VERSION "HNNBNNNYNNNNNNNNNNNNNNNNNNNNNNNNNNNNNNNNNN/4/%%%/4/'%**4NNN///"

NS_ :

BS_ :

BU_:  Airbag BAP_Tester ICAS1_Gateway ICAS1_KommunikationsServer LE1 LE2 Motor_BEV Schaltbetaetigung

BO_ 514 Daempfer_03: 32 ICAS1_Gateway
 SG_ DR_Aufbaubeschleunigung_HR  : 12|10@1+ (0.032700,-15.696000) [-15.696000|15.696000] "Unit_MeterPerSeconSquar" Motor_BEV
 SG_ DR_Aufbaubeschleunigung_VR  : 22|10@1+ (0.032700,-15.696000) [-15.696000|15.696000] "Unit_MeterPerSeconSquar" Motor_BEV
 SG_ DR_Aufbaubeschleunigung_VL  : 32|10@1+ (0.032700,-15.696000) [-15.696000|15.696000] "Unit_MeterPerSeconSquar" Motor_BEV
 SG_ DR_Aufbaubeschleunigung_HL  : 42|10@1+ (0.032700,-15.696000) [-15.696000|15.696000] "Unit_MeterPerSeconSquar" Motor_BEV
 SG_ DR_Funktionsstatus  : 52|2@1+ (1.000000,0.000000) [0.000000|3.000000] "" Vector__XXX
 SG_ DR_Drehwinkelsensortausch_VL  : 72|2@1+ (1.000000,0.000000) [1.000000|3.000000] "" Vector__XXX
 SG_ DR_Drehwinkelsensortausch_VR  : 74|2@1+ (1.000000,0.000000) [1.000000|3.000000] "" Vector__XXX
 SG_ DR_Drehwinkelsensortausch_HL  : 76|2@1+ (1.000000,0.000000) [1.000000|3.000000] "" Vector__XXX
 SG_ DR_Drehwinkelsensortausch_HR  : 78|2@1+ (1.000000,0.000000) [1.000000|3.000000] "" Vector__XXX
 SG_ DR_Drehwinkel_VL  : 80|12@1+ (0.088000,0.000000) [0.000000|359.920000] "" Vector__XXX
 SG_ DR_Drehwinkel_VR  : 92|12@1+ (0.088000,0.000000) [0.000000|359.920000] "" Vector__XXX
 SG_ DR_Drehwinkel_HL  : 104|12@1+ (0.088000,0.000000) [0.000000|359.920000] "" Vector__XXX
 SG_ DR_Drehwinkel_HR  : 116|12@1+ (0.088000,0.000000) [0.000000|359.920000] "" Vector__XXX

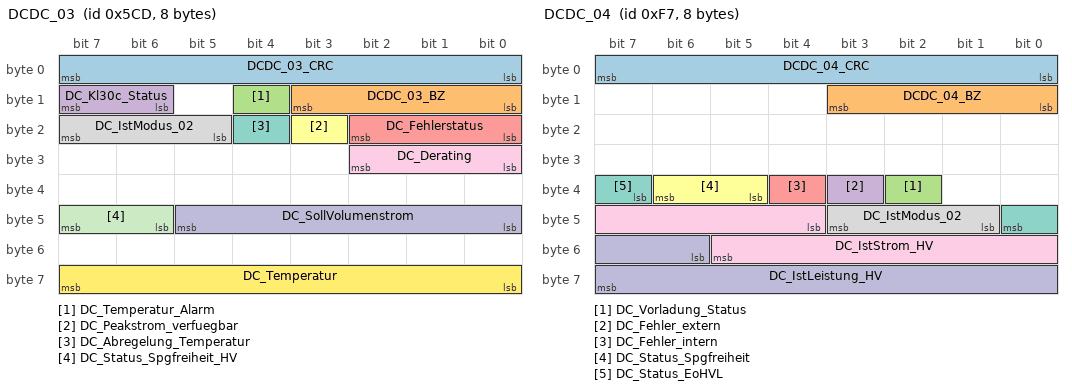
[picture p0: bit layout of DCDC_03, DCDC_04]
BO_ 1485 DCDC_03: 8 ICAS1_Gateway
 SG_ DCDC_03_CRC  : 0|8@1+ (1.000000,0.000000) [0.000000|255.000000] "" Motor_BEV
 SG_ DCDC_03_BZ  : 8|4@1+ (1.000000,0.000000) [0.000000|15.000000] "" Motor_BEV
 SG_ DC_Temperatur_Alarm  : 12|1@1+ (1.000000,0.000000) [0.000000|1.000000] "" Vector__XXX
 SG_ DC_Kl30c_Status  : 14|2@1+ (1.000000,0.000000) [0.000000|3.000000] "" Motor_BEV
 SG_ DC_Fehlerstatus  : 16|3@1+ (1.000000,0.000000) [0.000000|7.000000] "" Vector__XXX
 SG_ DC_Peakstrom_verfuegbar  : 19|1@1+ (1.000000,0.000000) [0.000000|1.000000] "" Vector__XXX
 SG_ DC_Abregelung_Temperatur  : 20|1@1+ (1.000000,0.000000) [0.000000|1.000000] "" Vector__XXX
 SG_ DC_IstModus_02  : 21|3@1+ (1.000000,0.000000) [0.000000|7.000000] "" Vector__XXX
 SG_ DC_Derating  : 24|3@1+ (1.000000,0.000000) [0.000000|7.000000] "" Vector__XXX
 SG_ DC_SollVolumenstrom  : 40|6@1+ (0.500000,0.000000) [0.000000|30.500000] "Unit_LiterPerMinut" Motor_BEV
 SG_ DC_Status_Spgfreiheit_HV  : 46|2@1+ (1.000000,0.000000) [0.000000|3.000000] "" Vector__XXX
 SG_ DC_Temperatur  : 56|8@1+ (1.000000,-40.000000) [-40.000000|213.000000] "Unit_DegreCelsi" Motor_BEV

BO_ 247 DCDC_04: 8 ICAS1_Gateway
 SG_ DCDC_04_CRC  : 0|8@1+ (1.000000,0.000000) [0.000000|255.000000] "" Vector__XXX
 SG_ DCDC_04_BZ  : 8|4@1+ (1.000000,0.000000) [0.000000|15.000000] "" Vector__XXX
 SG_ DC_Vorladung_Status  : 34|1@1+ (1.000000,0.000000) [0.000000|1.000000] "" Motor_BEV
 SG_ DC_Fehler_extern  : 35|1@1+ (1.000000,0.000000) [0.000000|1.000000] "" Motor_BEV
 SG_ DC_Fehler_intern  : 36|1@1+ (1.000000,0.000000) [0.000000|1.000000] "" Motor_BEV
 SG_ DC_Status_Spgfreiheit  : 37|2@1+ (1.000000,0.000000) [0.000000|3.000000] "" Motor_BEV
 SG_ DC_Status_EoHVL  : 39|2@1+ (1.000000,0.000000) [0.000000|3.000000] "" Motor_BEV
 SG_ DC_IstModus_02  : 41|3@1+ (1.000000,0.000000) [0.000000|7.000000] "" Motor_BEV
 SG_ DC_IstStrom_HV  : 44|10@1+ (0.100000,-51.100000) [-51.100000|51.000000] "Unit_Amper" Motor_BEV
 SG_ DC_IstLeistung_HV  : 54|10@1+ (10.000000,-4000.000000) [-4000.000000|6210.000000] "Unit_Watt" Motor_BEV

BO_ 2617027088 DEV_Airbag_ASM_01: 8 Airbag
 SG_ DEV_Airbag_ASM_01_Data  : 0|64@1+ (1.000000,0.000000) [0.000000|18446744073709551616.000000] "" Vector__XXX

BO_ 2617027072 DEV_Airbag_Resp_00: 8 Airbag
 SG_ DEV_Airbag_Resp_00_Data  : 0|64@1+ (1.000000,0.000000) [0.000000|18446744073709551616.000000] "" Vector__XXX

BO_ 2617027073 DEV_Airbag_Resp_01: 8 Airbag
 SG_ DEV_Airbag_Resp_01_Data  : 0|64@1+ (1.000000,0.000000) [0.000000|18446744073709551616.000000] "" Vector__XXX

BO_ 2617027074 DEV_Airbag_Resp_02: 8 Airbag
 SG_ DEV_Airbag_Resp_02_Data  : 0|64@1+ (1.000000,0.000000) [0.000000|18446744073709551616.000000] "" Vector__XXX

BO_ 2617027075 DEV_Airbag_Resp_03: 8 Airbag
 SG_ DEV_Airbag_Resp_03_Data  : 0|64@1+ (1.000000,0.000000) [0.000000|18446744073709551616.000000] "" Vector__XXX

BO_ 2617027076 DEV_Airbag_Resp_04: 8 Airbag
 SG_ DEV_Airbag_Resp_04_Data  : 0|64@1+ (1.000000,0.000000) [0.000000|18446744073709551616.000000] "" Vector__XXX

BO_ 2617027077 DEV_Airbag_Resp_05: 8 Airbag
 SG_ DEV_Airbag_Resp_05_Data  : 0|64@1+ (1.000000,0.000000) [0.000000|18446744073709551616.000000] "" Vector__XXX

BO_ 2617027078 DEV_Airbag_Resp_06: 8 Airbag
 SG_ DEV_Airbag_Resp_06_Data  : 0|64@1+ (1.000000,0.000000) [0.000000|18446744073709551616.000000] "" Vector__XXX

BO_ 2617027079 DEV_Airbag_Resp_07: 8 Airbag
 SG_ DEV_Airbag_Resp_07_Data  : 0|64@1+ (1.000000,0.000000) [0.000000|18446744073709551616.000000] "" Vector__XXX

BO_ 2617027080 DEV_Airbag_Resp_08: 8 Airbag
 SG_ DEV_Airbag_Resp_08_Data  : 0|64@1+ (1.000000,0.000000) [0.000000|18446744073709551616.000000] "" Vector__XXX

BO_ 2617027081 DEV_Airbag_Resp_09: 8 Airbag
 SG_ DEV_Airbag_Resp_09_Data  : 0|64@1+ (1.000000,0.000000) [0.000000|18446744073709551616.000000] "" Vector__XXX

BO_ 2617027082 DEV_Airbag_Resp_10: 8 Airbag
 SG_ DEV_Airbag_Resp_10_Data  : 0|64@1+ (1.000000,0.000000) [0.000000|18446744073709551616.000000] "" Vector__XXX

BO_ 2617027083 DEV_Airbag_Resp_11: 8 Airbag
 SG_ DEV_Airbag_Resp_11_Data  : 0|64@1+ (1.000000,0.000000) [0.000000|18446744073709551616.000000] "" Vector__XXX

BO_ 2617154048 DEV_Waehlhebel_Resp_00: 8 Schaltbetaetigung
 SG_ DEV_Waehlhebel_Resp_00_Data  : 0|64@1+ (1.000000,0.000000) [0.000000|18446744073709551616.000000] "" Vector__XXX

BO_ 2617154049 DEV_Waehlhebel_Resp_01: 8 Schaltbetaetigung
 SG_ DEV_Waehlhebel_Resp_01_Data  : 0|64@1+ (1.000000,0.000000) [0.000000|18446744073709551616.000000] "" Vector__XXX

BO_ 2617154050 DEV_Waehlhebel_Resp_02: 8 Schaltbetaetigung
 SG_ DEV_Waehlhebel_Resp_02_Data  : 0|64@1+ (1.000000,0.000000) [0.000000|18446744073709551616.000000] "" Vector__XXX

BO_ 2617154051 DEV_Waehlhebel_Resp_03: 8 Schaltbetaetigung
 SG_ DEV_Waehlhebel_Resp_03_Data  : 0|64@1+ (1.000000,0.000000) [0.000000|18446744073709551616.000000] "" Vector__XXX

BO_ 2617154052 DEV_Waehlhebel_Resp_04: 8 Schaltbetaetigung
 SG_ DEV_Waehlhebel_Resp_04_Data  : 0|64@1+ (1.000000,0.000000) [0.000000|18446744073709551616.000000] "" Vector__XXX

BO_ 2617154053 DEV_Waehlhebel_Resp_05: 8 Schaltbetaetigung
 SG_ DEV_Waehlhebel_Resp_05_Data  : 0|64@1+ (1.000000,0.000000) [0.000000|18446744073709551616.000000] "" Vector__XXX

BO_ 2549876269 Diag_Waehlhebel_Req: 8 Motor_BEV
 SG_ Diag_Waehlhebel_Req_Data  : 0|64@1+ (1.000000,0.000000) [0.000000|18446744073709551616.000000] "" Schaltbetaetigung

BO_ 2550007341 Diag_Waehlhebel_Resp: 8 Schaltbetaetigung
 SG_ Diag_Waehlhebel_Resp_Data  : 0|64@1+ (1.000000,0.000000) [0.000000|18446744073709551616.000000] "" Motor_BEV

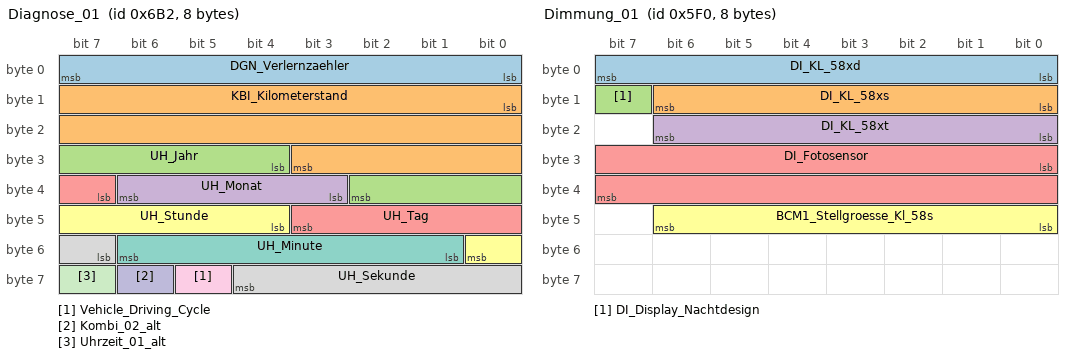
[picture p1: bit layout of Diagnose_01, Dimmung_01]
BO_ 1714 Diagnose_01: 8 ICAS1_Gateway
 SG_ DGN_Verlernzaehler  : 0|8@1+ (1.000000,0.000000) [0.000000|254.000000] "" Airbag LE1 LE2 Motor_BEV
 SG_ KBI_Kilometerstand  : 8|20@1+ (1.000000,0.000000) [0.000000|1048573.000000] "Unit_KiloMeter" Airbag LE1 LE2 Motor_BEV
 SG_ UH_Jahr  : 28|7@1+ (1.000000,2000.000000) [2000.000000|2127.000000] "Unit_Year" Airbag LE1 LE2 Motor_BEV
 SG_ UH_Monat  : 35|4@1+ (1.000000,0.000000) [1.000000|12.000000] "Unit_Month" Airbag LE1 LE2 Motor_BEV
 SG_ UH_Tag  : 39|5@1+ (1.000000,0.000000) [1.000000|31.000000] "Unit_Day" Airbag LE1 LE2 Motor_BEV
 SG_ UH_Stunde  : 44|5@1+ (1.000000,0.000000) [0.000000|23.000000] "Unit_Hours" Airbag LE1 LE2 Motor_BEV
 SG_ UH_Minute  : 49|6@1+ (1.000000,0.000000) [0.000000|59.000000] "Unit_Minut" Airbag LE1 LE2 Motor_BEV
 SG_ UH_Sekunde  : 55|6@1+ (1.000000,0.000000) [0.000000|59.000000] "Unit_Secon" Airbag LE1 LE2 Motor_BEV
 SG_ Vehicle_Driving_Cycle  : 61|1@1+ (1.000000,0.000000) [0.000000|1.000000] "" Airbag
 SG_ Kombi_02_alt  : 62|1@1+ (1.000000,0.000000) [0.000000|1.000000] "" Vector__XXX
 SG_ Uhrzeit_01_alt  : 63|1@1+ (1.000000,0.000000) [0.000000|1.000000] "" Vector__XXX

BO_ 851 DiETa_01: 8 ICAS1_Gateway
 SG_ DiETas_01_CRC  : 0|8@1+ (1.000000,0.000000) [0.000000|255.000000] "" Airbag
 SG_ DiETas_01_BZ  : 8|4@1+ (1.000000,0.000000) [0.000000|15.000000] "" Airbag
 SG_ DiETa_Reserve_Byte2_4  : 12|1@1+ (1.000000,0.000000) [0.000000|1.000000] "" Vector__XXX
 SG_ DiETa_Status  : 13|2@1+ (1.000000,0.000000) [0.000000|3.000000] "" Airbag
 SG_ DiETa_ResponseError  : 15|1@1+ (1.000000,0.000000) [0.000000|1.000000] "" Vector__XXX
 SG_ DiETa_Car  : 16|2@1+ (1.000000,0.000000) [0.000000|3.000000] "" Vector__XXX
 SG_ DiETa_Klima  : 18|2@1+ (1.000000,0.000000) [0.000000|3.000000] "" Vector__XXX
 SG_ DiETa_Mode  : 20|2@1+ (1.000000,0.000000) [0.000000|3.000000] "" Vector__XXX
 SG_ DiETa_Parken  : 22|2@1+ (1.000000,0.000000) [0.000000|3.000000] "" Vector__XXX
 SG_ DiETa_FSH_Taste  : 24|2@1+ (1.000000,0.000000) [0.000000|3.000000] "" Vector__XXX
 SG_ DiETa_HSH_Taste  : 26|2@1+ (1.000000,0.000000) [0.000000|3.000000] "" Vector__XXX
 SG_ DiETa_Warnblink_Taste  : 28|2@1+ (1.000000,0.000000) [0.000000|3.000000] "" Vector__XXX
 SG_ DiETa_FAS_Stufe  : 30|2@1+ (1.000000,0.000000) [0.000000|3.000000] "" Vector__XXX
 SG_ DiETa_PAO_ON_Status  : 32|2@1+ (1.000000,0.000000) [0.000000|3.000000] "" Airbag
 SG_ DiETa_PAO_OFF_Status  : 34|2@1+ (1.000000,0.000000) [0.000000|3.000000] "" Airbag
 SG_ DiETa_Defrost_Taste  : 36|2@1+ (1.000000,0.000000) [0.000000|3.000000] "" Vector__XXX
 SG_ DiETa_Reserve_Byte5_6  : 38|2@1+ (1.000000,0.000000) [0.000000|3.000000] "" Vector__XXX
 SG_ DiETa_Lock_Unlock_Taste  : 40|3@1+ (1.000000,0.000000) [0.000000|7.000000] "" Vector__XXX
 SG_ DiETa_Mode_roh  : 43|1@1+ (1.000000,0.000000) [0.000000|1.000000] "" Vector__XXX
 SG_ DiETa_Reserve_Byte6_3  : 44|4@1+ (1.000000,0.000000) [0.000000|15.000000] "" Vector__XXX
 SG_ DiETa_Reserve_Byte7  : 48|8@1+ (1.000000,0.000000) [0.000000|255.000000] "" Vector__XXX
 SG_ DiETa_Reserve_Byte8  : 56|8@1+ (1.000000,0.000000) [0.000000|255.000000] "" Vector__XXX

BO_ 1520 Dimmung_01: 8 ICAS1_Gateway
 SG_ DI_KL_58xd  : 0|8@1+ (1.000000,0.000000) [0.000000|253.000000] "" Airbag Schaltbetaetigung
 SG_ DI_KL_58xs  : 8|7@1+ (1.000000,0.000000) [0.000000|100.000000] "Unit_PerCent" Airbag
 SG_ DI_Display_Nachtdesign  : 15|1@1+ (1.000000,0.000000) [0.000000|1.000000] "" Vector__XXX
 SG_ DI_KL_58xt  : 16|7@1+ (1.000000,0.000000) [0.000000|100.000000] "Unit_PerCent" Airbag Schaltbetaetigung
 SG_ DI_Fotosensor  : 24|16@1+ (1.000000,0.000000) [0.000000|65535.000000] "" Vector__XXX
 SG_ BCM1_Stellgroesse_Kl_58s  : 40|7@1+ (1.000000,0.000000) [0.000000|100.000000] "" Vector__XXX

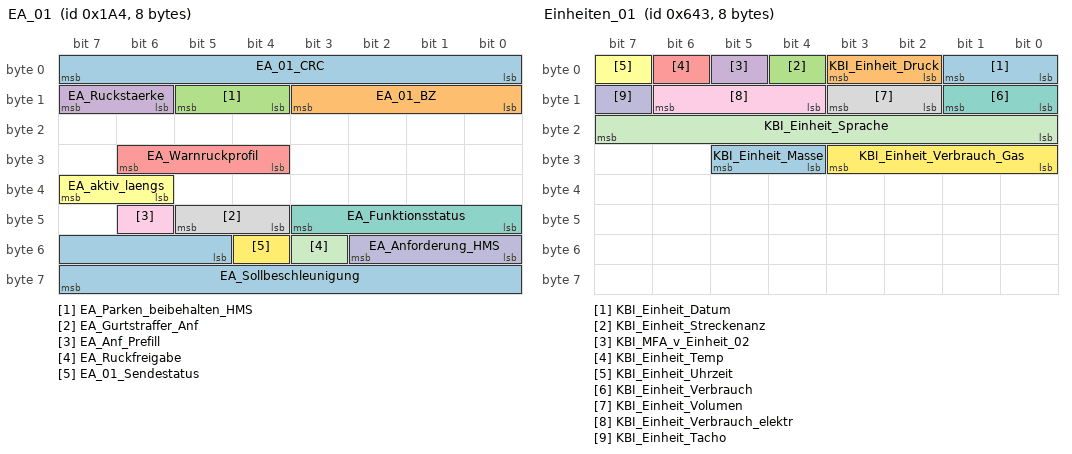
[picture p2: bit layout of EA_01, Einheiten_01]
BO_ 420 EA_01: 8 ICAS1_Gateway
 SG_ EA_01_CRC  : 0|8@1+ (1.000000,0.000000) [0.000000|255.000000] "" Motor_BEV
 SG_ EA_01_BZ  : 8|4@1+ (1.000000,0.000000) [0.000000|15.000000] "" Motor_BEV
 SG_ EA_Parken_beibehalten_HMS  : 12|2@1+ (1.000000,0.000000) [0.000000|3.000000] "" Vector__XXX
 SG_ EA_Ruckstaerke  : 14|2@1+ (1.000000,0.000000) [0.000000|3.000000] "" Vector__XXX
 SG_ EA_Warnruckprofil  : 28|3@1+ (1.000000,0.000000) [0.000000|7.000000] "" Vector__XXX
 SG_ EA_aktiv_laengs  : 38|2@1+ (1.000000,0.000000) [0.000000|3.000000] "" Motor_BEV
 SG_ EA_Funktionsstatus  : 40|4@1+ (1.000000,0.000000) [0.000000|15.000000] "" Motor_BEV
 SG_ EA_Gurtstraffer_Anf  : 44|2@1+ (1.000000,0.000000) [0.000000|3.000000] "" Airbag
 SG_ EA_Anf_Prefill  : 46|1@1+ (1.000000,0.000000) [0.000000|1.000000] "" Vector__XXX
 SG_ EA_Anforderung_HMS  : 48|3@1+ (1.000000,0.000000) [0.000000|7.000000] "" Vector__XXX
 SG_ EA_Ruckfreigabe  : 51|1@1+ (1.000000,0.000000) [0.000000|1.000000] "" Vector__XXX
 SG_ EA_01_Sendestatus  : 52|1@1+ (1.000000,0.000000) [0.000000|1.000000] "" Vector__XXX
 SG_ EA_Sollbeschleunigung  : 53|11@1+ (0.005000,-7.220000) [-7.220000|3.005000] "Unit_MeterPerSeconSquar" Motor_BEV

BO_ 374 EBKV_03: 8 ICAS1_Gateway
 SG_ EBKV_03_CRC  : 0|8@1+ (1.000000,0.000000) [0.000000|255.000000] "" Vector__XXX
 SG_ EBKV_03_BZ  : 8|4@1+ (1.000000,0.000000) [0.000000|15.000000] "" Vector__XXX
 SG_ EBKV_Activate_Fallback_ESP  : 12|1@1+ (1.000000,0.000000) [0.000000|1.000000] "" Vector__XXX
 SG_ EBKV_Restdruckabsenkung  : 13|3@1+ (1.000000,0.000000) [0.000000|7.000000] "" Vector__XXX
 SG_ EBKV_Status_02  : 16|4@1+ (1.000000,0.000000) [0.000000|15.000000] "" Vector__XXX
 SG_ EBKV_Diagnose  : 20|1@1+ (1.000000,0.000000) [0.000000|1.000000] "" Vector__XXX
 SG_ EBKV_Fahrer_bremst  : 21|1@1+ (1.000000,0.000000) [0.000000|1.000000] "" Motor_BEV
 SG_ EBKV_QBit_Fahrer_bremst  : 22|1@1+ (1.000000,0.000000) [0.000000|1.000000] "" Motor_BEV
 SG_ EBKV_Fahrer_bremst_deutlich  : 23|1@1+ (1.000000,0.000000) [0.000000|1.000000] "" Vector__XXX
 SG_ EBKV_OBD_Status  : 24|1@1+ (1.000000,0.000000) [0.000000|1.000000] "" Motor_BEV
 SG_ EBKV_VMM_Sek_Notstopp_Status  : 25|3@1+ (1.000000,0.000000) [0.000000|7.000000] "" Vector__XXX
 SG_ EBKV_Anforderung_HMS  : 28|3@1+ (1.000000,0.000000) [0.000000|7.000000] "" Vector__XXX
 SG_ SBS_Anforderung_GE  : 31|1@1+ (1.000000,0.000000) [0.000000|1.000000] "" Vector__XXX
 SG_ EPB_Status_ext  : 32|3@1+ (1.000000,0.000000) [0.000000|7.000000] "" Motor_BEV
 SG_ EBKV_Bremspedalweg  : 40|8@1+ (0.400000,-0.400000) [0.000000|101.200000] "Unit_PerCent" Motor_BEV
 SG_ EBKV_Kraftblending_Reserve  : 48|8@1+ (0.500000,0.000000) [0.000000|125.000000] "Unit_Bar" Vector__XXX
 SG_ EBKV_Aussteuerdruck  : 56|8@1+ (1.000000,0.000000) [0.000000|250.000000] "Unit_Bar" Vector__XXX

BO_ 1603 Einheiten_01: 8 ICAS1_KommunikationsServer
 SG_ KBI_Einheit_Datum  : 0|2@1+ (1.000000,0.000000) [0.000000|3.000000] "" Vector__XXX
 SG_ KBI_Einheit_Druck  : 2|2@1+ (1.000000,0.000000) [0.000000|3.000000] "" Vector__XXX
 SG_ KBI_Einheit_Streckenanz  : 4|1@1+ (1.000000,0.000000) [0.000000|1.000000] "" Vector__XXX
 SG_ KBI_MFA_v_Einheit_02  : 5|1@1+ (1.000000,0.000000) [0.000000|1.000000] "" Motor_BEV
 SG_ KBI_Einheit_Temp  : 6|1@1+ (1.000000,0.000000) [0.000000|1.000000] "" Vector__XXX
 SG_ KBI_Einheit_Uhrzeit  : 7|1@1+ (1.000000,0.000000) [0.000000|1.000000] "" Vector__XXX
 SG_ KBI_Einheit_Verbrauch  : 8|2@1+ (1.000000,0.000000) [0.000000|3.000000] "" Vector__XXX
 SG_ KBI_Einheit_Volumen  : 10|2@1+ (1.000000,0.000000) [0.000000|3.000000] "" Vector__XXX
 SG_ KBI_Einheit_Verbrauch_elektr  : 12|3@1+ (1.000000,0.000000) [0.000000|7.000000] "" Vector__XXX
 SG_ KBI_Einheit_Tacho  : 15|1@1+ (1.000000,0.000000) [0.000000|1.000000] "" Motor_BEV
 SG_ KBI_Einheit_Sprache  : 16|8@1+ (1.000000,0.000000) [0.000000|255.000000] "" Vector__XXX
 SG_ KBI_Einheit_Verbrauch_Gas  : 24|4@1+ (1.000000,0.000000) [0.000000|15.000000] "" Vector__XXX
 SG_ KBI_Einheit_Masse  : 28|2@1+ (1.000000,0.000000) [0.000000|3.000000] "" Vector__XXX

BO_ 192 EM1_01: 32 LE1
 SG_ EM1_01_CRC  : 0|8@1+ (1.000000,0.000000) [0.000000|255.000000] "" ICAS1_Gateway Motor_BEV
 SG_ EM1_01_BZ  : 8|4@1+ (1.000000,0.000000) [0.000000|15.000000] "" ICAS1_Gateway Motor_BEV
 SG_ EM1_Istmodus  : 12|4@1+ (1.000000,0.000000) [0.000000|15.000000] "" ICAS1_Gateway Motor_BEV
 SG_ EM1_IstMoment  : 16|12@1+ (0.500000,-1023.000000) [-1023.000000|1023.500000] "Unit_NewtoMeter" ICAS1_Gateway Motor_BEV
 SG_ EM1_Moment_AR_Eingriff  : 28|12@1+ (0.500000,-1023.000000) [-1023.000000|1023.500000] "Unit_NewtoMeter" ICAS1_Gateway Motor_BEV
 SG_ EM1_IstDrehzahl  : 40|15@1+ (1.000000,-10000.000000) [-10000.000000|22765.000000] "Unit_MinutInver" ICAS1_Gateway Motor_BEV
 SG_ EM1_AR_aktiv  : 55|1@1+ (1.000000,0.000000) [0.000000|1.000000] "" ICAS1_Gateway Motor_BEV
 SG_ EM1_IstSpannung  : 56|12@1+ (0.250000,0.000000) [0.000000|1023.250000] "Unit_Volt" ICAS1_Gateway Motor_BEV
 SG_ EM1_Strom_HV  : 68|12@1+ (0.500000,-1023.000000) [-1023.000000|1023.500000] "Unit_Amper" ICAS1_Gateway Motor_BEV
 SG_ EM1_Max_Moment  : 80|11@1+ (1.000000,-1023.000000) [-1023.000000|1022.000000] "Unit_NewtoMeter" ICAS1_Gateway Motor_BEV
 SG_ EM1_ErwGrenzen_aktiv  : 91|1@1+ (1.000000,0.000000) [0.000000|1.000000] "" ICAS1_Gateway Motor_BEV
 SG_ EM1_Min_Moment  : 92|11@1+ (1.000000,-1023.000000) [-1023.000000|1022.000000] "Unit_NewtoMeter" ICAS1_Gateway Motor_BEV
 SG_ EM1_Fehler_ElAntriebAbschaltung  : 103|1@1+ (1.000000,0.000000) [0.000000|1.000000] "" ICAS1_Gateway Motor_BEV
 SG_ EM1_Max_Moment_Lim  : 104|11@1+ (1.000000,-1023.000000) [-1023.000000|1022.000000] "Unit_NewtoMeter" ICAS1_Gateway Motor_BEV
 SG_ EM1_Fehler_Notabschaltung  : 115|1@1+ (1.000000,0.000000) [0.000000|1.000000] "" ICAS1_Gateway Motor_BEV
 SG_ EM1_Min_Moment_Lim  : 116|11@1+ (1.000000,-1023.000000) [-1023.000000|1022.000000] "Unit_NewtoMeter" ICAS1_Gateway Motor_BEV
 SG_ EM1_Status_DrzEingriff  : 127|2@1+ (1.000000,0.000000) [0.000000|3.000000] "" ICAS1_Gateway Motor_BEV
 SG_ EM1_Mom_DrzEingriff  : 129|11@1+ (1.000000,-1023.000000) [-1023.000000|1022.000000] "Unit_NewtoMeter" ICAS1_Gateway Motor_BEV

BO_ 2463978673 EM1_02: 32 LE1
 SG_ EM1_Status_Spgfreiheit  : 12|2@1+ (1.000000,0.000000) [0.000000|3.000000] "" Motor_BEV
 SG_ EM1_Status_EoHVL  : 14|2@1+ (1.000000,0.000000) [0.000000|3.000000] "" Motor_BEV
 SG_ EM1_Max_LeistungMech_Sockel  : 16|13@1+ (200.000000,-819000.000000) [-819000.000000|818800.000000] "Unit_Watt" Vector__XXX
 SG_ EM1_Max_Moment_Sockel  : 29|11@1+ (1.000000,-1023.000000) [-1023.000000|1022.000000] "Unit_NewtoMeter" Vector__XXX
 SG_ EM1_Min_LeistungMech_Sockel  : 40|13@1+ (200.000000,-819000.000000) [-819000.000000|818800.000000] "Unit_Watt" Vector__XXX
 SG_ EM1_Min_Moment_Sockel  : 53|11@1+ (1.000000,-1023.000000) [-1023.000000|1022.000000] "Unit_NewtoMeter" Vector__XXX
 SG_ EM1_PerfInd_MaxLeistung  : 64|10@1+ (0.200000,0.000000) [0.000000|200.000000] "Unit_PerCent" Motor_BEV
 SG_ EM1_PerfInd_MaxMoment  : 74|10@1+ (0.200000,0.000000) [0.000000|200.000000] "Unit_PerCent" Motor_BEV
 SG_ EM1_AnlernenElMotor_Anf  : 84|1@1+ (1.000000,0.000000) [0.000000|1.000000] "" Motor_BEV
 SG_ EM1_OBD_Lampe_Anf  : 85|1@1+ (1.000000,0.000000) [0.000000|1.000000] "" Motor_BEV
 SG_ EM1_Generator_Moment  : 86|10@1+ (1.000000,0.000000) [0.000000|1021.000000] "Unit_NewtoMeter" Motor_BEV
 SG_ EM1_PerfInd_Temperatur  : 96|8@1+ (0.800000,0.000000) [0.000000|200.000000] "Unit_PerCent" Motor_BEV
 SG_ EM1_MaxZul_Drehzahl  : 104|8@1+ (80.000000,0.000000) [0.000000|20240.000000] "Unit_RevPerMinute" Motor_BEV
 SG_ EM1_Min_Moment_Gesamt  : 112|11@1+ (1.000000,-1023.000000) [-1023.000000|1022.000000] "Unit_NewtoMeter" Motor_BEV
 SG_ EM1_Fehlerlampe_Anf  : 123|1@1+ (1.000000,0.000000) [0.000000|1.000000] "" Motor_BEV
 SG_ EM1_Max_Moment_Gesamt  : 124|11@1+ (1.000000,-1023.000000) [-1023.000000|1022.000000] "Unit_NewtoMeter" Motor_BEV
 SG_ EM1_Warnlampe_Anf  : 135|1@1+ (1.000000,0.000000) [0.000000|1.000000] "" Motor_BEV
 SG_ EM1_Rekuperation  : 136|15@1+ (10.000000,0.000000) [0.000000|327670.000000] "Unit_WattSecond" Motor_BEV
 SG_ EM1_Rekuperation_Ueberlauf  : 151|1@1+ (1.000000,0.000000) [0.000000|1.000000] "" Motor_BEV
 SG_ EM1_Verbrauch  : 152|15@1+ (10.000000,0.000000) [0.000000|327670.000000] "Unit_WattSecond" Motor_BEV
 SG_ EM1_Verbrauch_Ueberlauf  : 167|1@1+ (1.000000,0.000000) [0.000000|1.000000] "" Motor_BEV
 SG_ EM1_Fehler_AE  : 168|1@1+ (1.000000,0.000000) [0.000000|1.000000] "" Motor_BEV
 SG_ EM1_Fehler_Leistungsred  : 169|1@1+ (1.000000,0.000000) [0.000000|1.000000] "" Motor_BEV
 SG_ EM1_Fehler_ElAntriebFreilauf  : 170|1@1+ (1.000000,0.000000) [0.000000|1.000000] "" Motor_BEV
 SG_ EM1_PWR_SollVolumenstrom  : 171|6@1+ (0.500000,0.000000) [0.000000|30.500000] "Unit_LiterPerMinut" Motor_BEV

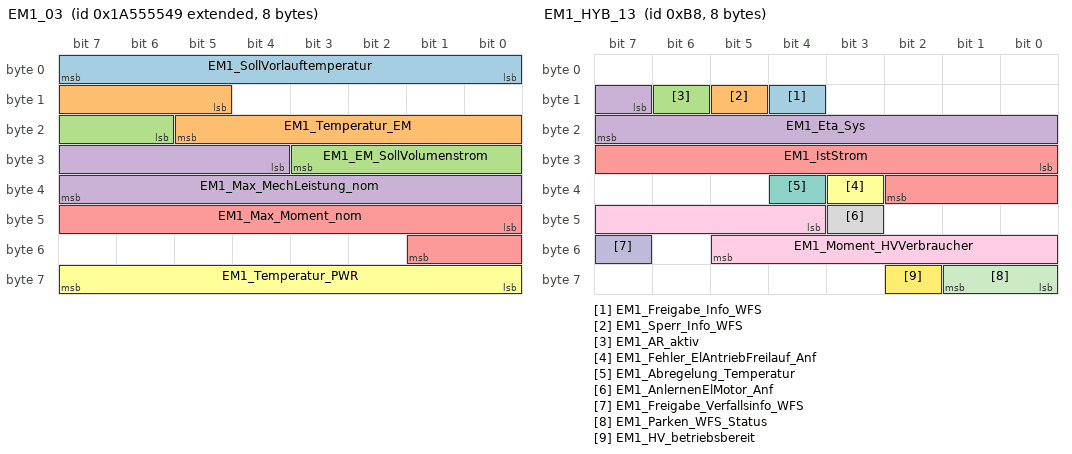
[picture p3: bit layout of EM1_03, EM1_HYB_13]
BO_ 2589283657 EM1_03: 8 LE1
 SG_ EM1_SollVorlauftemperatur  : 0|8@1+ (0.500000,-40.000000) [-40.000000|86.500000] "Unit_DegreCelsi" Motor_BEV
 SG_ EM1_Temperatur_EM  : 13|9@1+ (1.000000,-40.000000) [-40.000000|469.000000] "Unit_DegreCelsi" ICAS1_Gateway Motor_BEV
 SG_ EM1_EM_SollVolumenstrom  : 22|6@1+ (0.500000,0.000000) [0.000000|30.500000] "Unit_LiterPerMinut" Motor_BEV
 SG_ EM1_Max_MechLeistung_nom  : 28|12@1+ (200.000000,0.000000) [0.000000|818600.000000] "Unit_Watt" Motor_BEV
 SG_ EM1_Max_Moment_nom  : 40|10@1+ (1.000000,0.000000) [0.000000|1021.000000] "Unit_NewtoMeter" Motor_BEV
 SG_ EM1_Temperatur_PWR  : 56|8@1+ (1.000000,-40.000000) [-40.000000|213.000000] "Unit_DegreCelsi" ICAS1_Gateway Motor_BEV

BO_ 184 EM1_HYB_13: 8 LE1
 SG_ EM1_Freigabe_Info_WFS  : 12|1@1+ (1.000000,0.000000) [0.000000|1.000000] "" ICAS1_Gateway Motor_BEV
 SG_ EM1_Sperr_Info_WFS  : 13|1@1+ (1.000000,0.000000) [0.000000|1.000000] "" ICAS1_Gateway Motor_BEV
 SG_ EM1_AR_aktiv  : 14|1@1+ (1.000000,0.000000) [0.000000|1.000000] "" ICAS1_Gateway
 SG_ EM1_Eta_Sys  : 15|9@1+ (0.200000,0.000000) [0.000000|101.800000] "Unit_PerCent" ICAS1_Gateway
 SG_ EM1_IstStrom  : 24|11@1+ (1.000000,-1023.000000) [-1023.000000|1022.000000] "Unit_Amper" ICAS1_Gateway
 SG_ EM1_Fehler_ElAntriebFreilauf_Anf  : 35|1@1+ (1.000000,0.000000) [0.000000|1.000000] "" ICAS1_Gateway
 SG_ EM1_Abregelung_Temperatur  : 36|1@1+ (1.000000,0.000000) [0.000000|1.000000] "" ICAS1_Gateway
 SG_ EM1_AnlernenElMotor_Anf  : 43|1@1+ (1.000000,0.000000) [0.000000|1.000000] "" ICAS1_Gateway
 SG_ EM1_Moment_HVVerbraucher  : 44|10@1+ (1.000000,-511.000000) [-511.000000|511.000000] "Unit_NewtoMeter" ICAS1_Gateway
 SG_ EM1_Freigabe_Verfallsinfo_WFS  : 55|1@1+ (1.000000,0.000000) [0.000000|1.000000] "" ICAS1_Gateway Motor_BEV
 SG_ EM1_Parken_WFS_Status  : 56|2@1+ (1.000000,0.000000) [0.000000|3.000000] "" ICAS1_Gateway
 SG_ EM1_HV_betriebsbereit  : 58|1@1+ (1.000000,0.000000) [0.000000|1.000000] "" ICAS1_Gateway

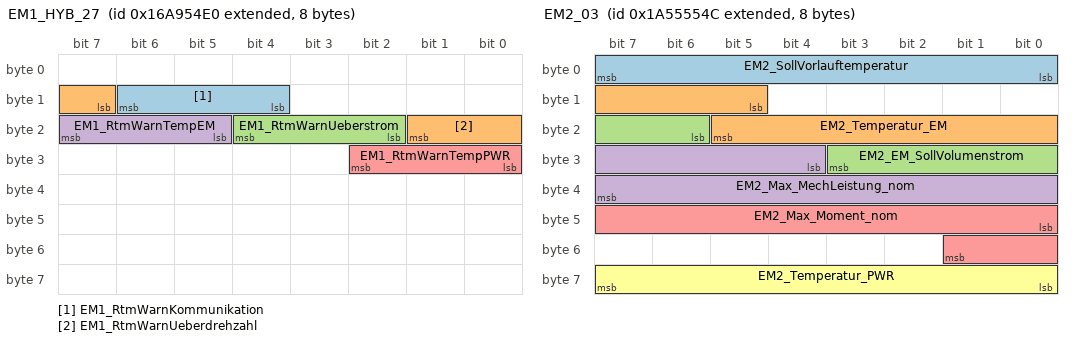
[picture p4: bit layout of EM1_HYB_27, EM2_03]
BO_ 2527679712 EM1_HYB_27: 8 LE1
 SG_ EM1_RtmWarnKommunikation  : 12|3@1+ (1.000000,0.000000) [0.000000|7.000000] "" Vector__XXX
 SG_ EM1_RtmWarnUeberdrehzahl  : 15|3@1+ (1.000000,0.000000) [0.000000|7.000000] "" ICAS1_Gateway
 SG_ EM1_RtmWarnUeberstrom  : 18|3@1+ (1.000000,0.000000) [0.000000|7.000000] "" ICAS1_Gateway
 SG_ EM1_RtmWarnTempEM  : 21|3@1+ (1.000000,0.000000) [0.000000|7.000000] "" ICAS1_Gateway
 SG_ EM1_RtmWarnTempPWR  : 24|3@1+ (1.000000,0.000000) [0.000000|7.000000] "" ICAS1_Gateway

BO_ 193 EM2_01: 32 LE2
 SG_ EM2_01_CRC  : 0|8@1+ (1.000000,0.000000) [0.000000|255.000000] "" Motor_BEV
 SG_ EM2_01_BZ  : 8|4@1+ (1.000000,0.000000) [0.000000|15.000000] "" Motor_BEV
 SG_ EM2_Istmodus  : 12|4@1+ (1.000000,0.000000) [0.000000|15.000000] "" ICAS1_Gateway Motor_BEV
 SG_ EM2_IstMoment  : 16|12@1+ (0.500000,-1023.000000) [-1023.000000|1023.500000] "Unit_NewtoMeter" ICAS1_Gateway Motor_BEV
 SG_ EM2_Moment_AR_Eingriff  : 28|12@1+ (0.500000,-1023.000000) [-1023.000000|1023.500000] "Unit_NewtoMeter" Motor_BEV
 SG_ EM2_IstDrehzahl  : 40|15@1+ (1.000000,-10000.000000) [-10000.000000|22765.000000] "Unit_MinutInver" ICAS1_Gateway Motor_BEV
 SG_ EM2_AR_aktiv  : 55|1@1+ (1.000000,0.000000) [0.000000|1.000000] "" Motor_BEV
 SG_ EM2_IstSpannung  : 56|12@1+ (0.250000,0.000000) [0.000000|1023.250000] "Unit_Volt" ICAS1_Gateway Motor_BEV
 SG_ EM2_Strom_HV  : 68|12@1+ (0.500000,-1023.000000) [-1023.000000|1023.500000] "Unit_Amper" ICAS1_Gateway Motor_BEV
 SG_ EM2_Max_Moment  : 80|11@1+ (1.000000,-1023.000000) [-1023.000000|1022.000000] "Unit_NewtoMeter" Motor_BEV
 SG_ EM2_ErwGrenzen_aktiv  : 91|1@1+ (1.000000,0.000000) [0.000000|1.000000] "" Motor_BEV
 SG_ EM2_Min_Moment  : 92|11@1+ (1.000000,-1023.000000) [-1023.000000|1022.000000] "Unit_NewtoMeter" Motor_BEV
 SG_ EM2_Fehler_ElAntriebAbschaltung  : 103|1@1+ (1.000000,0.000000) [0.000000|1.000000] "" Motor_BEV
 SG_ EM2_Max_Moment_Lim  : 104|11@1+ (1.000000,-1023.000000) [-1023.000000|1022.000000] "Unit_NewtoMeter" Motor_BEV
 SG_ EM2_Fehler_Notabschaltung  : 115|1@1+ (1.000000,0.000000) [0.000000|1.000000] "" ICAS1_Gateway Motor_BEV
 SG_ EM2_Min_Moment_Lim  : 116|11@1+ (1.000000,-1023.000000) [-1023.000000|1022.000000] "Unit_NewtoMeter" Motor_BEV
 SG_ EM2_Status_DrzEingriff  : 127|2@1+ (1.000000,0.000000) [0.000000|3.000000] "" ICAS1_Gateway Motor_BEV
 SG_ EM2_Mom_DrzEingriff  : 129|11@1+ (1.000000,-1023.000000) [-1023.000000|1022.000000] "Unit_NewtoMeter" Motor_BEV

BO_ 2463978674 EM2_02: 32 LE2
 SG_ EM2_Status_Spgfreiheit  : 12|2@1+ (1.000000,0.000000) [0.000000|3.000000] "" Motor_BEV
 SG_ EM2_Status_EoHVL  : 14|2@1+ (1.000000,0.000000) [0.000000|3.000000] "" Motor_BEV
 SG_ EM2_Max_LeistungMech_Sockel  : 16|13@1+ (200.000000,-819000.000000) [-819000.000000|818800.000000] "Unit_Watt" Vector__XXX
 SG_ EM2_Max_Moment_Sockel  : 29|11@1+ (1.000000,-1023.000000) [-1023.000000|1022.000000] "Unit_NewtoMeter" Vector__XXX
 SG_ EM2_Min_LeistungMech_Sockel  : 40|13@1+ (200.000000,-819000.000000) [-819000.000000|818800.000000] "Unit_Watt" Vector__XXX
 SG_ EM2_Min_Moment_Sockel  : 53|11@1+ (1.000000,-1023.000000) [-1023.000000|1022.000000] "Unit_NewtoMeter" Vector__XXX
 SG_ EM2_PerfInd_MaxLeistung  : 64|10@1+ (0.200000,0.000000) [0.000000|200.000000] "Unit_PerCent" Motor_BEV
 SG_ EM2_PerfInd_MaxMoment  : 74|10@1+ (0.200000,0.000000) [0.000000|200.000000] "Unit_PerCent" Motor_BEV
 SG_ EM2_AnlernenElMotor_Anf  : 84|1@1+ (1.000000,0.000000) [0.000000|1.000000] "" Motor_BEV
 SG_ EM2_OBD_Lampe_Anf  : 85|1@1+ (1.000000,0.000000) [0.000000|1.000000] "" Motor_BEV
 SG_ EM2_Generator_Moment  : 86|10@1+ (1.000000,0.000000) [0.000000|1021.000000] "Unit_NewtoMeter" Motor_BEV
 SG_ EM2_PerfInd_Temperatur  : 96|8@1+ (0.800000,0.000000) [0.000000|200.000000] "Unit_PerCent" Motor_BEV
 SG_ EM2_MaxZul_Drehzahl  : 104|8@1+ (80.000000,0.000000) [0.000000|20240.000000] "Unit_RevPerMinute" Motor_BEV
 SG_ EM2_Min_Moment_Gesamt  : 112|11@1+ (1.000000,-1023.000000) [-1023.000000|1022.000000] "Unit_NewtoMeter" Motor_BEV
 SG_ EM2_Fehlerlampe_Anf  : 123|1@1+ (1.000000,0.000000) [0.000000|1.000000] "" Motor_BEV
 SG_ EM2_Max_Moment_Gesamt  : 124|11@1+ (1.000000,-1023.000000) [-1023.000000|1022.000000] "Unit_NewtoMeter" Motor_BEV
 SG_ EM2_Warnlampe_Anf  : 135|1@1+ (1.000000,0.000000) [0.000000|1.000000] "" Motor_BEV
 SG_ EM2_Rekuperation  : 136|15@1+ (10.000000,0.000000) [0.000000|327670.000000] "Unit_WattSecond" Motor_BEV
 SG_ EM2_Rekuperation_Ueberlauf  : 151|1@1+ (1.000000,0.000000) [0.000000|1.000000] "" Motor_BEV
 SG_ EM2_Verbrauch  : 152|15@1+ (10.000000,0.000000) [0.000000|327670.000000] "Unit_WattSecond" Motor_BEV
 SG_ EM2_Verbrauch_Ueberlauf  : 167|1@1+ (1.000000,0.000000) [0.000000|1.000000] "" Motor_BEV
 SG_ EM2_Fehler_AE  : 168|1@1+ (1.000000,0.000000) [0.000000|1.000000] "" Motor_BEV
 SG_ EM2_Fehler_Leistungsred  : 169|1@1+ (1.000000,0.000000) [0.000000|1.000000] "" Motor_BEV
 SG_ EM2_Fehler_ElAntriebFreilauf  : 170|1@1+ (1.000000,0.000000) [0.000000|1.000000] "" Motor_BEV
 SG_ EM2_PWR_SollVolumenstrom  : 171|6@1+ (0.500000,0.000000) [0.000000|30.500000] "Unit_LiterPerMinut" Motor_BEV

BO_ 2589283660 EM2_03: 8 LE2
 SG_ EM2_SollVorlauftemperatur  : 0|8@1+ (0.500000,-40.000000) [-40.000000|86.500000] "Unit_DegreCelsi" Motor_BEV
 SG_ EM2_Temperatur_EM  : 13|9@1+ (1.000000,-40.000000) [-40.000000|469.000000] "Unit_DegreCelsi" ICAS1_Gateway Motor_BEV
 SG_ EM2_EM_SollVolumenstrom  : 22|6@1+ (0.500000,0.000000) [0.000000|30.500000] "Unit_LiterPerMinut" Motor_BEV
 SG_ EM2_Max_MechLeistung_nom  : 28|12@1+ (200.000000,0.000000) [0.000000|818600.000000] "Unit_Watt" Motor_BEV
 SG_ EM2_Max_Moment_nom  : 40|10@1+ (1.000000,0.000000) [0.000000|1021.000000] "Unit_NewtoMeter" Motor_BEV
 SG_ EM2_Temperatur_PWR  : 56|8@1+ (1.000000,-40.000000) [-40.000000|213.000000] "Unit_DegreCelsi" ICAS1_Gateway Motor_BEV

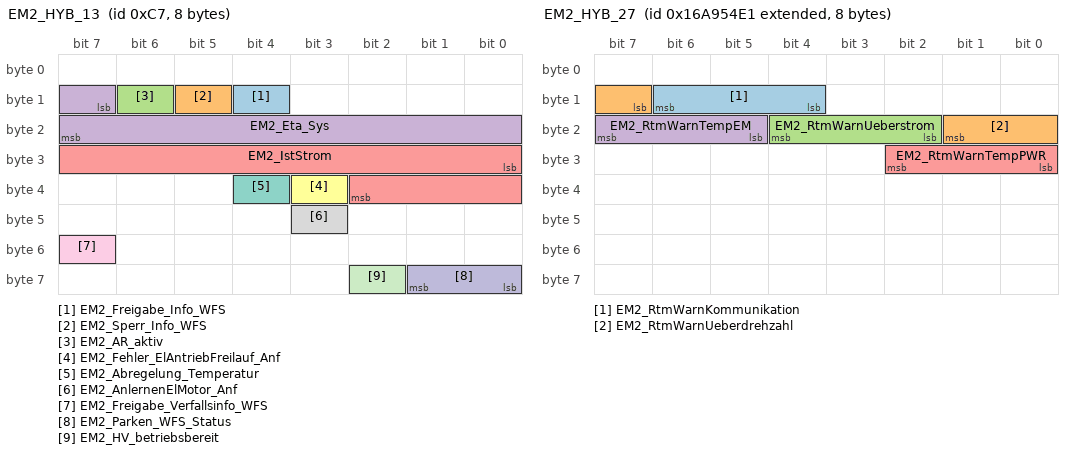
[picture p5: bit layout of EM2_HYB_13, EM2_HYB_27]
BO_ 199 EM2_HYB_13: 8 LE2
 SG_ EM2_Freigabe_Info_WFS  : 12|1@1+ (1.000000,0.000000) [0.000000|1.000000] "" ICAS1_Gateway Motor_BEV
 SG_ EM2_Sperr_Info_WFS  : 13|1@1+ (1.000000,0.000000) [0.000000|1.000000] "" ICAS1_Gateway Motor_BEV
 SG_ EM2_AR_aktiv  : 14|1@1+ (1.000000,0.000000) [0.000000|1.000000] "" ICAS1_Gateway
 SG_ EM2_Eta_Sys  : 15|9@1+ (0.200000,0.000000) [0.000000|101.800000] "Unit_PerCent" ICAS1_Gateway
 SG_ EM2_IstStrom  : 24|11@1+ (1.000000,-1023.000000) [-1023.000000|1022.000000] "Unit_Amper" ICAS1_Gateway
 SG_ EM2_Fehler_ElAntriebFreilauf_Anf  : 35|1@1+ (1.000000,0.000000) [0.000000|1.000000] "" ICAS1_Gateway
 SG_ EM2_Abregelung_Temperatur  : 36|1@1+ (1.000000,0.000000) [0.000000|1.000000] "" ICAS1_Gateway
 SG_ EM2_AnlernenElMotor_Anf  : 43|1@1+ (1.000000,0.000000) [0.000000|1.000000] "" ICAS1_Gateway
 SG_ EM2_Freigabe_Verfallsinfo_WFS  : 55|1@1+ (1.000000,0.000000) [0.000000|1.000000] "" ICAS1_Gateway Motor_BEV
 SG_ EM2_Parken_WFS_Status  : 56|2@1+ (1.000000,0.000000) [0.000000|3.000000] "" ICAS1_Gateway
 SG_ EM2_HV_betriebsbereit  : 58|1@1+ (1.000000,0.000000) [0.000000|1.000000] "" ICAS1_Gateway

BO_ 2527679713 EM2_HYB_27: 8 LE2
 SG_ EM2_RtmWarnKommunikation  : 12|3@1+ (1.000000,0.000000) [0.000000|7.000000] "" Vector__XXX
 SG_ EM2_RtmWarnUeberdrehzahl  : 15|3@1+ (1.000000,0.000000) [0.000000|7.000000] "" ICAS1_Gateway
 SG_ EM2_RtmWarnUeberstrom  : 18|3@1+ (1.000000,0.000000) [0.000000|7.000000] "" ICAS1_Gateway
 SG_ EM2_RtmWarnTempEM  : 21|3@1+ (1.000000,0.000000) [0.000000|7.000000] "" ICAS1_Gateway
 SG_ EM2_RtmWarnTempPWR  : 24|3@1+ (1.000000,0.000000) [0.000000|7.000000] "" ICAS1_Gateway

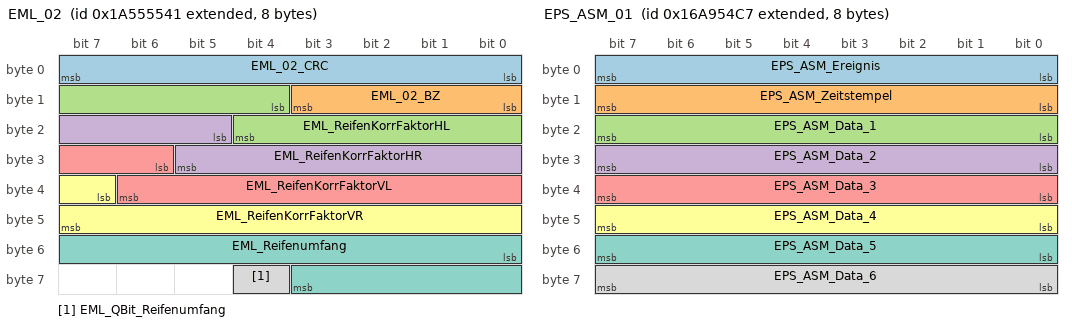
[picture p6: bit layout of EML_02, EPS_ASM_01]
BO_ 2589283649 EML_02: 8 ICAS1_Gateway
 SG_ EML_02_CRC  : 0|8@1+ (1.000000,0.000000) [0.000000|255.000000] "" Vector__XXX
 SG_ EML_02_BZ  : 8|4@1+ (1.000000,0.000000) [0.000000|15.000000] "" Vector__XXX
 SG_ EML_ReifenKorrFaktorHL  : 12|9@1+ (0.000488,0.850000) [0.850000|1.098535] "" Vector__XXX
 SG_ EML_ReifenKorrFaktorHR  : 21|9@1+ (0.000488,0.850000) [0.850000|1.098535] "" Vector__XXX
 SG_ EML_ReifenKorrFaktorVL  : 30|9@1+ (0.000488,0.850000) [0.850000|1.098535] "" Vector__XXX
 SG_ EML_ReifenKorrFaktorVR  : 39|9@1+ (0.000488,0.850000) [0.850000|1.098535] "" Vector__XXX
 SG_ EML_Reifenumfang  : 48|12@1+ (1.000000,0.000000) [0.000000|4095.000000] "Unit_MilliMeter" Motor_BEV
 SG_ EML_QBit_Reifenumfang  : 60|1@1+ (1.000000,0.000000) [0.000000|1.000000] "" Motor_BEV

BO_ 608 EML_07: 8 ICAS1_Gateway
 SG_ EML_AnzeigeGeschw  : 54|10@1+ (0.320000,0.000000) [0.000000|325.120000] "Unit_KiloMeterPerHour" Motor_BEV

BO_ 2589283751 Entfernungen_01: 8 ICAS1_KommunikationsServer
 SG_ KBI_Kilometerstand_HiRes_meter  : 32|32@1+ (1.000000,0.000000) [0.000000|4294967295.000000] "Unit_Meter" Motor_BEV

BO_ 2527679687 EPS_ASM_01: 8 ICAS1_Gateway
 SG_ EPS_ASM_Ereignis  : 0|8@1+ (1.000000,0.000000) [1.000000|254.000000] "Unit_None" Airbag
 SG_ EPS_ASM_Zeitstempel  : 8|8@1+ (0.080000,0.000000) [0.000000|20.320000] "Unit_None" Airbag
 SG_ EPS_ASM_Data_1  : 16|8@1+ (1.000000,0.000000) [0.000000|255.000000] "Unit_None" Airbag
 SG_ EPS_ASM_Data_2  : 24|8@1+ (1.000000,0.000000) [0.000000|255.000000] "Unit_None" Airbag
 SG_ EPS_ASM_Data_3  : 32|8@1+ (1.000000,0.000000) [0.000000|255.000000] "Unit_None" Airbag
 SG_ EPS_ASM_Data_4  : 40|8@1+ (1.000000,0.000000) [0.000000|255.000000] "Unit_None" Airbag
 SG_ EPS_ASM_Data_5  : 48|8@1+ (1.000000,0.000000) [0.000000|255.000000] "Unit_None" Airbag
 SG_ EPS_ASM_Data_6  : 56|8@1+ (1.000000,0.000000) [0.000000|255.000000] "Unit_None" Airbag

BO_ 258 ESC_50: 48 ICAS1_Gateway
 SG_ ESC_50_CRC  : 0|8@1+ (1.000000,0.000000) [0.000000|255.000000] "" Motor_BEV
 SG_ ESC_50_BZ  : 8|4@1+ (1.000000,0.000000) [0.000000|15.000000] "" Motor_BEV
 SG_ ESP_QBit_Gierrate  : 12|1@1+ (1.000000,0.000000) [0.000000|1.000000] "" Motor_BEV
 SG_ ESP_QBit_Laengsbeschl  : 13|1@1+ (1.000000,0.000000) [0.000000|1.000000] "" Motor_BEV
 SG_ ESP_QBit_Querb  : 14|1@1+ (1.000000,0.000000) [0.000000|1.000000] "" Motor_BEV
 SG_ ESP_Querbeschleunigung  : 16|8@1+ (0.010000,-1.270000) [-1.270000|1.270000] "Unit_ForceOfGravi" Airbag Motor_BEV
 SG_ ESP_Laengsbeschl  : 24|10@1+ (0.031250,-16.000000) [-16.000000|15.906250] "Unit_MeterPerSeconSquar" Airbag Motor_BEV
 SG_ ESC_Motorstartverzoegerung  : 34|1@1+ (1.000000,0.000000) [0.000000|1.000000] "" Vector__XXX
 SG_ ESC_SeitenwindAssistent_Eingriff  : 35|1@1+ (1.000000,0.000000) [0.000000|1.000000] "" Vector__XXX
 SG_ ESP_Anschleppstart_Freigabe  : 36|2@1+ (1.000000,0.000000) [0.000000|3.000000] "" Vector__XXX
 SG_ ESC_Unterdruckmangel_erkannt  : 38|1@1+ (1.000000,0.000000) [0.000000|1.000000] "" Vector__XXX
 SG_ ESP_Gierrate  : 40|14@1+ (0.010000,0.000000) [0.000000|163.820000] "Unit_DegreOfArcPerSecon" Airbag Motor_BEV
 SG_ ESP_VZ_Gierrate  : 54|1@1+ (1.000000,0.000000) [0.000000|1.000000] "" Airbag Motor_BEV
 SG_ ESP_Notbremsanzeige  : 55|1@1+ (1.000000,0.000000) [0.000000|1.000000] "" Vector__XXX
 SG_ ESP_SpannungsAnf  : 56|1@1+ (1.000000,0.000000) [0.000000|1.000000] "" Vector__XXX
 SG_ ESP_PLA_Abbruch  : 57|3@1+ (1.000000,0.000000) [0.000000|7.000000] "" Vector__XXX
 SG_ ESP_Status_ESP_PLA  : 60|4@1+ (1.000000,0.000000) [0.000000|15.000000] "" Vector__XXX
 SG_ ESP_QBit_Bremsdruck  : 76|1@1+ (1.000000,0.000000) [0.000000|1.000000] "" Airbag Motor_BEV
 SG_ ESP_QBit_Fahrer_bremst  : 77|1@1+ (1.000000,0.000000) [0.000000|1.000000] "" Vector__XXX
 SG_ ESP_Schwelle_Unterdruck  : 78|2@1+ (1.000000,0.000000) [0.000000|3.000000] "" Vector__XXX
 SG_ ESP_Bremsdruck  : 80|10@1+ (0.300000,-30.000000) [-30.000000|276.600000] "Unit_Bar" Motor_BEV
 SG_ ESP_Fahrer_bremst  : 90|1@1+ (1.000000,0.000000) [0.000000|1.000000] "" Vector__XXX
 SG_ ESP_Verz_TSK_aktiv  : 91|1@1+ (1.000000,0.000000) [0.000000|1.000000] "" Vector__XXX
 SG_ ESP_Lenkeingriff_ADS  : 92|1@1+ (1.000000,0.000000) [0.000000|1.000000] "" Vector__XXX
 SG_ ESP_Konsistenz_TSK  : 93|1@1+ (1.000000,0.000000) [0.000000|1.000000] "" Vector__XXX
 SG_ ESP_Bremsruck_AWV2  : 94|1@1+ (1.000000,0.000000) [0.000000|1.000000] "" Vector__XXX
 SG_ ESP_Konsistenz_AWV2  : 95|1@1+ (1.000000,0.000000) [0.000000|1.000000] "" Vector__XXX
 SG_ ECD_Fehler  : 96|1@1+ (1.000000,0.000000) [0.000000|1.000000] "" Vector__XXX
 SG_ ECD_nicht_verfuegbar  : 97|1@1+ (1.000000,0.000000) [0.000000|1.000000] "" Vector__XXX
 SG_ ESP_Status_Bremsentemp  : 98|1@1+ (1.000000,0.000000) [0.000000|1.000000] "" Vector__XXX
 SG_ ESP_Autohold_Standby  : 99|1@1+ (1.000000,0.000000) [0.000000|1.000000] "" Vector__XXX
 SG_ ESP_HDC_Standby  : 100|1@1+ (1.000000,0.000000) [0.000000|1.000000] "" Vector__XXX
 SG_ ESP_HBA_aktiv  : 101|1@1+ (1.000000,0.000000) [0.000000|1.000000] "" Vector__XXX
 SG_ ESP_Prefill_ausgeloest  : 102|1@1+ (1.000000,0.000000) [0.000000|1.000000] "" Vector__XXX
 SG_ ESP_Rueckwaertsfahrt_erkannt  : 103|1@1+ (1.000000,0.000000) [0.000000|1.000000] "" Vector__XXX
 SG_ ESP_Status_Anfahrhilfe  : 104|1@1+ (1.000000,0.000000) [0.000000|1.000000] "" Vector__XXX
 SG_ ESP_HDC_aktiv  : 105|1@1+ (1.000000,0.000000) [0.000000|1.000000] "" Vector__XXX
 SG_ ESP_StartStopp_Info  : 106|2@1+ (1.000000,0.000000) [0.000000|3.000000] "" Vector__XXX
 SG_ ESP_Eingr_HL  : 108|1@1+ (1.000000,0.000000) [0.000000|1.000000] "" Vector__XXX
 SG_ ESP_Eingr_HR  : 109|1@1+ (1.000000,0.000000) [0.000000|1.000000] "" Vector__XXX
 SG_ ESP_Eingr_VL  : 110|1@1+ (1.000000,0.000000) [0.000000|1.000000] "" Vector__XXX
 SG_ ESP_Eingr_VR  : 111|1@1+ (1.000000,0.000000) [0.000000|1.000000] "" Vector__XXX
 SG_ ESP_BKV_Unterdruck  : 112|8@1+ (4.000000,0.000000) [4.000000|1012.000000] "Unit_MilliBar" Vector__XXX
 SG_ ESP_Autohold_aktiv  : 120|1@1+ (1.000000,0.000000) [0.000000|1.000000] "" Vector__XXX
 SG_ ESP_FStatus_Anfahrhilfe  : 121|1@1+ (1.000000,0.000000) [0.000000|1.000000] "" Vector__XXX
 SG_ ESP_Verz_EPB_aktiv  : 122|1@1+ (1.000000,0.000000) [0.000000|1.000000] "" Vector__XXX
 SG_ ECD_Bremslicht  : 123|1@1+ (1.000000,0.000000) [0.000000|1.000000] "" Motor_BEV
 SG_ ESP_Verzoeg_EPB_verf  : 124|1@1+ (1.000000,0.000000) [0.000000|1.000000] "" Vector__XXX
 SG_ ESP_Status_Bremsdruck  : 125|1@1+ (1.000000,0.000000) [0.000000|1.000000] "" Vector__XXX
 SG_ ESP_Anforderung_EPB  : 126|2@1+ (1.000000,0.000000) [0.000000|3.000000] "" Vector__XXX
 SG_ ESP_ANB_CM_Rueckk_Umsetz  : 140|1@1+ (1.000000,0.000000) [0.000000|1.000000] "" Vector__XXX
 SG_ ESP_Konsistenz_ACC_Botschaft  : 141|1@1+ (1.000000,0.000000) [0.000000|1.000000] "" Vector__XXX
 SG_ ESP_Stillstandsphase_erschoepft  : 142|1@1+ (1.000000,0.000000) [0.000000|1.000000] "" Vector__XXX
 SG_ ESP_ZT_Rueckk_Umsetz  : 143|1@1+ (1.000000,0.000000) [0.000000|1.000000] "" Vector__XXX
 SG_ ESP_Tuerkontakt_Fahrertuer  : 144|1@1+ (1.000000,0.000000) [0.000000|1.000000] "" Vector__XXX
 SG_ ESP_Abrutschen_Stillstand  : 146|1@1+ (1.000000,0.000000) [0.000000|1.000000] "" Vector__XXX
 SG_ ESP_Fahrer_tritt_ZBR_Schw  : 147|1@1+ (1.000000,0.000000) [0.000000|1.000000] "" Vector__XXX
 SG_ ESP_QBit_v_ref  : 169|1@1+ (1.000000,0.000000) [0.000000|1.000000] "" Vector__XXX
 SG_ ESP_v_ref_Fahrtrichtung  : 170|2@1+ (1.000000,0.000000) [0.000000|3.000000] "" Motor_BEV
 SG_ ESC_Bremsdruckgradient  : 172|8@1+ (10.000000,0.000000) [0.000000|2500.000000] "Unit_BarPerSecon" Vector__XXX
 SG_ ESP_v_ref  : 180|12@1+ (0.125000,0.000000) [0.000000|511.500000] "Unit_KiloMeterPerHour" Airbag Motor_BEV
 SG_ ESC_Hydr_Fkt_aktiv  : 223|2@1+ (1.000000,0.000000) [0.000000|3.000000] "" Vector__XXX
 SG_ ESC_QBit_Fahrerbremswunsch  : 225|1@1+ (1.000000,0.000000) [0.000000|1.000000] "" Motor_BEV
 SG_ ESC_Fahrerbremswunsch  : 226|10@1+ (0.300000,-30.000000) [-30.000000|276.600000] "Unit_Bar" Motor_BEV
 SG_ ESCGeneratorSollMoment  : 236|12@1+ (3.000000,-12279.000000) [-12279.000000|0.000000] "" Motor_BEV
 SG_ ESC_Raddruck_max  : 248|8@1+ (1.000000,0.000000) [0.000000|250.000000] "Unit_Bar" Vector__XXX
 SG_ EPB_QBit_Pedalweg_Kuppl  : 269|1@1+ (1.000000,0.000000) [0.000000|1.000000] "" Vector__XXX
 SG_ EPB_Freig_Verzoeg_Anf  : 271|1@1+ (1.000000,0.000000) [0.000000|1.000000] "" Vector__XXX
 SG_ EPB_Verzoeg_Anf  : 272|8@1+ (0.048000,-7.968000) [-7.968000|4.224000] "Unit_MeterPerSeconSquar" Vector__XXX
 SG_ EPB_Pedalweg_Kuppl  : 288|8@1+ (0.400000,0.000000) [8.000000|92.000000] "Unit_PerCent" Vector__XXX
 SG_ EPB_DAA_Randbed_erf  : 305|1@1+ (1.000000,0.000000) [0.000000|1.000000] "" Vector__XXX
 SG_ EPB_Fehlerstatus_02  : 306|2@1+ (1.000000,0.000000) [0.000000|3.000000] "" Vector__XXX
 SG_ EPB_Schalterposition  : 308|2@1+ (1.000000,0.000000) [0.000000|3.000000] "" Airbag
 SG_ EPB_QBit_Schalterpos  : 310|1@1+ (1.000000,0.000000) [0.000000|1.000000] "" Vector__XXX
 SG_ EPB_Spannkraft  : 312|5@1+ (1.000000,0.000000) [0.000000|29.000000] "Unit_KiloNewto" Vector__XXX
 SG_ EPB_Status_02  : 317|3@1+ (1.000000,0.000000) [0.000000|7.000000] "" Motor_BEV
 SG_ EPB_Status  : 320|2@1+ (1.000000,0.000000) [0.000000|3.000000] "" Vector__XXX
 SG_ ESP_Status_Bremsentemp_02  : 322|2@1+ (1.000000,0.000000) [0.000000|3.000000] "" Motor_BEV

CM_ BO_ 1520 "abMQBnachabgestimmtenFLHDimmung";
CM_ BO_ 1603 "abMQBmit8Byte";
CM_ SG_ 514 DR_Aufbaubeschleunigung_HR "Aufbaubeschleunigungssensor
Auflösung 1g/300
Wertebereich -1,6g..1,6g
in m/s^2 übertragen.";
CM_ SG_ 514 DR_Aufbaubeschleunigung_VR "Aufbaubeschleunigungssensor
Auflösung 1g/300
Wertebereich -1,6g..1,6g
in m/s^2 übertragen.";
CM_ SG_ 514 DR_Aufbaubeschleunigung_VL "Aufbaubeschleunigungssensor
Auflösung 1g/300
Wertebereich -1,6g..1,6g
in m/s^2 übertragen.";
CM_ SG_ 514 DR_Aufbaubeschleunigung_HL "Aufbaubeschleunigungssensor
Auflösung 1g/300
Wertebereich -1,6g..1,6g
in m/s^2 übertragen.";
CM_ SG_ 514 DR_Funktionsstatus "FunktionsstatusdesDCC_Gen3-SG";
CM_ SG_ 514 DR_Drehwinkelsensortausch_VL "ZählerderbeijedemerkanntenDrehwinkelsensortauschinkrementiertwird.SystemediedenDrehwinkelwertempfangenkönnennotwendigenInbetriebnahmefunktionenstarten";
CM_ SG_ 514 DR_Drehwinkelsensortausch_VR "ZählerderbeijedemerkanntenDrehwinkelsensortauschinkrementiertwird.SystemediedenDrehwinkelwertempfangenkönnennotwendigenInbetriebnahmefunktionenstarten";
CM_ SG_ 514 DR_Drehwinkelsensortausch_HL "ZählerderbeijedemerkanntenDrehwinkelsensortauschinkrementiertwird.SystemediedenDrehwinkelwertempfangenkönnennotwendigenInbetriebnahmefunktionenstarten";
CM_ SG_ 514 DR_Drehwinkelsensortausch_HR "ZählerderbeijedemerkanntenDrehwinkelsensortauschinkrementiertwird.SystemediedenDrehwinkelwertempfangenkönnennotwendigenInbetriebnahmefunktionenstarten";
CM_ SG_ 514 DR_Drehwinkel_VL "DrehwinkelsensorzurBerechnungvonDämpferwegundfürLWR";
CM_ SG_ 514 DR_Drehwinkel_VR "DrehwinkelsensorzurBerechnungvonDämpferwegundfürLWR";
CM_ SG_ 514 DR_Drehwinkel_HL "DrehwinkelsensorzurBerechnungvonDämpferwegundfürLWR";
CM_ SG_ 514 DR_Drehwinkel_HR "DrehwinkelsensorzurBerechnungvonDämpferwegundfürLWR";
CM_ SG_ 1485 DCDC_03_CRC "FürMLB:
'Berechnung siehe Lastenheft 'Kommunikationsabsicherung für FlexRay und CAN''

Ab MQB und MLBevo:
'Berechnung siehe Lastenheft 'End-to-End Kommunikationsabsicherung''

Endwerte siehe Begleitdokument 'S-PDU Kennungsfolgen'";
CM_ SG_ 1485 DC_Temperatur_Alarm "Temperatur-AlarmDCDC-WandlerRTM";
CM_ SG_ 1485 DC_Kl30c_Status "Signalisierungdes
Stecker-Zustandes der Klemme 30c (Service-Disconnect)

0=Init
1=geschlossen
2=offen
3=Fehler";
CM_ SG_ 1485 DC_Fehlerstatus "aktuellerFehlerstatusdesDCDC-Wandler:";
CM_ SG_ 1485 DC_Peakstrom_verfuegbar "Peakstromverfügbar/nichtverfügbar";
CM_ SG_ 1485 DC_Abregelung_Temperatur "AbregelungaufgrundÜbertemperaturimLeistungsteil(Hochtemperatur-Abregelung)";
CM_ SG_ 1485 DC_IstModus_02 "aktuelleBetriebsartdesDC/DCWandler";
CM_ SG_ 1485 DC_Derating "Signalisierung,obderDC/DC-WandlersichinderAbregelungbefindet:
0=keine_Abregelung
1= Abregelung_Ursache_NV
2= Abregelung_Ursache_HV
3= Abregelung_Ursache_Temp
4= Abregelung_Ursache_Intern";
CM_ SG_ 1485 DC_SollVolumenstrom "FürdieKühlungdesDC/DCWandleraktuellmindestensbenötigterKühlwasservolumenstrom";
CM_ SG_ 1485 DC_Status_Spgfreiheit_HV "HVDC/DC-WandlerStatusHV-Spannungsfreiheit";
CM_ SG_ 1485 DC_Temperatur "Momentanwert:TemperaturdesDC/DCWandlers";
CM_ SG_ 247 DCDC_04_CRC "FürMLB:
Berechnung siehe Lastenheft 'Kommunikationsabsicherung für FlexRay und CAN'
Ab MQB und MLBevo:
Berechnung siehe Lastenheft 'End-to-End Kommunikationsabsicherung'

Endwerte siehe Begleitdokument 'S-PDU Kennungsfolgen'";
CM_ SG_ 247 DCDC_04_BZ "4bitBotschaftszähler,wirdmitjederSendebotschaftinkrementiert";
CM_ SG_ 247 DC_Vorladung_Status "StatusderZK-Vorladung:

=0, nicht_abgeschlossen
=1, abgeschlossen

DCDC-Wandler gibt Empfehlung für schließen der Schützen.
HVK/BMS prüft die ZK-Spannung und entscheidet ob die Schütze geschlossen werden können.";
CM_ SG_ 247 DC_Fehler_extern "Fehler/Abschaltung:DC/DC-WandleristaufgrundeinerUmgebungsbedingung(z.B.HV-Spannung,NV-SpannungKühlmitteltemperaturoderSystemfehler(ZK-Vorladung))nichtinderLagegefordertenRegelbetriebeinzuhalten.";
CM_ SG_ 247 DC_Fehler_intern "Fehler:DC/DC-WandleristaufgrundeinesinternenHardware-Fehlersabgeschaltet";
CM_ SG_ 247 DC_Status_Spgfreiheit "StatusderSpannungsfreiheitfürdenStandaloneDCDC-Wandler(HV-NV)
0=Init (ohne Funktion)
1=BMS Zwischenkreis spannungsfrei (U_Zwkr < 20V)
2=BMS Zwischenkreis nicht spannungsfrei (U_Zwkr >/= 25V, Hysterese)
3=Fehler (z.B. Fehler in der Sensorik)";
CM_ SG_ 247 DC_Status_EoHVL "StatusderEoHVLamDCDC:
0=Init
1=Keine offene HV-Leitung erkannt
2=offene HV-Leitung erkannt
3=Fehler";
CM_ SG_ 247 DC_IstModus_02 "aktuelleBetriebsartdesDC/DCWandler";
CM_ SG_ 247 DC_IstStrom_HV "Momentanwert:StromausdemTraktionsnetzindenDC/DCWandler";
CM_ SG_ 247 DC_IstLeistung_HV "AktuelleIst-LeistungdesBordnetzwandlersaufderHV-Seite.

Tiefsetzen - positiv
Hochsetzen- negativ";
CM_ SG_ 2549876269 Diag_Waehlhebel_Req_Data "UDS-Diagnose
ISO-TP Datenkanal - FID2NA
Request Funktion 0x06 Diagnosezugriff vom DK4-Master auf DK1/2-Knoten 0x62D";
CM_ SG_ 2550007341 Diag_Waehlhebel_Resp_Data "UDS-Diganose
ISO-TP Datenkanal - FID2NA
Response DK1/2-Knoten 0x62D an Funktion 0x06 Diagnosezugriff vom DK4-Master";
CM_ SG_ 1714 DGN_Verlernzaehler "wraparound254-->0";
CM_ SG_ 1714 KBI_Kilometerstand "Fehlerwirdausgegeben,fallsKilometerstandnichtrestaurierbar
";
CM_ SG_ 1714 UH_Monat "0x0D,0xF=Werteungültig
0x0E = reserviert (nur VW)";
CM_ SG_ 1714 UH_Tag "0x0:reserviertbeiVW";
CM_ SG_ 1714 UH_Stunde "0x18-0x1F=Werteungültig";
CM_ SG_ 1714 UH_Minute "0x3C-0x3f=Werteungültig";
CM_ SG_ 1714 UH_Sekunde "0x3C-0x3f=Werteungültig";
CM_ SG_ 1714 Vehicle_Driving_Cycle "OptimierungderInbetriebnahmevonSteuergerätenineinemTeilverbauinderProduktion.
Siehe VW80114. Signal bildet (durch eine Gateway-Funktion) den Inhalt des Signals OBD_Driving_Cycle ab.";
CM_ SG_ 1714 Uhrzeit_01_alt "
";
CM_ SG_ 851 DiETas_01_CRC "FürMLB:
Berechnung siehe Lastenheft 'Kommunikationsabsicherung für FlexRay und CAN'
Ab MQB und MLBevo:
Berechnung siehe Lastenheft 'End-to-End Kommunikationsabsicherung'

Endwerte siehe Begleitdokument 'S-PDU Kennungsfolgen'";
CM_ SG_ 851 DiETas_01_BZ "4bitBotschaftszähler,wirdmitjederSendebotschaftinkrementiert";
CM_ SG_ 851 DiETa_Reserve_Byte2_4 "Vorhalt,Initialisierungmit'0'";
CM_ SG_ 851 DiETa_Status "BetriebszustandDirekteinstiegstasten";
CM_ SG_ 851 DiETa_ResponseError "sieheLIN2.0-Specification
(Darf nicht über ein Fehlergueltigkeitsbit abgesichtert werden!)";
CM_ SG_ 851 DiETa_Car "StatusCar-Taste";
CM_ SG_ 851 DiETa_Klima "StatusKlimataste";
CM_ SG_ 851 DiETa_Mode "StatusModetaste";
CM_ SG_ 851 DiETa_Parken "StatusParkentaste";
CM_ SG_ 851 DiETa_FSH_Taste "FrontscheibenheizungAN/AUS";
CM_ SG_ 851 DiETa_HSH_Taste "HeckscheibenheizungAN/AUS";
CM_ SG_ 851 DiETa_Warnblink_Taste "StatusWarnblinktaster";
CM_ SG_ 851 DiETa_FAS_Stufe "StatusFAS-Taste";
CM_ SG_ 851 DiETa_PAO_ON_Status "IstwertfürLED'ON'inAnzeigePassengerAirbagOn/Off";
CM_ SG_ 851 DiETa_PAO_OFF_Status "IstwertfürLED'OFF'inAnzeigePassengerAirbagOn/Off";
CM_ SG_ 851 DiETa_Defrost_Taste "Max.DefrostAN/AUS";
CM_ SG_ 851 DiETa_Reserve_Byte5_6 "Vorhalt,Initialisierungmit'0'";
CM_ SG_ 851 DiETa_Lock_Unlock_Taste "Lock-/Unlock-Taste";
CM_ SG_ 851 DiETa_Mode_roh "ErweitertesSIgnalzurErfüllungderOBD-RelevanzfürdieFunktionModeaufderDiETa";
CM_ SG_ 851 DiETa_Reserve_Byte6_3 "Vorhalt,Initialisierungmit'0'";
CM_ SG_ 851 DiETa_Reserve_Byte7 "Vorhalt,Initialisierungmit'0'";
CM_ SG_ 851 DiETa_Reserve_Byte8 "Vorhalt,Initialisierungmit'0'";
CM_ SG_ 1520 DI_KL_58xd "Klemme58xdDisplay-undFunktionsbeleuchtung
Mit der Klemme 58xd wird die Helligkeit der Display- und der Funktionsbeleuchtungen der Schalter gesteuert.
Im Detail beschrieben im 'Funktionslastenheft Dimmung MQB'.";
CM_ SG_ 1520 DI_KL_58xs "SuchbeleuchtungSchalter
EIN-AUS-Schaltalgorithmus der allgemeinen Schaltersuchbeleuchtung.
Im Detail beschrieben im 'Funktionslastenheft Dimmung MQB'.
";
CM_ SG_ 1520 DI_Display_Nachtdesign "FürDisplayssindoftautomatischeUmschaltungenvonTag-/Nachtdesignvorgesehen.
Es gibt jedoch Zustände, an denen auch tagsüber das Abblendlicht eingeschaltet ist.
z.B. Dauerfahrlicht, Geschwindigkeitsabhängiges 'Licht-An-Bei-Autobahn', 'Regenlicht',";
CM_ SG_ 1520 DI_KL_58xt "TimergesteuerteSuchbeleuchtung
Der EIN-AUS-Schaltalgorithmus für die vor- und nachlaufende Schaltersuchbeleuchtungen beim Ein- & Aussteigen; z.B.: Start/Stop-Taster.
Im Detail beschrieben im 'Funktionslastenheft Dimmung MQB'.";
CM_ SG_ 1520 DI_Fotosensor "HelligkeitswertFotosensor
Für die Dimmung relevanter Wert zur Sensierung der Umgebungshelligkeit
Im Detail beschrieben im 'Funktionslastenheft Dimmung MQB'.";
CM_ SG_ 1520 BCM1_Stellgroesse_Kl_58s "RohwertDimmpoti";
CM_ SG_ 420 EA_01_CRC "AbMQBundMLBevo:
'Berechnung siehe Lastenheft 'End-to-End Kommunikationsabsicherung''";
CM_ SG_ 420 EA_01_BZ "EABotschaftszähler";
CM_ SG_ 420 EA_Parken_beibehalten_HMS "AnforderungumautomatischeslösenderParkbremsezuverhindern";
CM_ SG_ 420 EA_Ruckstaerke "AnforderungderRuckstaerkeinschwach,mitteloderstark.";
CM_ SG_ 420 EA_Warnruckprofil "EmergencyAssistAnforderunganESP,welcherRuckverwendetwerdensoll.";
CM_ SG_ 420 EA_aktiv_laengs "Zeigtan,obderEmergencyAssistaktivlängsregelt.";
CM_ SG_ 420 EA_Funktionsstatus "EmergencyAssistFunktionsstatus";
CM_ SG_ 420 EA_Gurtstraffer_Anf "EmergencyAssistAnforderungreversiblerGurtstraffer";
CM_ SG_ 420 EA_Anf_Prefill "EmergencyAssistAnforderunganPrefill";
CM_ SG_ 420 EA_Anforderung_HMS "EmergencyAssistAnforderunganHMS";
CM_ SG_ 420 EA_Ruckfreigabe "EmergencyAlertFreigabitfürdieWarnruck-AnforderungandasESP";
CM_ SG_ 420 EA_01_Sendestatus "GibtdenSendestatusderBotschaftEA_01an(notwendigfürIL-Unterstützung)";
CM_ SG_ 420 EA_Sollbeschleunigung "EmergencyAssistBeschleunigungsanforderung";
CM_ SG_ 374 EBKV_03_CRC "FürMLB:
Berechnung siehe Lastenheft 'Kommunikationsabsicherung für FlexRay und CAN'
Ab MQB und MLBevo:
Berechnung siehe Lastenheft 'End-to-End Kommunikationsabsicherung'

Endwerte siehe Begleitdokument 'S-PDU Kennungsfolgen'";
CM_ SG_ 374 EBKV_03_BZ "4bitBotschaftszähler,wirdmitjederSendebotschaftinkrementiert";
CM_ SG_ 374 EBKV_Activate_Fallback_ESP "DasSignalaktiviertimESCdieRückfallebene.";
CM_ SG_ 374 EBKV_Restdruckabsenkung "DiesesSignalermöglichtdieSteuerungeinerRoutinezurRestdruckabsenkungausdemeBKVheraus.
Die genaue Funktionsausprägung muss für das jeweilige Projekt festgelegt werden.";
CM_ SG_ 374 EBKV_Status_02 "eBKVStatusSignalfür2und3BoxSysteme";
CM_ SG_ 374 EBKV_Diagnose "eBKVimDiagnosemodus";
CM_ SG_ 374 EBKV_Fahrer_bremst "Fahrerwillbremsen(Eintreterkennung).
Wird benötigt, um ACC oder GRA abzuschalten.";
CM_ SG_ 374 EBKV_QBit_Fahrer_bremst "
";
CM_ SG_ 374 EBKV_Fahrer_bremst_deutlich "RückmeldungdeseBKVs,obderFahrerdeutlicheineBremsungwünscht.

Eine Aktivierung des Signals erfolgt bei 50N Pedalkraft (Druckäquivalent= 20bar, verwendet in AWV-Fkt.)
";
CM_ SG_ 374 EBKV_OBD_Status "AnsteuerungderMIL-LampeüberdenMIL-Master(Motorsteuergerät)";
CM_ SG_ 374 EBKV_VMM_Sek_Notstopp_Status "BeschreibtdeneBKV-seitigenStatuszurKommunikationmitderSteuerungderNotstoppRückfallebeneimESC";
CM_ SG_ 374 EBKV_Anforderung_HMS "AnforderungandemHaltemanagervomEBKV";
CM_ SG_ 374 SBS_Anforderung_GE "DasSekundärbremssystem(SBS)realisiertmitdieserSchnittstelleeinSicherndesFahrzeugs.NacheinerBremsungindenStillstandüberdiedirekteVerzögerungsschnittstellewirdhierüberdieGetriebesperreangefordert.";
CM_ SG_ 374 EPB_Status_ext "ZustanddesseparatangeschlossenenAktuators.SignalwirdnurimMEBverwendet.";
CM_ SG_ 374 EBKV_Bremspedalweg "BremspedalwertinProzent.DerWertistNullpunkt-abgeglichen.
Bremspedalweg von der EBKV eingelesen.";
CM_ SG_ 374 EBKV_Kraftblending_Reserve "MaximaleDruckdifferenz,diedurchPedalkraftblendingnochsimuliertwerdenkann";
CM_ SG_ 374 EBKV_Aussteuerdruck "DasSignalübermitteltseitensdesEBKVsfrühzeitigdenaktuellen,Fahrsituations-abhängig-variablenBrems-VordruckandasESC,beidemdiemaximaleBremskraftunterstützungdesEBVKerreichtist.
Über diesen übermittelten Druck-Wert erkennt das ESC den ";
CM_ SG_ 1603 KBI_Einheit_Datum "AnzeigevariantedesDatums";
CM_ SG_ 1603 KBI_Einheit_Druck "EinheitdesDruckes";
CM_ SG_ 1603 KBI_Einheit_Streckenanz "EinheitderStreckenanzeige";
CM_ SG_ 1603 KBI_MFA_v_Einheit_02 "EinheitderGeschwindigkeit,dievomFahrerimCar-Menügewähltwurde.VeränderlicheGrösse,imGegensatzzurEinheitdesTachokranzes.

Redundant in der Einheiten_01 Botschaft definiert, um Konsistenz zur BAP-Festlegung zu haben.";
CM_ SG_ 1603 KBI_Einheit_Temp "EinheitderTemperatur";
CM_ SG_ 1603 KBI_Einheit_Uhrzeit "AnzeigevariantederUhrzeit";
CM_ SG_ 1603 KBI_Einheit_Verbrauch "EinheitderVerbrauchs";
CM_ SG_ 1603 KBI_Einheit_Volumen "EinheitdesVolumens";
CM_ SG_ 1603 KBI_Einheit_Verbrauch_elektr "EinheitelektrischerVerbrauch";
CM_ SG_ 1603 KBI_Einheit_Tacho "Information,obessichumMeilen-oderKmh-Kombihandelt,EinheitdesTachosentsprichtdemZifferblatt,Grösseistnichtveränderlich";
CM_ SG_ 1603 KBI_Einheit_Sprache "SieheBAP-DatenfestlegungUnitMaster";
CM_ SG_ 1603 KBI_Einheit_Verbrauch_Gas "UnterscheidungzwischenM3/hundkg/hfürKomfortverbrauchsberechnung.";
CM_ SG_ 1603 KBI_Einheit_Masse "EinheitderMasse(Verwendungz.B.ASTA)";
CM_ SG_ 192 EM1_01_CRC "FürMLB:
Berechnung siehe Lastenheft 'Kommunikationsabsicherung für FlexRay und CAN'
Ab MQB und MLBevo:
Berechnung siehe Lastenheft 'End-to-End Kommunikationsabsicherung'

Endwerte siehe Begleitdokument 'S-PDU Kennungsfolgen'";
CM_ SG_ 192 EM1_01_BZ "4bitBotschaftszähler,wirdmitjederSendebotschaftinkrementiert";
CM_ SG_ 192 EM1_Istmodus "aktuelleBetriebsartderE-Maschine...
0: Standby; Kommunikation aktiv; PSM: Aktiver Kurzschluss eingenommen
1: Momentenreglung
2: Drehzahlregeung (interner Regelkreis)
3: Spannungsregelung
4: Drehzahlregelung (externer Regelkreis)
5: interner Inver";
CM_ SG_ 192 EM1_IstMoment "Momentanwert:E-MaschinenMoment";
CM_ SG_ 192 EM1_Moment_AR_Eingriff "Momentanwert:EingriffsmomentderAnti-Ruckel-FunktionimPWR";
CM_ SG_ 192 EM1_IstDrehzahl "Momentanwert:E-MaschinenDrehzahl";
CM_ SG_ 192 EM1_AR_aktiv "Ruckeldämpferaktiv";
CM_ SG_ 192 EM1_IstSpannung "Momentanwert:HV-SpannungamPWR";
CM_ SG_ 192 EM1_Strom_HV "Momentanwert:HVDC-StromdesPWR";
CM_ SG_ 192 EM1_Max_Moment "maximaldarstellbaresMomentfüreineimFunktionslastenheftdefinierteDauer

Die Berechnung der Momentengrenzen wird projektspezifisch festgelegt";
CM_ SG_ 192 EM1_ErwGrenzen_aktiv "DieabsolutenMomentengrenzensindfürdieDurchführungeinesVKM-Startsggf.aufgeweitet";
CM_ SG_ 192 EM1_Min_Moment "minimaldarstellbaresMomentfüreineimFunktionslastenheftdefinierteDauer

Die Berechnung der Momentengrenzen wird projektspezifisch festgelegt
";
CM_ SG_ 192 EM1_Fehler_ElAntriebAbschaltung "Fehler:PWRbefindetsichimaktivenKurzschluss
alle vom EMS gesendeten Max- und Min-Momente und das aktuelle EM-Moment nehmen in diesem Zustand den Wert des für die aktuelle Drehzahl entsprechenden Schleppmoments der E-Maschine an";
CM_ SG_ 192 EM1_Max_Moment_Lim "MaximalesMomentbeidermomentanenMaschinendrehzahl,motorischerBetrieb,berechnetausAbregelstromMO_EMx_Max_Strom_LimundaktuellerSpannung";
CM_ SG_ 192 EM1_Fehler_Notabschaltung "Fehler:LeistungselektronikfordertAbschaltungdesHV-NetzeswegeneinesschwerenFehlersan";
CM_ SG_ 192 EM1_Min_Moment_Lim "MinimalesMomentbeidermomentanenMaschinendrehzahl,generatorischerBetrieb,berechnetausAbregelstromMO_EMx_Min_Strom_LimundaktuellerSpannung";
CM_ SG_ 192 EM1_Status_DrzEingriff "StatusASR-EingriffüberEM-Regelung";
CM_ SG_ 192 EM1_Mom_DrzEingriff "WirksamesMomentderEMzumBegrenzenderDrehzahlaufDrehzahlbegrenzung";
CM_ SG_ 2463978673 EM1_Status_Spgfreiheit "0=Init(ohneFunktion)
1 = Leistungselektronik HV-Komponenten spannungsfrei (U_Zwkr < 20V)
2 = Leistungselektronik HV_Komponenten nicht spannungsfrei (U_Zwkr >= 20V)
3 = Fehler (z. B. Fehler in der Sensorik)";
CM_ SG_ 2463978673 EM1_Status_EoHVL "StatusderHV-SpannungamPWRfürdieFunktionEoHVL";
CM_ SG_ 2463978673 EM1_Max_LeistungMech_Sockel "MaximalmöglichemechanischeLeistungoberhalbdesEckpunkts,bezogenaufdiezugeteilteelektrischeLeistung,";
CM_ SG_ 2463978673 EM1_Max_Moment_Sockel "MaximalmöglichesMomentbiszumEckpunktbezogenaufdiezugeteilteelektrischeLeistung,motorischerBetrieb";
CM_ SG_ 2463978673 EM1_Min_LeistungMech_Sockel "MinimalmöglichemechanischeLeistungoberhalbdesEckpunkts,bezogenaufdiezugeteilteelektrischeLeistung,generatorischerBetrieb";
CM_ SG_ 2463978673 EM1_Min_Moment_Sockel "MinimalmöglichesMomentbiszumEckpunktbezogenaufdiezugeteilteelektrischeLeistung,generatorischerBetrieb";
CM_ SG_ 2463978673 EM1_PerfInd_MaxLeistung "Performance-IndikatorfürdieVerfügbarkeitderMaximalleistung";
CM_ SG_ 2463978673 EM1_PerfInd_MaxMoment "Performance-IndikatorfürdieVerfügbarkeitdesMaximalmoments";
CM_ SG_ 2463978673 EM1_AnlernenElMotor_Anf "DiagnoseanforderungvonE-Maschine/PWR:Hybrid-ControllerschaltetüberMO_EM_Sollmodus=6bzw.MY3_EM_modeReq=6E-Maschine/PWRaktivindenKalibriermodus(Strategiemusssicherstellen,dasskeinMomentbeiderEMangefordertwird.)";
CM_ SG_ 2463978673 EM1_OBD_Lampe_Anf "InallenVW-/Audi-FahrzeugenisteinMIL-Master-Konzeptumgesetzt.DazuermitteltjedesOBD-SteuergerätdeneigenenMIL-Status.EineMIL-AnsteuerungwirdvombetroffenenOBD-SteuergerätperMIL-RequestüberCANandenMIL-Masterweitergegeben.DerMIL-Mas";
CM_ SG_ 2463978673 EM1_Generator_Moment "ErforderlichesgeneratorischesMomentzurDarstellungderelektrischenWunschleistungbeidermomentanenMaschinendrehzahl";
CM_ SG_ 2463978673 EM1_PerfInd_Temperatur "ThermischerPerformance-IndikatorabhängigvonMaschinen-undLE-Temperatur";
CM_ SG_ 2463978673 EM1_MaxZul_Drehzahl "EM1_MaxZul_DrehzahlstelltdiemaximaleDrehzahlgrenzefürLEbzw.EMdardieimFreilaufzulässigist.FürDrehzahlengrößerdieserGrenzewirddieLEzumKomponentenschutzunabhängigvonderKommandierungindenAKSumschalten.";
CM_ SG_ 2463978673 EM1_Min_Moment_Gesamt "MinimalmöglichesMomentbeidermomentanenMaschinendrehzahlbezogenaufdievomSystemaufnehmbareelektrischeGesamtleistungMO_EM1_Min_Leistung_Gesamt,generatorischerBetrieb";
CM_ SG_ 2463978673 EM1_Fehlerlampe_Anf "AnforderungderrotenHybrid-WarnlampeimKombi";
CM_ SG_ 2463978673 EM1_Max_Moment_Gesamt "MaximalmöglichesMomentbeidermomentanenMaschinendrehzahlbezogenaufdieimSystemverfügbareelektrischeGesamtleistungMO_EM1_Max_Leistung_Gesamt,motorischerBetrieb";
CM_ SG_ 2463978673 EM1_Warnlampe_Anf "AnforderungdergelbenHybrid-WarnlampeimKombi";
CM_ SG_ 2463978673 EM1_Rekuperation "Rekuperation-EnergiederEMgetriebeintegriert";
CM_ SG_ 2463978673 EM1_Rekuperation_Ueberlauf "RekuperationleistungssignalEM1_Rekuperationmindest1xübergelaufen";
CM_ SG_ 2463978673 EM1_Verbrauch "Antriebs-EnergiederEM1getriebeintegriert";
CM_ SG_ 2463978673 EM1_Verbrauch_Ueberlauf "Überlauf-BitfürdasSignalEM1_Verbrauch.
Rekuperationleistungssignal mindest 1x übergelaufen;";
CM_ SG_ 2463978673 EM1_Fehler_AE "AusgabeeinesFehlersinderFunktionaktiveEntladungimPWR";
CM_ SG_ 2463978673 EM1_Fehler_Leistungsred "EingeschränkteLeistungsfähigkeitaufGrundeinsinternenFehlers";
CM_ SG_ 2463978673 EM1_Fehler_ElAntriebFreilauf "Fehler:EMimFreilauf;LeistungselektronikfordertBegrenzungdermaximalenDrehzahlan,umÜberspannungimHV-Zwischenkreiszuvermeiden";
CM_ SG_ 2463978673 EM1_PWR_SollVolumenstrom "FürdieKühlungdesPWRaktuellmindestensbenötigterKühlwasservolumenstrom";
CM_ SG_ 2589283657 EM1_SollVorlauftemperatur "SolltemperaturdesKühlmittelsamVorlaufdesPWR";
CM_ SG_ 2589283657 EM1_Temperatur_EM "TemperaturderE-Maschine";
CM_ SG_ 2589283657 EM1_EM_SollVolumenstrom "FürdieKühlungderE-MaschineaktuellmindestensbenötigterKühlwasservolumenstrom


MQB/MEB: funktional 500ms (Cyclic) Zykluszeit notwendig

MLBevo: funktional 50ms (OnChange) Zykluszeit notwendig";
CM_ SG_ 2589283657 EM1_Max_MechLeistung_nom "MaximaleparametrierteLeistungdeselektrischenAntriebsbestehendausPWRundEM,interneBegrenzung";
CM_ SG_ 2589283657 EM1_Max_Moment_nom "MaximalesparametriertesMomentdeselektrischenAntriebsbestehendausPWRundEM,interneBegrenzung";
CM_ SG_ 2589283657 EM1_Temperatur_PWR "Momentanwert:TemperaturdesPWR";
CM_ SG_ 184 EM1_Freigabe_Info_WFS "WFS-Freigabeinformation";
CM_ SG_ 184 EM1_Sperr_Info_WFS "WFS-Sperrinformation
";
CM_ SG_ 184 EM1_AR_aktiv "Ruckeldämpferaktiv";
CM_ SG_ 184 EM1_Eta_Sys "InstantaneousefficiencyofelectricaldriveEM1/MomentanerWirkungsgradelektrischerAntriebEM1";
CM_ SG_ 184 EM1_IstStrom "Momentanwert:StromüberPWR";
CM_ SG_ 184 EM1_Fehler_ElAntriebFreilauf_Anf "WirdgesetztumdenzwingendenBedarfeinerUmschaltungindenFreilaufanzuzeigen.VergleicheSignalEM1_MaxZul_Drehzahl.";
CM_ SG_ 184 EM1_Abregelung_Temperatur "LeistungsbegrenzungaufgrundÜbertemperaturderE-Maschine/desPWR";
CM_ SG_ 184 EM1_AnlernenElMotor_Anf "DiagnoseanforderungvonE-Maschine/PWR:Hybrid-ControllerschaltetüberMO_EM_Sollmodus=6bzw.MY3_EM_modeReq=6E-Maschine/PWRaktivindenKalibriermodus(Strategiemusssicherstellen,dasskeinMomentbeiderEMangefordertwird.)";
CM_ SG_ 184 EM1_Moment_HVVerbraucher "rechnerischbenötigtesGenerator-Moment,umdenBedarfderel.Nebenverbraucherincl.Batterieladungabzudecken";
CM_ SG_ 184 EM1_Freigabe_Verfallsinfo_WFS "WFS";
CM_ SG_ 184 EM1_Parken_WFS_Status "StatusderLimitierung";
CM_ SG_ 184 EM1_HV_betriebsbereit "1:Ready_HV/1:HV-NetzSpannungimBetriebsbereich";
CM_ SG_ 2527679712 EM1_RtmWarnKommunikation "RealTimeMonitoringEM1buscommunicationfault";
CM_ SG_ 2527679712 EM1_RtmWarnUeberdrehzahl "RTMSignaloverspeedwarningEM1";
CM_ SG_ 2527679712 EM1_RtmWarnUeberstrom "RTMSignalover-currentwarningEM1";
CM_ SG_ 2527679712 EM1_RtmWarnTempEM "RTMSignalover-tempwarningEM1";
CM_ SG_ 2527679712 EM1_RtmWarnTempPWR "RTMSignalover-tempwarningEM1-PWR";
CM_ SG_ 193 EM2_01_CRC "FürMLB:
Berechnung siehe Lastenheft 'Kommunikationsabsicherung für FlexRay und CAN'
Ab MQB und MLBevo:
Berechnung siehe Lastenheft 'End-to-End Kommunikationsabsicherung'

Endwerte siehe Begleitdokument 'S-PDU Kennungsfolgen'";
CM_ SG_ 193 EM2_01_BZ "4bitBotschaftszähler,wirdmitjederSendebotschaftinkrementiert";
CM_ SG_ 193 EM2_Istmodus "aktuelleBetriebsartderE-Maschine...
0: Standby; Kommunikation aktiv; PSM: Aktiver Kurzschluss eingenommen
1: Momentenreglung
2: Drezahlregeung (interner Regelkreis)
3: Spannungsregelung
4: Drehzahlregelung (externer Regelkreis)
5: interner Invert";
CM_ SG_ 193 EM2_IstMoment "Momentanwert:E-MaschinenMoment";
CM_ SG_ 193 EM2_Moment_AR_Eingriff "Momentanwert:EingriffsmomentderAnti-Ruckel-FunktionimPWR";
CM_ SG_ 193 EM2_IstDrehzahl "Momentanwert:E-MaschinenDrehzahl";
CM_ SG_ 193 EM2_AR_aktiv "Ruckeldämpferaktiv";
CM_ SG_ 193 EM2_IstSpannung "Momentanwert:HV-SpannungamPWR";
CM_ SG_ 193 EM2_Strom_HV "Momentanwert:HVDC-StromdesPWR";
CM_ SG_ 193 EM2_Max_Moment "maximaldarstellbaresMomentfüreineimFunktionslastenheftdefinierteDauer

Die Berechnung der Momentengrenzen wird projektspezifisch festgelegt
";
CM_ SG_ 193 EM2_ErwGrenzen_aktiv "DieabsolutenMomentengrenzensindfürdieDurchführungeinesVKM-Startsggf.aufgeweitet";
CM_ SG_ 193 EM2_Min_Moment "minimaldarstellbaresMomentfüreineimFunktionslastenheftdefinierteDauer

Die Berechnung der Momentengrenzen wird projektspezifisch festgelegt
";
CM_ SG_ 193 EM2_Fehler_ElAntriebAbschaltung "Fehler:PWRbefindetsichimaktivenKurzschluss
alle vom EMS gesendeten Max- und Min-Momente und das aktuelle EM-Moment nehmen in diesem Zustand den Wert des für die aktuelle Drehzahl entsprechenden Schleppmoments der E-Maschine an";
CM_ SG_ 193 EM2_Max_Moment_Lim "MaximalesMomentbeidermomentanenMaschinendrehzahl,motorischerBetrieb,berechnetausAbregelstromMO_EMx_Max_Strom_LimundaktuellerSpannung";
CM_ SG_ 193 EM2_Fehler_Notabschaltung "Fehler:LeistungselektronikfordertAbschaltungdesHV-NetzeswegeneinesschwerenFehlersan";
CM_ SG_ 193 EM2_Min_Moment_Lim "MinimalesMomentbeidermomentanenMaschinendrehzahl,generatorischerBetrieb,berechnetausAbregelstromMO_EMx_Min_Strom_LimundaktuellerSpannung";
CM_ SG_ 193 EM2_Status_DrzEingriff "StatusASR-EingriffüberEM-Regelung";
CM_ SG_ 193 EM2_Mom_DrzEingriff "WirksamesMomentderEMzumBegrenzenderDrehzahlaufDrehzahlbegrenzung";
CM_ SG_ 2463978674 EM2_Status_Spgfreiheit "0=Init(ohneFunktion)
1 = Leistungselektronik HV-Komponenten spannungsfrei (U_Zwkr < 20V)
2 = Leistungselektronik HV_Komponenten nicht spannungsfrei (U_Zwkr >= 20V)
3 = Fehler (z. B. Fehler in der Sensorik)";
CM_ SG_ 2463978674 EM2_Status_EoHVL "StatusderHV-SpannungamPWRfürdieFunktionEoHVL";
CM_ SG_ 2463978674 EM2_Max_LeistungMech_Sockel "MaximalmöglichemechanischeLeistungoberhalbdesEckpunkts,bezogenaufdiezugeteilteelektrischeLeistung,";
CM_ SG_ 2463978674 EM2_Max_Moment_Sockel "MaximalmöglichesMomentbiszumEckpunktbezogenaufdiezugeteilteelektrischeLeistung,motorischerBetrieb";
CM_ SG_ 2463978674 EM2_Min_LeistungMech_Sockel "MinimalmöglichemechanischeLeistungoberhalbdesEckpunkts,bezogenaufdiezugeteilteelektrischeLeistung,generatorischerBetrieb";
CM_ SG_ 2463978674 EM2_Min_Moment_Sockel "MinimalmöglichesMomentbiszumEckpunktbezogenaufdiezugeteilteelektrischeLeistung,generatorischerBetrieb";
CM_ SG_ 2463978674 EM2_PerfInd_MaxLeistung "Performance-IndikatorfürdieVerfügbarkeitderMaximalleistung";
CM_ SG_ 2463978674 EM2_PerfInd_MaxMoment "Performance-IndikatorfürdieVerfügbarkeitdesMaximalmoments";
CM_ SG_ 2463978674 EM2_AnlernenElMotor_Anf "DiagnoseanforderungvonE-Maschine/PWR:Hybrid-ControllerschaltetüberMO_EM_Sollmodus=6bzw.MY3_EM_modeReq=6E-Maschine/PWRaktivindenKalibriermodus(Strategiemusssicherstellen,dasskeinMomentbeiderEMangefordertwird.)";
CM_ SG_ 2463978674 EM2_OBD_Lampe_Anf "InallenVW-/Audi-FahrzeugenisteinMIL-Master-Konzeptumgesetzt.DazuermitteltjedesOBD-SteuergerätdeneigenenMIL-Status.EineMIL-AnsteuerungwirdvombetroffenenOBD-SteuergerätperMIL-RequestüberCANandenMIL-Masterweitergegeben.DerMIL-Mas";
CM_ SG_ 2463978674 EM2_Generator_Moment "ErforderlichesgeneratorischesMomentzurDarstellungderelektrischenWunschleistungbeidermomentanenMaschinendrehzahl";
CM_ SG_ 2463978674 EM2_PerfInd_Temperatur "ThermischerPerformance-IndikatorabhängigvonMaschinen-undLE-Temperatur";
CM_ SG_ 2463978674 EM2_MaxZul_Drehzahl "EM2_MaxZul_DrehzahlstelltdiemaximaleDrehzahlgrenzefürLEbzw.EMdardieimFreilaufzulässigist.FürDrehzahlengrößerdieserGrenzewirddieLEzumKomponentenschutzunabhängigvonderKommandierungindenAKSumschalten.";
CM_ SG_ 2463978674 EM2_Min_Moment_Gesamt "MinimalmöglichesMomentbeidermomentanenMaschinendrehzahlbezogenaufdievomSystemaufnehmbareelektrischeGesamtleistungMO_EM1_Min_Leistung_Gesamt,generatorischerBetrieb";
CM_ SG_ 2463978674 EM2_Fehlerlampe_Anf "AnforderungderrotenHybrid-WarnlampeimKombi";
CM_ SG_ 2463978674 EM2_Max_Moment_Gesamt "MaximalmöglichesMomentbeidermomentanenMaschinendrehzahlbezogenaufdieimSystemverfügbareelektrischeGesamtleistungMO_EM1_Max_Leistung_Gesamt,motorischerBetrieb";
CM_ SG_ 2463978674 EM2_Warnlampe_Anf "AnforderungdergelbenHybrid-WarnlampeimKombi";
CM_ SG_ 2463978674 EM2_Rekuperation "Rekuperation-EnergiederEMhinterachsintegriert";
CM_ SG_ 2463978674 EM2_Rekuperation_Ueberlauf "RekuperationleistungssignalEM2_Rekuperationmindest1xübergelaufen";
CM_ SG_ 2463978674 EM2_Verbrauch "Antriebs-EnergiederEM2hinterachsintegriert";
CM_ SG_ 2463978674 EM2_Verbrauch_Ueberlauf "Überlauf-BitfürdasSignalEM2_Verbrauch.
Rekuperationleistungssignal mindest 1x übergelaufen;";
CM_ SG_ 2463978674 EM2_Fehler_AE "AusgabeeinesFehlersinderFunktionaktiveEntladungimPWR";
CM_ SG_ 2463978674 EM2_Fehler_Leistungsred "EingeschränkteLeistungsfähigkeitaufGrundeinsinternenFehlers";
CM_ SG_ 2463978674 EM2_Fehler_ElAntriebFreilauf "Fehler:EMimFreilauf;LeistungselektronikfordertBegrenzungdermaximalenDrehzahlan,umÜberspannungimHV-Zwischenkreiszuvermeiden";
CM_ SG_ 2463978674 EM2_PWR_SollVolumenstrom "FürdieKühlungdesPWRaktuellmindestensbenötigterKühlwasservolumenstrom";
CM_ SG_ 2589283660 EM2_SollVorlauftemperatur "SolltemperaturdesKühlmittelsamVorlaufdesPWR";
CM_ SG_ 2589283660 EM2_Temperatur_EM "TemperaturderE-Maschine";
CM_ SG_ 2589283660 EM2_EM_SollVolumenstrom "FürdieKühlungderE-MaschineaktuellmindestensbenötigterKühlwasservolumenstrom


MQB/MEB: funktional 500ms (Cyclic) Zykluszeit notwendig

MLBevo: funktional 50ms (OnChange) Zykluszeit notwendig";
CM_ SG_ 2589283660 EM2_Max_MechLeistung_nom "MaximaleparametrierteLeistungdeselektrischenAntriebsbestehendausPWRundEM,interneBegrenzung";
CM_ SG_ 2589283660 EM2_Max_Moment_nom "MaximalesparametriertesMomentdeselektrischenAntriebsbestehendausPWRundEM,interneBegrenzung";
CM_ SG_ 2589283660 EM2_Temperatur_PWR "Momentanwert:TemperaturdesPWR";
CM_ SG_ 199 EM2_Freigabe_Info_WFS "WFS-Freigabeinformation

";
CM_ SG_ 199 EM2_Sperr_Info_WFS "WFS-Sperrinformation
";
CM_ SG_ 199 EM2_AR_aktiv "Ruckeldämpferaktiv";
CM_ SG_ 199 EM2_Eta_Sys "InstantaneousefficiencyofelectricaldriveEM2/MomentanerWirkungsgradelektrischerAntriebEM2";
CM_ SG_ 199 EM2_IstStrom "Momentanwert:StromüberPWR";
CM_ SG_ 199 EM2_Fehler_ElAntriebFreilauf_Anf "WirdgesetztumdenzwingendenBedarfeinerUmschaltungindenFreilaufanzuzeigen.VergleicheSignalEM1_MaxZul_Drehzahl.";
CM_ SG_ 199 EM2_Abregelung_Temperatur "LeistungsbegrenzungaufgrundÜbertemperaturderE-Maschine/desPWR";
CM_ SG_ 199 EM2_AnlernenElMotor_Anf "DiagnoseanforderungvonE-Maschine/PWR:Hybrid-ControllerschaltetüberMO_EM_Sollmodus=6bzw.MY3_EM_modeReq=6E-Maschine/PWRaktivindenKalibriermodus(Strategiemusssicherstellen,dasskeinMomentbeiderEMangefordertwird.)";
CM_ SG_ 199 EM2_Freigabe_Verfallsinfo_WFS "WFS";
CM_ SG_ 199 EM2_Parken_WFS_Status "StatusderLimitierung";
CM_ SG_ 199 EM2_HV_betriebsbereit "1:Ready_HV/1:HV-NetzSpannungimBetriebsbereich";
CM_ SG_ 2527679713 EM2_RtmWarnKommunikation "RealTimeMonitoringEM2buscommunicationfault";
CM_ SG_ 2527679713 EM2_RtmWarnUeberdrehzahl "RTMSignaloverspeedwarningEM2";
CM_ SG_ 2527679713 EM2_RtmWarnUeberstrom "RTMSignalover-currentwarningEM2";
CM_ SG_ 2527679713 EM2_RtmWarnTempEM "RTMSignalover-tempwarningEM2";
CM_ SG_ 2527679713 EM2_RtmWarnTempPWR "RTMSignalover-tempwarningEM2-PWR";
CM_ SG_ 2589283649 EML_02_CRC "FürMLB:
Berechnung siehe Lastenheft 'Kommunikationsabsicherung für FlexRay und CAN'
Ab MQB und MLBevo:
Berechnung siehe Lastenheft 'End-to-End Kommunikationsabsicherung'

Endwerte siehe Begleitdokument 'S-PDU Kennungsfolgen'";
CM_ SG_ 2589283649 EML_02_BZ "4bitBotschaftszähler,wirdmitjederSendebotschaftinkrementiert";
CM_ SG_ 2589283649 EML_ReifenKorrFaktorHL "KorrekturfaktorReifenumfangHintenLinks";
CM_ SG_ 2589283649 EML_ReifenKorrFaktorHR "KorrekturfaktorReifenumfangHintenRechts";
CM_ SG_ 2589283649 EML_ReifenKorrFaktorVL "KorrekturfaktorReifenumfangVorneLinks";
CM_ SG_ 2589283649 EML_ReifenKorrFaktorVR "KorrekturfaktorReifenumfangVorneRechts";
CM_ SG_ 2589283649 EML_Reifenumfang "MittlererReifenumfangdesEMLinMillimeter.BeiASIL-AnforderungenistdieFachabteilungzukontaktieren.";
CM_ SG_ 2589283649 EML_QBit_Reifenumfang "QBitdesmittlerenReifenumfangs.GesetztbeiErsatzwert,InitoderFehler.";
CM_ SG_ 608 EML_AnzeigeGeschw "BetragdesaktuellenGeschwindigkeitssignalsinFahrzeugbewegungsrichtungzurAnzeigenachEuroNCAP.BeiASIL-AnforderungenistdieFachabteilungzukontaktieren.";
CM_ SG_ 2589283751 KBI_Kilometerstand_HiRes_meter "HöchauflösenderesSignalalsKBI_Kilometerstand_HiResumUmrechnungzuvermindernundeinehöhereAuflösungals0,1kmzuerhalten.
Auflösung 1m / Bit
4 Byte länge (Doubleword)";
CM_ SG_ 2527679687 EPS_ASM_Ereignis "DiesesSignaldefiniert,welcheFunktionundwelcheArtvonAktivitätdasSendenderBotschaftandenAssistenzsystemmonitorASMveranlassthat.";
CM_ SG_ 2527679687 EPS_ASM_Zeitstempel "DiesesSignalermöglichtdiezeitlicheZuordnungdervonmehrerenFunktionenaufdemEPS-SGandenAssistenzsystemmonitorASMgesendetenStatusbotschaften.";
CM_ SG_ 2527679687 EPS_ASM_Data_1 "DieseSignalwirdvonmehrerenFunktionenaufdemEPS-SGgemäßderASM-DatendefinitionbefülltundandenAssistenzsystemmonitorASMgesendet";
CM_ SG_ 2527679687 EPS_ASM_Data_2 "DieseSignalwirdvonmehrerenFunktionenaufdemEPS-SGgemäßderASM-DatendefinitionbefülltundandenAssistenzsystemmonitorASMgesendet";
CM_ SG_ 2527679687 EPS_ASM_Data_3 "DieseSignalwirdvonmehrerenFunktionenaufdemEPS-SGgemäßderASM-DatendefinitionbefülltundandenAssistenzsystemmonitorASMgesendet";
CM_ SG_ 2527679687 EPS_ASM_Data_4 "DieseSignalwirdvonmehrerenFunktionenaufdemEPS-SGgemäßderASM-DatendefinitionbefülltundandenAssistenzsystemmonitorASMgesendet";
CM_ SG_ 2527679687 EPS_ASM_Data_5 "DieseSignalwirdvonmehrerenFunktionenaufdemEPS-SGgemäßderASM-DatendefinitionbefülltundandenAssistenzsystemmonitorASMgesendet";
CM_ SG_ 2527679687 EPS_ASM_Data_6 "DieseSignalwirdvonmehrerenFunktionenaufdemEPS-SGgemäßderASM-DatendefinitionbefülltundandenAssistenzsystemmonitorASMgesendet";
CM_ SG_ 258 ESC_50_CRC "FürMLB:
Berechnung siehe Lastenheft 'Kommunikationsabsicherung für FlexRay und CAN'
Ab MQB und MLBevo:
Berechnung siehe Lastenheft 'End-to-End Kommunikationsabsicherung'

Endwerte siehe Begleitdokument 'S-PDU Kennungsfolgen'";
CM_ SG_ 258 ESC_50_BZ "4bitBotschaftszähler,wirdmitjederSendebotschaftinkrementiert";
CM_ SG_ 258 ESP_QBit_Gierrate "QBitderGierrate.GesetztbeiErsatzwert,InitoderFehler.
";
CM_ SG_ 258 ESP_QBit_Laengsbeschl "QBitderLängsbeschleunigung.GesetztbeiErsatzwert,InitoderFehler.
";
CM_ SG_ 258 ESP_QBit_Querb "QBitderQuerbeschleunigung.GesetztbeiErsatzwert,InitoderFehler.";
CM_ SG_ 258 ESP_Querbeschleunigung "Beschleunigungswertiny-Achse

MLB: Gemessener Wert
0xFF = Fehler (wie bereits im Wertebereich spezifizert)
Bei ESP-Abschaltung durch modellgestützte Überwachung wird das Signal weiterhin ausgegeben.
Im AU64x und AU57x erfolgt die Bereitstellung der";
CM_ SG_ 258 ESP_Laengsbeschl "Beschleunigungswertinx-Achse

MLB: Im AU64x und AU57x erfolgt die Bereitstellung der Sensorwerte durch SARA-SG! Im AU64x und AU57x wird bei ESP-Abschaltung durch modellgestützte Überwachung das Signal weiterhin ausgegeben.

MQB: reines ABS schickt 0";
CM_ SG_ 258 ESC_Motorstartverzoegerung "MitdemSignal'Motorstartverzögerung'wirddenaktivenTeilnehmernermöglicht,einenMotorstartdurchdieStart-Stop-Funktionzuverzögern.";
CM_ SG_ 258 ESC_SeitenwindAssistent_Eingriff "MitdiesemStatusbitwirdeineaktiveRegelungdurchdenSeitenwindassistentensignalisiert.";
CM_ SG_ 258 ESP_Anschleppstart_Freigabe "BildeneinerSchleppstartfreigabeausFahrdynamiksicht.SchleppstartabbruchbeikritischerFahrzeugstabilität";
CM_ SG_ 258 ESC_Unterdruckmangel_erkannt "ESChateinenUnterdruckmangelimBremskraftverstärkerfestgestellt";
CM_ SG_ 258 ESP_Gierrate "Winkelgeschwindigkeitumdiez-Achse,ESP_VZ_Gierrate&ESP_QBit_Gierratebeachten!!!

MLB: gemessener Wert
tatsächliche Auflösung Bosch ESP: 0,27 Grad/s

Ab AU64x Auflösung wie die tatsächliche Skalierung 0,01. Im AU64x und AU57x wird bei ESP-Absch";
CM_ SG_ 258 ESP_VZ_Gierrate "VorzeichenderGierrate";
CM_ SG_ 258 ESP_Notbremsanzeige "ABS/ASRoderESPhatNotbremssituationerkannt.
Weiterführende Informationen im Lastenheft spezifiziert und in der entsprechenden Fachabteilung zu erfragen.

";
CM_ SG_ 258 ESP_SpannungsAnf "DieRekuperationkannmitderAnforderungeinerhöherenSpannungeingeschränktwerden.";
CM_ SG_ 258 ESP_PLA_Abbruch "WennderBremseingriffabgebrochenwurde,wirdindiesemSignalderGrunddesAbbruchsdargestellt.
Dies ist nur gültig, wenn der Status ESP_Status_ESP_PLA = '0xA' ist.";
CM_ SG_ 258 ESP_Status_ESP_PLA "ZustandderStatusmaschinederBremsefürdiekorrespondierendeStatusmaschineindemPLA-SG";
CM_ SG_ 258 ESP_QBit_Bremsdruck "QBitdesBremsdrucks.GesetztbeiErsatzwert,InitoderFehler.";
CM_ SG_ 258 ESP_QBit_Fahrer_bremst "GültigkeitderBremsdruckschwelleninformationdesSignalsESP_Fahrer_bremstvomESPSG
0x1 = Druckschwelleninformation kann noch nicht oder aufgrund eines Fehlers nicht ausgegeben werden
";
CM_ SG_ 258 ESP_Schwelle_Unterdruck "VerwendungimMQBfürHBV-ProjekteoderwennfürSt/SteinUnterdrucksensorverbautist";
CM_ SG_ 258 ESP_Bremsdruck "RohwertdesBremsdrucks
Für Fahrzeuge mit elektrischem Bremskraftverstärker gilt: Aus dem Signal ESP_Bremsdruck lässt sich kein Fahrerbremswunsch ableiten. Das Signal bildet lediglich den hydraulischen Anteil der Fahrzeugverzögerung ab. Der Rohwert des S";
CM_ SG_ 258 ESP_Fahrer_bremst "BitwirdgesetztbeimÜberschreitenderBremsdruckschwelle

Weiterführende Informationen im Lastenheft spezifiziert und in der entsprechenden Fachabteilung zu erfragen.
";
CM_ SG_ 258 ESP_Verz_TSK_aktiv "RückmeldeinformationandenTriebsstrangkoordinator/ACC,dassdieECD-Verzögerungsanforderungaktuellumgesetztwird";
CM_ SG_ 258 ESP_Lenkeingriff_ADS "ImFalleeinesfahrzeugstabilisierendenLenkeingriffsdesADS-SystemssollACC/GRAdeaktiviertwerden.

Im MQB wird dieses Signal nicht unterstützt!";
CM_ SG_ 258 ESP_Konsistenz_TSK "RückmeldungzumSendereinerVerzögerungsanforderung(Triebstrangskoordinator)bezüglichPrüfungderChecksumme,desBotschaftszählers,deslangenTimeoutundDLC.WirdauchgesetztbeiVerzögerungsanforderunggrößereinerapplizierbarenSchwelle.
";
CM_ SG_ 258 ESP_Bremsruck_AWV2 "DasSignaldientalsRückmeldungzumACC,dasseinangeforderterAWV2-Bremsruckdurchgeführtwird.DiepositiveRückmeldunglöstu.a.eineentsprechendeFahrerinformationimKombiinstrumentaus";
CM_ SG_ 258 ESP_Konsistenz_AWV2 "RückmeldungzumSendereinerAWV-Anforderung(ACC-Steuergerät)bezüglichPrüfungderChecksumme,desBotschaftszählers,deslangenTimeoutundDLC.
";
CM_ SG_ 258 ECD_Fehler "ESPkanndieVerzögerungsregelung/BremsenregelungaufgrundeinesinternenFehlersnichtausführen,mitFehlereintragimESP.
";
CM_ SG_ 258 ECD_nicht_verfuegbar "ESPkanndieVerzögerungsregelung/Bremsenregelungtemporärnichtausführen(z.B.Netzwerkmanagement-Betriebe-KL15Aus;v<18km/h;ESPinDiagnose,...),ohneFehlereintragimESP.

";
CM_ SG_ 258 ESP_Status_Bremsentemp "ECD-Bremsscheibentemperaturmodell.RückmeldungfürSendereinerECDVerzögerungsanforderung,ohneFehlereintragimESP";
CM_ SG_ 258 ESP_Autohold_Standby "RückmeldunganEPB,dassderFahrerdieFunktionAutoholdmindestenseinmalangeforderthat.ImFalleinesESP-AusfallesodereinerÜbernahmeaufforderungerfolgtdieEPB-ZuschaltungnurnachSetzendiesesBits.BitwirdgesetztnachBetätigungdesAutohol";
CM_ SG_ 258 ESP_HDC_Standby "Verwendung/BedienungimMQBundAU57xAllroad:
Flag wird vom ESP gesetzt, wenn über den HDC-Taster die HDC-Funktion eingeschalten wurde";
CM_ SG_ 258 ESP_HBA_aktiv "Verwendung/BedienungabD4
Signal gibt an, ob der hydraulische Bremsassistent im Regler aktiviert wurde

Im MQB wird das Signal nicht unterstützt!

";
CM_ SG_ 258 ESP_Prefill_ausgeloest "MLB:Verwendung/BedienungabD4
zeigt, ob die Funktion Prefill (aufgrund Fahrpedalgradient) ausgelöst wird; zeigt keinen Funktionszustand bezüglich Fehlerstilllegung

MQB: Wird gesetzt bei jeder Art von aktivem Prefill";
CM_ SG_ 258 ESP_Rueckwaertsfahrt_erkannt "nurbeiAU57xundAU416sowieAudiB8PA
Info, ob Rückwärtsfahrt über internen Algorithmus sicher erkannt

Im MQB wird das Signal nicht unterstützt!";
CM_ SG_ 258 ESP_Status_Anfahrhilfe "FunktionsstatusdesBerganfahrassistenten
MQB: Auswertung im Getriebe zwecks Standabkopplung";
CM_ SG_ 258 ESP_HDC_aktiv "MQBundAU57xAllroad:MitdiesemStatusbitwirdeinegeradeaktiveRegelungdesBergabfahrassistenten(HillDescentControl)signalisiert.";
CM_ SG_ 258 ESP_StartStopp_Info "Stopp-FreigabeundStart-AnforderungandenStart-Stopp-Koordinator";
CM_ SG_ 258 ESP_Eingr_HL "wirdvonQSPundNeigungsanzeigeverwendet

Flag wird vom ESP gesetzt, sobald aufgrund eines ESP-Eingriffs am Rad aktiv Druck aufgebaut wird.
Frühestens mit öffnen des Ventils und spätestens bei einem Bremsmoment von 100Nm. Flag bleibt solange gesetzt ";
CM_ SG_ 258 ESP_Eingr_HR "wirdvonQSPundNeigungsanzeigeverwendet

Flag wird vom ESP gesetzt, sobald aufgrund eines ESP-Eingriffs am Rad aktiv Druck aufgebaut wird.
Frühestens mit öffnen des Ventils und spätestens bei einem Bremsmoment von 100Nm. Flag bleibt solange gesetzt ";
CM_ SG_ 258 ESP_Eingr_VL "wirdvonQSPundNeigungsanzeigeverwendet

Flag wird vom ESP gesetzt, sobald aufgrund eines ESP-Eingriffs am Rad aktiv Druck aufgebaut wird.
Frühestens mit öffnen des Ventils und spätestens bei einem Bremsmoment von 100Nm. Flag bleibt solange gesetzt ";
CM_ SG_ 258 ESP_Eingr_VR "wirdvonQSPundNeigungsanzeigeverwendet

Flag wird vom ESP gesetzt, sobald aufgrund eines ESP-Eingriffs am Rad aktiv Druck aufgebaut wird.
Frühestens mit öffnen des Ventils und spätestens bei einem Bremsmoment von 100Nm. Flag bleibt solange gesetzt ";
CM_ SG_ 258 ESP_BKV_Unterdruck "DermaximaleWertwirdauf1012mbarbegrenzt.
Dieses Signal wird im AU64x nicht unterstützt.

Hinweis: Auch bei nicht verbautem BKV-Unterdrucksensor könnte während der Initialisierung der Initialisierungswert gesendet werden.";
CM_ SG_ 258 ESP_Autohold_aktiv "RückmeldunganEPB,dassAutoholdaktivist.";
CM_ SG_ 258 ESP_FStatus_Anfahrhilfe "BeigesetztemBitstehtdieFunktionBerganfahrassistent(Hillhold)nichtzurVerfügung";
CM_ SG_ 258 ESP_Verz_EPB_aktiv "BeigesetztemBitwirddieVerzögerungsanforderungvonEPBumgesetzt.";
CM_ SG_ 258 ECD_Bremslicht "BremslichtansteuerungdurchECD-Funktion";
CM_ SG_ 258 ESP_Verzoeg_EPB_verf "BeigesetztemBitistderVerzögerungsregelerfürEPBverfügbar.";
CM_ SG_ 258 ESP_Status_Bremsdruck "MLB:BeigesetztemBitliegtp>ca.2baran,hervorgerufendurchFahrer,ASR,FZR,ECD,Bremsregler...beiAbfalldesBitsistp<Xbar,beiaktivemECD-EingriffEndedesEingriffs

Weiterführende Informationen im Lastenheft spezifiziert und in der";
CM_ SG_ 258 ESP_Anforderung_EPB "ESPfordertvonderEPBÖffnenbzw.Schliessenan.NotwendigwegenAutohold-Funktion.";
CM_ SG_ 258 ESP_ANB_CM_Rueckk_Umsetz "DasSignaldientalsRückmeldungzumACC,dasseineangeforderteANB-CMdurchgeführtwird.DiepositiveRückmeldunglöstu.a.eineentsprechendeFahrerinformationimKombiinstrumentaus";
CM_ SG_ 258 ESP_Konsistenz_ACC_Botschaft "RückmeldungzumSenderderVerzögerungsanforderungACCbezüglichPrüfungCHK/CRC,BZundlangerTimeout.WirdauchgesetztbeieinerVerzögerungsanforderunggrößeralseineapplizierbareSchwelle.

Im D4/C7: Botschaft ACC_05
Im MQB: Botschaft ACC_07";
CM_ SG_ 258 ESP_Stillstandsphase_erschoepft "RückmeldungvomESP,dasseineangefordertessicheresHaltenimStillstandnichtmehrlängermöglichist.";
CM_ SG_ 258 ESP_ZT_Rueckk_Umsetz "DasSignaldientalsRückmeldungzumACC,dasseineangeforderteZielbremsung/Teilbremsungdurchgeführtwird.DiepositiveRückmeldunglöstu.a.eineentsprechendeFahrerinformationimKombiinstrumentaus";
CM_ SG_ 258 ESP_Tuerkontakt_Fahrertuer "LogischerPegelderHW-LeitungzumTürkontaktschalterimESP-SG.
0 > Schalter geschlossen
1 > Schalter offen

Ungefilterter und unplausibilisierter Status der HW-Leitung vom Fahrertür-Türkontaktschalter zum ESP.
Redundanz für Systemsicherheit notwend";
CM_ SG_ 258 ESP_Abrutschen_Stillstand "DasESPteiltüberdiesesBitmit,dasseinAbrutschenimStillstanderkanntwurde.

Im MQB wird das Signal nicht unterstützt!";
CM_ SG_ 258 ESP_Fahrer_tritt_ZBR_Schw "RückmeldungdesESPanAWV,obderFahrerdieaktuellgültigeZBR-Schwelleübertritt";
CM_ SG_ 258 ESP_QBit_v_ref "QBitderReferenzgeschwindigkeitESP_v_ref.GesetztbeiErsatzwert,InitoderFehler.
Detailinformationen zu dem Signal sind dem Lastenheft 'Signalexport - Funktionale Anforderungen an ESP' zu entnehmen - Signal ESP_St_v_fzg_ref";
CM_ SG_ 258 ESP_v_ref_Fahrtrichtung "SignalstelltdieInformationenüberdieFahrtrichtungdesFahrzeugesdar.SiewirdalsVorzeichenderReferenzgeschwindigkeitESP_v_refinterpretiertundbasiertaufdenDrehrichtungenderRäder.
Detailinformationen zu dem Signal sind dem Lastenheft 'Si";
CM_ SG_ 258 ESC_Bremsdruckgradient "DasSignalzeigtdenvomFahrergedrucktenBremsdruckgradienten";
CM_ SG_ 258 ESP_v_ref "MLBevo:
Signal wird nur von einem BOSCH ESP System zur Verfügung gestellt. Exklusives Signal vom BOSCH ESP zum BOSCH Airbag für ROSEII Funktion und für Fahrwerkregelsysteme.
Verwendung nur nach vorheriger Abstimmung mit den verantwortlichen EF Fachbere";
CM_ SG_ 258 ESC_Hydr_Fkt_aktiv "InfoüberdieAktivitätvonDruckaufbaufunktionenimESCundUebermittlungdesWarnlevelanEBKV.";
CM_ SG_ 258 ESC_QBit_Fahrerbremswunsch "GesetztbeiErsatzwert,InitoderFehler.";
CM_ SG_ 258 ESC_Fahrerbremswunsch "PHEV:BerechneterDruckanhanddeseBKV-AusgangsstangenwegssowieESP-pMC.Rekunichtaktiv-->vergleichbarmitESP_Bremsdruck;Rekuaktiv-->virtuellerBremsdruck
Konv.: entspricht ESP_Bremsdruck";
CM_ SG_ 258 ESCGeneratorSollMoment "InMLBevoFaktorinTS_Faktor_Radmomentebeachten!

Verzögernd wirkender Antriebsstrangsollmomentenanteil aus Bremspedalbetätigung auf Summenradebene.";
CM_ SG_ 258 ESC_Raddruck_max "StelltdenzahlenmäßighöchstenDruckwertderviermodelliertenRaddrückedar.";
CM_ SG_ 258 EPB_Freig_Verzoeg_Anf "Verzögerungsanforderung	";
CM_ SG_ 258 EPB_Verzoeg_Anf "SteuerungsanforderunganandereSysteme(z.B.ESP),umwährendderFahrt,durchdenHandbremsschalterausgelöst,zubremsen(ECD-Funktion)";
CM_ SG_ 258 EPB_Pedalweg_Kuppl "SignalentsprichtTastverhältnisdesPWM.GesamtwegKupplungspedal10%bis90%,damitzuerwartendeWerte25bis225.25beiKupplungspedalnichtgetreten,225beiKupplungspedalvolldurchgetreten.
2% Toleranz wird im Wertebereich ermöglicht (8%-92%).
";
CM_ SG_ 258 EPB_DAA_Randbed_erf "DieRandbedingungenzumautomatischenÖffnenderEPB(FunktionDAA)sinderfülltundeinBetätigendesFahrpedalsführtzumÖffnenderEPB.";
CM_ SG_ 258 EPB_Fehlerstatus_02 "AnpassungderTexteandieaktuellenZuständefürweitergehendeFunktionen(Stillstandsmanager)";
CM_ SG_ 258 EPB_Schalterposition "SpiegeltdieSchalterstellungwieder.

0x3 = Schalterfehler ";
CM_ SG_ 258 EPB_Spannkraft "ErzeugteSpannkraft.BeziehtsichaufdieAktuatoren.

MQB: Spannkraftwerte entsprechen nicht den tatsächlichen Spannkräften. Genauere Informationen bitte in der Fachabteilung erfragen! ";
CM_ SG_ 258 EPB_Status_02 "ErweiterungderZuständeumeingenaueresBilddesaktuellenZustandeszuerhaltenfürweitergehendeFunktionen(Stillstandsmanager)
";
CM_ SG_ 258 EPB_Status "GibtdenZustandderEPB-Aktuatorenan.

Nur VW526/PAG E2: Wert 0x3 bedeutet 'unbekannt'

";
CM_ SG_ 258 ESP_Status_Bremsentemp_02 "Bremsscheibentemperaturmodell.RückmeldungfürSendereinerVerzögerungsanforderung";
BA_DEF_ BO_ "DiagRequest" ENUM "No", "Yes";
BA_DEF_ BO_ "DiagResponse" ENUM "No", "Yes";
BA_DEF_ BO_ "DiagState" ENUM "No", "Yes";
BA_DEF_ BO_ "GenMsgChkConstant" HEX 0 4095;
BA_DEF_ BO_ "GenMsgCycleTime" INT 0 65535;
BA_DEF_ BO_ "GenMsgCycleTimeFast" INT 0 65535;
BA_DEF_ BO_ "GenMsgDelayTime" INT 0 100000;
BA_DEF_ BO_ "GenMsgILSupport" ENUM "No", "Yes";
BA_DEF_ BO_ "GenMsgNrOfRepetition" INT 0 100;
BA_DEF_ BO_ "GenMsgPDUConstants" STRING;
BA_DEF_ BO_ "GenMsgSendType" ENUM "Cyclic", "not_used", "not_used", "not_used", "not_used", "not_used", "not_used", "IfActive", "NoMsgSendType";
BA_DEF_ BO_ "GenMsgStartDelayTime" INT 0 100000;
BA_DEF_ BO_ "NmMessage" ENUM "No", "Yes";
BA_DEF_ BO_ "NmhMessage" ENUM "No", "Yes";
BA_DEF_ BO_ "MsgType" ENUM "Application", "NM", "NMH", "TP2.0", "ISO-TP", "BAP", "EID", "KS";
BA_DEF_ BO_ "VAGTP20_API" HEX 0 255;
BA_DEF_ BO_ "VAGTP20_DynConnection" ENUM "No", "Yes";
BA_DEF_ BO_ "VAGTP20_DynSetup" ENUM "No", "Yes";
BA_DEF_ BO_ "VAGTP20_StatConnection" ENUM "No", "Yes";
BA_DEF_ BO_ "CANFD_BRS" ENUM "0", "1";
BA_DEF_ BO_ "VFrameFormat" ENUM "StandardCAN", "ExtendedCAN", "reserved", "reserved", "reserved", "reserved", "reserved", "reserved", "reserved", "reserved", "reserved", "reserved", "reserved", "reserved", "StandardCAN_FD", "ExtendedCAN_FD";
BA_DEF_ SG_ "GenSigActiveRepetitions" INT -2147483648 2147483647;
BA_DEF_ SG_ "GenSigInactiveValue" INT -2147483648 2147483647;
BA_DEF_ SG_ "GenSigSendType" ENUM "Cyclic", "OnWrite", "OnWriteWithRepetition", "OnChange", "OnChangeWithRepetition", "IfActive", "IfActiveWithRepetition", "NoSigSendType", "OnChangeAndIfActive", "OnChangeAndIfActiveWithRepetition";
BA_DEF_ SG_ "GenSigStartValue" INT -2147483648 2147483647;
BA_DEF_ SG_ "NWM-WakeupAllowed" ENUM "No", "Yes";
BA_DEF_ SG_ "GenSigFuncType" ENUM "NoFunction", "MsgCounter", "CRC-8", "XOR", "XOR-2", "DatedBit", "SW-Kl15", "CHK", "Constant", "Protocol", "CRC-8-SAE_J1850";
BA_DEF_ SG_ "GenSigSwitchedByIgnition" ENUM "No", "Yes";
BA_DEF_ SG_ "Fehlerwert" HEX 0 2147483647;
BA_DEF_ SG_ "GenSigMissingSourceValue" HEX 0 2147483647;
BA_DEF_DEF_  "DiagRequest" "No";
BA_DEF_DEF_  "DiagResponse" "No";
BA_DEF_DEF_  "DiagState" "No";
BA_DEF_DEF_  "GenMsgChkConstant" 0;
BA_DEF_DEF_  "GenMsgCycleTime" 0;
BA_DEF_DEF_  "GenMsgCycleTimeFast" 0;
BA_DEF_DEF_  "GenMsgDelayTime" 0;
BA_DEF_DEF_  "GenMsgILSupport" "No";
BA_DEF_DEF_  "GenMsgNrOfRepetition" 0;
BA_DEF_DEF_  "GenMsgPDUConstants" "";
BA_DEF_DEF_  "GenMsgSendType" "NoMsgSendType";
BA_DEF_DEF_  "GenMsgStartDelayTime" 0;
BA_DEF_DEF_  "NmMessage" "No";
BA_DEF_DEF_  "NmhMessage" "No";
BA_DEF_DEF_  "MsgType" "Application";
BA_DEF_DEF_  "VAGTP20_API" 0;
BA_DEF_DEF_  "VAGTP20_DynConnection" "No";
BA_DEF_DEF_  "VAGTP20_DynSetup" "No";
BA_DEF_DEF_  "VAGTP20_StatConnection" "No";
BA_DEF_DEF_  "CANFD_BRS" "1";
BA_DEF_DEF_  "VFrameFormat" "StandardCAN";
BA_DEF_DEF_  "GenSigActiveRepetitions" 0;
BA_DEF_DEF_  "GenSigInactiveValue" 0;
BA_DEF_DEF_  "GenSigSendType" "NoSigSendType";
BA_DEF_DEF_  "GenSigStartValue" 0;
BA_DEF_DEF_  "NWM-WakeupAllowed" "No";
BA_DEF_DEF_  "GenSigFuncType" "NoFunction";
BA_DEF_DEF_  "GenSigSwitchedByIgnition" "Yes";
BA_DEF_DEF_  "Fehlerwert" 0;
BA_DEF_DEF_  "GenSigMissingSourceValue" 0;
BA_ "GenMsgCycleTime" BO_ 514 20;
BA_ "GenMsgILSupport" BO_ 514 "Yes";
BA_ "GenMsgSendType" BO_ 514 "Cyclic";
BA_ "VFrameFormat" BO_ 514 "StandardCAN_FD";
BA_ "GenMsgCycleTime" BO_ 1485 500;
BA_ "GenMsgCycleTimeFast" BO_ 1485 100;
BA_ "GenMsgDelayTime" BO_ 1485 50;
BA_ "GenMsgILSupport" BO_ 1485 "Yes";
BA_ "GenMsgNrOfRepetition" BO_ 1485 5;
BA_ "GenMsgPDUConstants" BO_ 1485 "0x93,0x04,0x18,0x69,0xce,0x8f,0xb1,0x53,0x40,0x2d,0xe4,0xca,0x90,0x25,0x79,0x8c";
BA_ "GenMsgSendType" BO_ 1485 "Cyclic";
BA_ "VFrameFormat" BO_ 1485 "StandardCAN_FD";
BA_ "GenMsgCycleTime" BO_ 247 10;
BA_ "GenMsgILSupport" BO_ 247 "Yes";
BA_ "GenMsgPDUConstants" BO_ 247 "0x5f,0xa0,0x44,0xd0,0x63,0x59,0x5b,0xa2,0x68,0x04,0x90,0x87,0x52,0x12,0xb4,0x9e";
BA_ "GenMsgSendType" BO_ 247 "Cyclic";
BA_ "VFrameFormat" BO_ 247 "StandardCAN_FD";
BA_ "MsgType" BO_ 2617027088 "EID";
BA_ "CANFD_BRS" BO_ 2617027088 "0";
BA_ "VFrameFormat" BO_ 2617027088 "ExtendedCAN";
BA_ "MsgType" BO_ 2617027072 "EID";
BA_ "CANFD_BRS" BO_ 2617027072 "0";
BA_ "VFrameFormat" BO_ 2617027072 "ExtendedCAN";
BA_ "MsgType" BO_ 2617027073 "EID";
BA_ "CANFD_BRS" BO_ 2617027073 "0";
BA_ "VFrameFormat" BO_ 2617027073 "ExtendedCAN";
BA_ "MsgType" BO_ 2617027074 "EID";
BA_ "CANFD_BRS" BO_ 2617027074 "0";
BA_ "VFrameFormat" BO_ 2617027074 "ExtendedCAN";
BA_ "MsgType" BO_ 2617027075 "EID";
BA_ "CANFD_BRS" BO_ 2617027075 "0";
BA_ "VFrameFormat" BO_ 2617027075 "ExtendedCAN";
BA_ "MsgType" BO_ 2617027076 "EID";
BA_ "CANFD_BRS" BO_ 2617027076 "0";
BA_ "VFrameFormat" BO_ 2617027076 "ExtendedCAN";
BA_ "MsgType" BO_ 2617027077 "EID";
BA_ "CANFD_BRS" BO_ 2617027077 "0";
BA_ "VFrameFormat" BO_ 2617027077 "ExtendedCAN";
BA_ "MsgType" BO_ 2617027078 "EID";
BA_ "CANFD_BRS" BO_ 2617027078 "0";
BA_ "VFrameFormat" BO_ 2617027078 "ExtendedCAN";
BA_ "MsgType" BO_ 2617027079 "EID";
BA_ "CANFD_BRS" BO_ 2617027079 "0";
BA_ "VFrameFormat" BO_ 2617027079 "ExtendedCAN";
BA_ "MsgType" BO_ 2617027080 "EID";
BA_ "CANFD_BRS" BO_ 2617027080 "0";
BA_ "VFrameFormat" BO_ 2617027080 "ExtendedCAN";
BA_ "MsgType" BO_ 2617027081 "EID";
BA_ "CANFD_BRS" BO_ 2617027081 "0";
BA_ "VFrameFormat" BO_ 2617027081 "ExtendedCAN";
BA_ "MsgType" BO_ 2617027082 "EID";
BA_ "CANFD_BRS" BO_ 2617027082 "0";
BA_ "VFrameFormat" BO_ 2617027082 "ExtendedCAN";
BA_ "MsgType" BO_ 2617027083 "EID";
BA_ "CANFD_BRS" BO_ 2617027083 "0";
BA_ "VFrameFormat" BO_ 2617027083 "ExtendedCAN";
BA_ "MsgType" BO_ 2617154048 "EID";
BA_ "VFrameFormat" BO_ 2617154048 "ExtendedCAN_FD";
BA_ "MsgType" BO_ 2617154049 "EID";
BA_ "VFrameFormat" BO_ 2617154049 "ExtendedCAN_FD";
BA_ "MsgType" BO_ 2617154050 "EID";
BA_ "VFrameFormat" BO_ 2617154050 "ExtendedCAN_FD";
BA_ "MsgType" BO_ 2617154051 "EID";
BA_ "VFrameFormat" BO_ 2617154051 "ExtendedCAN_FD";
BA_ "MsgType" BO_ 2617154052 "EID";
BA_ "VFrameFormat" BO_ 2617154052 "ExtendedCAN_FD";
BA_ "MsgType" BO_ 2617154053 "EID";
BA_ "VFrameFormat" BO_ 2617154053 "ExtendedCAN_FD";
BA_ "DiagRequest" BO_ 2549876269 "Yes";
BA_ "MsgType" BO_ 2549876269 "ISO-TP";
BA_ "VFrameFormat" BO_ 2549876269 "ExtendedCAN_FD";
BA_ "DiagResponse" BO_ 2550007341 "Yes";
BA_ "MsgType" BO_ 2550007341 "ISO-TP";
BA_ "VFrameFormat" BO_ 2550007341 "ExtendedCAN_FD";
BA_ "GenMsgCycleTime" BO_ 1714 1000;
BA_ "GenMsgILSupport" BO_ 1714 "Yes";
BA_ "GenMsgSendType" BO_ 1714 "Cyclic";
BA_ "VFrameFormat" BO_ 1714 "StandardCAN_FD";
BA_ "GenMsgCycleTime" BO_ 851 80;
BA_ "GenMsgILSupport" BO_ 851 "Yes";
BA_ "GenMsgPDUConstants" BO_ 851 "0x3a,0x97,0x6b,0x70,0x1e,0x84,0xe1,0xb4,0xde,0xb8,0x03,0xe7,0x33,0x20,0x3f,0x7c";
BA_ "GenMsgSendType" BO_ 851 "Cyclic";
BA_ "VFrameFormat" BO_ 851 "StandardCAN_FD";
BA_ "GenMsgCycleTime" BO_ 1520 200;
BA_ "GenMsgDelayTime" BO_ 1520 50;
BA_ "GenMsgILSupport" BO_ 1520 "Yes";
BA_ "GenMsgSendType" BO_ 1520 "Cyclic";
BA_ "VFrameFormat" BO_ 1520 "StandardCAN_FD";
BA_ "GenMsgCycleTime" BO_ 420 500;
BA_ "GenMsgCycleTimeFast" BO_ 420 20;
BA_ "GenMsgDelayTime" BO_ 420 20;
BA_ "GenMsgILSupport" BO_ 420 "Yes";
BA_ "GenMsgNrOfRepetition" BO_ 420 5;
BA_ "GenMsgPDUConstants" BO_ 420 "0x69,0xbb,0x54,0xe6,0x4e,0x46,0x8d,0x7b,0xea,0x87,0xe9,0xb3,0x63,0xce,0xf8,0xbf";
BA_ "GenMsgSendType" BO_ 420 "Cyclic";
BA_ "VFrameFormat" BO_ 420 "StandardCAN_FD";
BA_ "GenMsgCycleTime" BO_ 374 20;
BA_ "GenMsgILSupport" BO_ 374 "Yes";
BA_ "GenMsgPDUConstants" BO_ 374 "0x3c,0x60,0xeb,0x76,0x91,0x27,0x04,0x02,0xa4,0x3a,0x3f,0xa8,0x24,0x32,0x38,0x51";
BA_ "GenMsgSendType" BO_ 374 "Cyclic";
BA_ "VFrameFormat" BO_ 374 "StandardCAN_FD";
BA_ "GenMsgCycleTime" BO_ 1603 1000;
BA_ "GenMsgDelayTime" BO_ 1603 100;
BA_ "GenMsgILSupport" BO_ 1603 "Yes";
BA_ "GenMsgSendType" BO_ 1603 "Cyclic";
BA_ "VFrameFormat" BO_ 1603 "StandardCAN_FD";
BA_ "GenMsgCycleTime" BO_ 192 10;
BA_ "GenMsgILSupport" BO_ 192 "Yes";
BA_ "GenMsgPDUConstants" BO_ 192 "0x2f,0x44,0x72,0xd3,0x07,0xf2,0x39,0x09,0x8d,0x6f,0x57,0x20,0x37,0xf9,0x9b,0xfa";
BA_ "GenMsgSendType" BO_ 192 "Cyclic";
BA_ "VFrameFormat" BO_ 192 "StandardCAN_FD";
BA_ "GenMsgCycleTime" BO_ 2463978673 100;
BA_ "GenMsgILSupport" BO_ 2463978673 "Yes";
BA_ "GenMsgSendType" BO_ 2463978673 "Cyclic";
BA_ "VFrameFormat" BO_ 2463978673 "ExtendedCAN_FD";
BA_ "GenMsgCycleTime" BO_ 2589283657 500;
BA_ "GenMsgILSupport" BO_ 2589283657 "Yes";
BA_ "GenMsgSendType" BO_ 2589283657 "Cyclic";
BA_ "VFrameFormat" BO_ 2589283657 "ExtendedCAN_FD";
BA_ "GenMsgCycleTime" BO_ 184 500;
BA_ "GenMsgDelayTime" BO_ 184 20;
BA_ "GenMsgILSupport" BO_ 184 "Yes";
BA_ "GenMsgSendType" BO_ 184 "Cyclic";
BA_ "VFrameFormat" BO_ 184 "StandardCAN_FD";
BA_ "GenMsgCycleTime" BO_ 2527679712 1000;
BA_ "GenMsgILSupport" BO_ 2527679712 "Yes";
BA_ "GenMsgSendType" BO_ 2527679712 "Cyclic";
BA_ "VFrameFormat" BO_ 2527679712 "ExtendedCAN_FD";
BA_ "GenMsgCycleTime" BO_ 193 10;
BA_ "GenMsgILSupport" BO_ 193 "Yes";
BA_ "GenMsgPDUConstants" BO_ 193 "0xd7,0x12,0x85,0x7e,0x0b,0x34,0xfa,0x16,0x7a,0x25,0x2d,0x8f,0x04,0x8e,0x5d,0x35";
BA_ "GenMsgSendType" BO_ 193 "Cyclic";
BA_ "VFrameFormat" BO_ 193 "StandardCAN_FD";
BA_ "GenMsgCycleTime" BO_ 2463978674 100;
BA_ "GenMsgILSupport" BO_ 2463978674 "Yes";
BA_ "GenMsgSendType" BO_ 2463978674 "Cyclic";
BA_ "VFrameFormat" BO_ 2463978674 "ExtendedCAN_FD";
BA_ "GenMsgCycleTime" BO_ 2589283660 500;
BA_ "GenMsgILSupport" BO_ 2589283660 "Yes";
BA_ "GenMsgSendType" BO_ 2589283660 "Cyclic";
BA_ "VFrameFormat" BO_ 2589283660 "ExtendedCAN_FD";
BA_ "GenMsgCycleTime" BO_ 199 500;
BA_ "GenMsgDelayTime" BO_ 199 20;
BA_ "GenMsgILSupport" BO_ 199 "Yes";
BA_ "GenMsgSendType" BO_ 199 "Cyclic";
BA_ "VFrameFormat" BO_ 199 "StandardCAN_FD";
BA_ "GenMsgCycleTime" BO_ 2527679713 1000;
BA_ "GenMsgILSupport" BO_ 2527679713 "Yes";
BA_ "GenMsgSendType" BO_ 2527679713 "Cyclic";
BA_ "VFrameFormat" BO_ 2527679713 "ExtendedCAN_FD";
BA_ "GenMsgCycleTime" BO_ 2589283649 200;
BA_ "GenMsgILSupport" BO_ 2589283649 "Yes";
BA_ "GenMsgPDUConstants" BO_ 2589283649 "0x3e,0xb4,0x25,0xc1,0x31,0x1f,0xf1,0xd7,0xb1,0xbe,0xcc,0xe0,0x0f,0x46,0x51,0xb2";
BA_ "GenMsgSendType" BO_ 2589283649 "Cyclic";
BA_ "VFrameFormat" BO_ 2589283649 "ExtendedCAN_FD";
BA_ "GenMsgCycleTime" BO_ 608 50;
BA_ "GenMsgILSupport" BO_ 608 "Yes";
BA_ "GenMsgSendType" BO_ 608 "Cyclic";
BA_ "VFrameFormat" BO_ 608 "StandardCAN_FD";
BA_ "GenMsgCycleTime" BO_ 2589283751 500;
BA_ "GenMsgILSupport" BO_ 2589283751 "Yes";
BA_ "GenMsgSendType" BO_ 2589283751 "Cyclic";
BA_ "VFrameFormat" BO_ 2589283751 "ExtendedCAN_FD";
BA_ "GenMsgCycleTime" BO_ 2527679687 2000;
BA_ "GenMsgDelayTime" BO_ 2527679687 100;
BA_ "GenMsgILSupport" BO_ 2527679687 "Yes";
BA_ "GenMsgSendType" BO_ 2527679687 "Cyclic";
BA_ "VFrameFormat" BO_ 2527679687 "ExtendedCAN_FD";
BA_ "GenMsgCycleTime" BO_ 258 20;
BA_ "GenMsgILSupport" BO_ 258 "Yes";
BA_ "GenMsgPDUConstants" BO_ 258 "0xd7,0x12,0x85,0x7e,0x0b,0x34,0xfa,0x16,0x7a,0x25,0x2d,0x8f,0x04,0x8e,0x5d,0x35";
BA_ "GenMsgSendType" BO_ 258 "Cyclic";
BA_ "VFrameFormat" BO_ 258 "StandardCAN_FD";
BA_ "GenSigSendType" SG_ 514 DR_Aufbaubeschleunigung_HR "Cyclic";
BA_ "GenSigStartValue" SG_ 514 DR_Aufbaubeschleunigung_HR 1022;
BA_ "GenSigSwitchedByIgnition" SG_ 514 DR_Aufbaubeschleunigung_HR "No";
BA_ "Fehlerwert" SG_ 514 DR_Aufbaubeschleunigung_HR 1023;
BA_ "GenSigSendType" SG_ 514 DR_Aufbaubeschleunigung_VR "Cyclic";
BA_ "GenSigStartValue" SG_ 514 DR_Aufbaubeschleunigung_VR 1022;
BA_ "GenSigSwitchedByIgnition" SG_ 514 DR_Aufbaubeschleunigung_VR "No";
BA_ "Fehlerwert" SG_ 514 DR_Aufbaubeschleunigung_VR 1023;
BA_ "GenSigSendType" SG_ 514 DR_Aufbaubeschleunigung_VL "Cyclic";
BA_ "GenSigStartValue" SG_ 514 DR_Aufbaubeschleunigung_VL 1022;
BA_ "GenSigSwitchedByIgnition" SG_ 514 DR_Aufbaubeschleunigung_VL "No";
BA_ "Fehlerwert" SG_ 514 DR_Aufbaubeschleunigung_VL 1023;
BA_ "GenSigSendType" SG_ 514 DR_Aufbaubeschleunigung_HL "Cyclic";
BA_ "GenSigStartValue" SG_ 514 DR_Aufbaubeschleunigung_HL 1022;
BA_ "GenSigSwitchedByIgnition" SG_ 514 DR_Aufbaubeschleunigung_HL "No";
BA_ "Fehlerwert" SG_ 514 DR_Aufbaubeschleunigung_HL 1023;
BA_ "GenSigSendType" SG_ 514 DR_Funktionsstatus "Cyclic";
BA_ "GenSigSwitchedByIgnition" SG_ 514 DR_Funktionsstatus "No";
BA_ "GenSigSendType" SG_ 514 DR_Drehwinkelsensortausch_VL "Cyclic";
BA_ "GenSigSwitchedByIgnition" SG_ 514 DR_Drehwinkelsensortausch_VL "No";
BA_ "GenSigSendType" SG_ 514 DR_Drehwinkelsensortausch_VR "Cyclic";
BA_ "GenSigSwitchedByIgnition" SG_ 514 DR_Drehwinkelsensortausch_VR "No";
BA_ "GenSigSendType" SG_ 514 DR_Drehwinkelsensortausch_HL "Cyclic";
BA_ "GenSigSwitchedByIgnition" SG_ 514 DR_Drehwinkelsensortausch_HL "No";
BA_ "GenSigSendType" SG_ 514 DR_Drehwinkelsensortausch_HR "Cyclic";
BA_ "GenSigSwitchedByIgnition" SG_ 514 DR_Drehwinkelsensortausch_HR "No";
BA_ "GenSigSendType" SG_ 514 DR_Drehwinkel_VL "Cyclic";
BA_ "GenSigStartValue" SG_ 514 DR_Drehwinkel_VL 4094;
BA_ "GenSigSwitchedByIgnition" SG_ 514 DR_Drehwinkel_VL "No";
BA_ "Fehlerwert" SG_ 514 DR_Drehwinkel_VL 4095;
BA_ "GenSigSendType" SG_ 514 DR_Drehwinkel_VR "Cyclic";
BA_ "GenSigStartValue" SG_ 514 DR_Drehwinkel_VR 4094;
BA_ "GenSigSwitchedByIgnition" SG_ 514 DR_Drehwinkel_VR "No";
BA_ "Fehlerwert" SG_ 514 DR_Drehwinkel_VR 4095;
BA_ "GenSigSendType" SG_ 514 DR_Drehwinkel_HL "Cyclic";
BA_ "GenSigStartValue" SG_ 514 DR_Drehwinkel_HL 4094;
BA_ "GenSigSwitchedByIgnition" SG_ 514 DR_Drehwinkel_HL "No";
BA_ "Fehlerwert" SG_ 514 DR_Drehwinkel_HL 4095;
BA_ "GenSigSendType" SG_ 514 DR_Drehwinkel_HR "Cyclic";
BA_ "GenSigStartValue" SG_ 514 DR_Drehwinkel_HR 4094;
BA_ "GenSigSwitchedByIgnition" SG_ 514 DR_Drehwinkel_HR "No";
BA_ "Fehlerwert" SG_ 514 DR_Drehwinkel_HR 4095;
BA_ "GenSigSendType" SG_ 1485 DCDC_03_CRC "Cyclic";
BA_ "GenSigFuncType" SG_ 1485 DCDC_03_CRC "CRC-8";
BA_ "GenSigSwitchedByIgnition" SG_ 1485 DCDC_03_CRC "No";
BA_ "GenSigSendType" SG_ 1485 DCDC_03_BZ "Cyclic";
BA_ "GenSigFuncType" SG_ 1485 DCDC_03_BZ "MsgCounter";
BA_ "GenSigSwitchedByIgnition" SG_ 1485 DCDC_03_BZ "No";
BA_ "GenSigSendType" SG_ 1485 DC_Temperatur_Alarm "Cyclic";
BA_ "GenSigSwitchedByIgnition" SG_ 1485 DC_Temperatur_Alarm "No";
BA_ "Fehlerwert" SG_ 1485 DC_Temperatur_Alarm 1;
BA_ "GenSigSendType" SG_ 1485 DC_Kl30c_Status "OnChangeWithRepetition";
BA_ "GenSigSwitchedByIgnition" SG_ 1485 DC_Kl30c_Status "No";
BA_ "Fehlerwert" SG_ 1485 DC_Kl30c_Status 3;
BA_ "GenSigSendType" SG_ 1485 DC_Fehlerstatus "OnChange";
BA_ "GenSigStartValue" SG_ 1485 DC_Fehlerstatus 7;
BA_ "GenSigSwitchedByIgnition" SG_ 1485 DC_Fehlerstatus "No";
BA_ "GenSigSendType" SG_ 1485 DC_Peakstrom_verfuegbar "OnChange";
BA_ "GenSigSwitchedByIgnition" SG_ 1485 DC_Peakstrom_verfuegbar "No";
BA_ "GenSigSendType" SG_ 1485 DC_Abregelung_Temperatur "OnChange";
BA_ "GenSigSwitchedByIgnition" SG_ 1485 DC_Abregelung_Temperatur "No";
BA_ "GenSigSendType" SG_ 1485 DC_IstModus_02 "OnChange";
BA_ "GenSigStartValue" SG_ 1485 DC_IstModus_02 7;
BA_ "GenSigSwitchedByIgnition" SG_ 1485 DC_IstModus_02 "No";
BA_ "Fehlerwert" SG_ 1485 DC_IstModus_02 5;
BA_ "GenSigSendType" SG_ 1485 DC_Derating "OnChange";
BA_ "GenSigSwitchedByIgnition" SG_ 1485 DC_Derating "No";
BA_ "GenSigSendType" SG_ 1485 DC_SollVolumenstrom "Cyclic";
BA_ "GenSigStartValue" SG_ 1485 DC_SollVolumenstrom 62;
BA_ "GenSigSwitchedByIgnition" SG_ 1485 DC_SollVolumenstrom "No";
BA_ "Fehlerwert" SG_ 1485 DC_SollVolumenstrom 63;
BA_ "GenSigSendType" SG_ 1485 DC_Status_Spgfreiheit_HV "OnChange";
BA_ "GenSigSwitchedByIgnition" SG_ 1485 DC_Status_Spgfreiheit_HV "No";
BA_ "GenSigSendType" SG_ 1485 DC_Temperatur "Cyclic";
BA_ "GenSigStartValue" SG_ 1485 DC_Temperatur 254;
BA_ "GenSigSwitchedByIgnition" SG_ 1485 DC_Temperatur "No";
BA_ "Fehlerwert" SG_ 1485 DC_Temperatur 255;
BA_ "GenSigSendType" SG_ 247 DCDC_04_CRC "Cyclic";
BA_ "GenSigFuncType" SG_ 247 DCDC_04_CRC "CRC-8";
BA_ "GenSigSwitchedByIgnition" SG_ 247 DCDC_04_CRC "No";
BA_ "GenSigSendType" SG_ 247 DCDC_04_BZ "Cyclic";
BA_ "GenSigFuncType" SG_ 247 DCDC_04_BZ "MsgCounter";
BA_ "GenSigSwitchedByIgnition" SG_ 247 DCDC_04_BZ "No";
BA_ "GenSigSendType" SG_ 247 DC_Vorladung_Status "Cyclic";
BA_ "GenSigSwitchedByIgnition" SG_ 247 DC_Vorladung_Status "No";
BA_ "GenSigSendType" SG_ 247 DC_Fehler_extern "Cyclic";
BA_ "GenSigSwitchedByIgnition" SG_ 247 DC_Fehler_extern "No";
BA_ "Fehlerwert" SG_ 247 DC_Fehler_extern 1;
BA_ "GenSigSendType" SG_ 247 DC_Fehler_intern "Cyclic";
BA_ "GenSigSwitchedByIgnition" SG_ 247 DC_Fehler_intern "No";
BA_ "GenSigSendType" SG_ 247 DC_Status_Spgfreiheit "Cyclic";
BA_ "GenSigSwitchedByIgnition" SG_ 247 DC_Status_Spgfreiheit "No";
BA_ "GenSigSendType" SG_ 247 DC_Status_EoHVL "Cyclic";
BA_ "GenSigSwitchedByIgnition" SG_ 247 DC_Status_EoHVL "No";
BA_ "Fehlerwert" SG_ 247 DC_Status_EoHVL 3;
BA_ "GenSigSendType" SG_ 247 DC_IstModus_02 "Cyclic";
BA_ "GenSigStartValue" SG_ 247 DC_IstModus_02 7;
BA_ "GenSigSwitchedByIgnition" SG_ 247 DC_IstModus_02 "No";
BA_ "Fehlerwert" SG_ 247 DC_IstModus_02 5;
BA_ "GenSigSendType" SG_ 247 DC_IstStrom_HV "Cyclic";
BA_ "GenSigStartValue" SG_ 247 DC_IstStrom_HV 1022;
BA_ "GenSigSwitchedByIgnition" SG_ 247 DC_IstStrom_HV "No";
BA_ "Fehlerwert" SG_ 247 DC_IstStrom_HV 1023;
BA_ "GenSigSendType" SG_ 247 DC_IstLeistung_HV "Cyclic";
BA_ "GenSigStartValue" SG_ 247 DC_IstLeistung_HV 1022;
BA_ "GenSigSwitchedByIgnition" SG_ 247 DC_IstLeistung_HV "No";
BA_ "Fehlerwert" SG_ 247 DC_IstLeistung_HV 1023;
BA_ "GenSigSwitchedByIgnition" SG_ 2617027088 DEV_Airbag_ASM_01_Data "No";
BA_ "GenSigSwitchedByIgnition" SG_ 2617027072 DEV_Airbag_Resp_00_Data "No";
BA_ "GenSigSwitchedByIgnition" SG_ 2617027073 DEV_Airbag_Resp_01_Data "No";
BA_ "GenSigSwitchedByIgnition" SG_ 2617027074 DEV_Airbag_Resp_02_Data "No";
BA_ "GenSigSwitchedByIgnition" SG_ 2617027075 DEV_Airbag_Resp_03_Data "No";
BA_ "GenSigSwitchedByIgnition" SG_ 2617027076 DEV_Airbag_Resp_04_Data "No";
BA_ "GenSigSwitchedByIgnition" SG_ 2617027077 DEV_Airbag_Resp_05_Data "No";
BA_ "GenSigSwitchedByIgnition" SG_ 2617027078 DEV_Airbag_Resp_06_Data "No";
BA_ "GenSigSwitchedByIgnition" SG_ 2617027079 DEV_Airbag_Resp_07_Data "No";
BA_ "GenSigSwitchedByIgnition" SG_ 2617027080 DEV_Airbag_Resp_08_Data "No";
BA_ "GenSigSwitchedByIgnition" SG_ 2617027081 DEV_Airbag_Resp_09_Data "No";
BA_ "GenSigSwitchedByIgnition" SG_ 2617027082 DEV_Airbag_Resp_10_Data "No";
BA_ "GenSigSwitchedByIgnition" SG_ 2617027083 DEV_Airbag_Resp_11_Data "No";
BA_ "GenSigSwitchedByIgnition" SG_ 2617154048 DEV_Waehlhebel_Resp_00_Data "No";
BA_ "GenSigSwitchedByIgnition" SG_ 2617154049 DEV_Waehlhebel_Resp_01_Data "No";
BA_ "GenSigSwitchedByIgnition" SG_ 2617154050 DEV_Waehlhebel_Resp_02_Data "No";
BA_ "GenSigSwitchedByIgnition" SG_ 2617154051 DEV_Waehlhebel_Resp_03_Data "No";
BA_ "GenSigSwitchedByIgnition" SG_ 2617154052 DEV_Waehlhebel_Resp_04_Data "No";
BA_ "GenSigSwitchedByIgnition" SG_ 2617154053 DEV_Waehlhebel_Resp_05_Data "No";
BA_ "GenSigSendType" SG_ 2549876269 Diag_Waehlhebel_Req_Data "OnChange";
BA_ "GenSigSwitchedByIgnition" SG_ 2549876269 Diag_Waehlhebel_Req_Data "No";
BA_ "GenSigSendType" SG_ 2550007341 Diag_Waehlhebel_Resp_Data "OnChange";
BA_ "GenSigSwitchedByIgnition" SG_ 2550007341 Diag_Waehlhebel_Resp_Data "No";
BA_ "GenSigSendType" SG_ 1714 DGN_Verlernzaehler "Cyclic";
BA_ "GenSigSwitchedByIgnition" SG_ 1714 DGN_Verlernzaehler "No";
BA_ "GenSigSendType" SG_ 1714 KBI_Kilometerstand "Cyclic";
BA_ "GenSigStartValue" SG_ 1714 KBI_Kilometerstand 1048574;
BA_ "GenSigSwitchedByIgnition" SG_ 1714 KBI_Kilometerstand "No";
BA_ "Fehlerwert" SG_ 1714 KBI_Kilometerstand 1048575;
BA_ "GenSigSendType" SG_ 1714 UH_Jahr "Cyclic";
BA_ "GenSigSwitchedByIgnition" SG_ 1714 UH_Jahr "No";
BA_ "GenSigSendType" SG_ 1714 UH_Monat "Cyclic";
BA_ "GenSigSwitchedByIgnition" SG_ 1714 UH_Monat "No";
BA_ "Fehlerwert" SG_ 1714 UH_Monat 15;
BA_ "GenSigSendType" SG_ 1714 UH_Tag "Cyclic";
BA_ "GenSigSwitchedByIgnition" SG_ 1714 UH_Tag "No";
BA_ "GenSigSendType" SG_ 1714 UH_Stunde "Cyclic";
BA_ "GenSigSwitchedByIgnition" SG_ 1714 UH_Stunde "No";
BA_ "GenSigSendType" SG_ 1714 UH_Minute "Cyclic";
BA_ "GenSigSwitchedByIgnition" SG_ 1714 UH_Minute "No";
BA_ "GenSigSendType" SG_ 1714 UH_Sekunde "Cyclic";
BA_ "GenSigSwitchedByIgnition" SG_ 1714 UH_Sekunde "No";
BA_ "GenSigSendType" SG_ 1714 Vehicle_Driving_Cycle "Cyclic";
BA_ "GenSigSwitchedByIgnition" SG_ 1714 Vehicle_Driving_Cycle "No";
BA_ "GenSigSendType" SG_ 1714 Kombi_02_alt "Cyclic";
BA_ "GenSigStartValue" SG_ 1714 Kombi_02_alt 1;
BA_ "GenSigFuncType" SG_ 1714 Kombi_02_alt "DatedBit";
BA_ "GenSigSwitchedByIgnition" SG_ 1714 Kombi_02_alt "No";
BA_ "GenSigSendType" SG_ 1714 Uhrzeit_01_alt "Cyclic";
BA_ "GenSigStartValue" SG_ 1714 Uhrzeit_01_alt 1;
BA_ "GenSigFuncType" SG_ 1714 Uhrzeit_01_alt "DatedBit";
BA_ "GenSigSwitchedByIgnition" SG_ 1714 Uhrzeit_01_alt "No";
BA_ "GenSigSendType" SG_ 851 DiETas_01_CRC "Cyclic";
BA_ "GenSigFuncType" SG_ 851 DiETas_01_CRC "CRC-8";
BA_ "GenSigSwitchedByIgnition" SG_ 851 DiETas_01_CRC "No";
BA_ "GenSigSendType" SG_ 851 DiETas_01_BZ "Cyclic";
BA_ "GenSigFuncType" SG_ 851 DiETas_01_BZ "MsgCounter";
BA_ "GenSigSwitchedByIgnition" SG_ 851 DiETas_01_BZ "No";
BA_ "GenSigSendType" SG_ 851 DiETa_Reserve_Byte2_4 "Cyclic";
BA_ "GenSigSwitchedByIgnition" SG_ 851 DiETa_Reserve_Byte2_4 "No";
BA_ "GenSigSendType" SG_ 851 DiETa_Status "Cyclic";
BA_ "GenSigStartValue" SG_ 851 DiETa_Status 2;
BA_ "GenSigSwitchedByIgnition" SG_ 851 DiETa_Status "No";
BA_ "GenSigSendType" SG_ 851 DiETa_ResponseError "Cyclic";
BA_ "GenSigSwitchedByIgnition" SG_ 851 DiETa_ResponseError "No";
BA_ "Fehlerwert" SG_ 851 DiETa_ResponseError 1;
BA_ "GenSigSendType" SG_ 851 DiETa_Car "Cyclic";
BA_ "GenSigSwitchedByIgnition" SG_ 851 DiETa_Car "No";
BA_ "Fehlerwert" SG_ 851 DiETa_Car 3;
BA_ "GenSigSendType" SG_ 851 DiETa_Klima "Cyclic";
BA_ "GenSigSwitchedByIgnition" SG_ 851 DiETa_Klima "No";
BA_ "Fehlerwert" SG_ 851 DiETa_Klima 3;
BA_ "GenSigSendType" SG_ 851 DiETa_Mode "Cyclic";
BA_ "GenSigSwitchedByIgnition" SG_ 851 DiETa_Mode "No";
BA_ "Fehlerwert" SG_ 851 DiETa_Mode 3;
BA_ "GenSigSendType" SG_ 851 DiETa_Parken "Cyclic";
BA_ "GenSigSwitchedByIgnition" SG_ 851 DiETa_Parken "No";
BA_ "Fehlerwert" SG_ 851 DiETa_Parken 3;
BA_ "GenSigSendType" SG_ 851 DiETa_FSH_Taste "Cyclic";
BA_ "GenSigSwitchedByIgnition" SG_ 851 DiETa_FSH_Taste "No";
BA_ "Fehlerwert" SG_ 851 DiETa_FSH_Taste 3;
BA_ "GenSigSendType" SG_ 851 DiETa_HSH_Taste "Cyclic";
BA_ "GenSigSwitchedByIgnition" SG_ 851 DiETa_HSH_Taste "No";
BA_ "Fehlerwert" SG_ 851 DiETa_HSH_Taste 3;
BA_ "GenSigSendType" SG_ 851 DiETa_Warnblink_Taste "Cyclic";
BA_ "GenSigSwitchedByIgnition" SG_ 851 DiETa_Warnblink_Taste "No";
BA_ "Fehlerwert" SG_ 851 DiETa_Warnblink_Taste 3;
BA_ "GenSigSendType" SG_ 851 DiETa_FAS_Stufe "Cyclic";
BA_ "GenSigSwitchedByIgnition" SG_ 851 DiETa_FAS_Stufe "No";
BA_ "Fehlerwert" SG_ 851 DiETa_FAS_Stufe 3;
BA_ "GenSigSendType" SG_ 851 DiETa_PAO_ON_Status "Cyclic";
BA_ "GenSigSwitchedByIgnition" SG_ 851 DiETa_PAO_ON_Status "No";
BA_ "GenSigSendType" SG_ 851 DiETa_PAO_OFF_Status "Cyclic";
BA_ "GenSigSwitchedByIgnition" SG_ 851 DiETa_PAO_OFF_Status "No";
BA_ "GenSigSendType" SG_ 851 DiETa_Defrost_Taste "Cyclic";
BA_ "GenSigSwitchedByIgnition" SG_ 851 DiETa_Defrost_Taste "No";
BA_ "Fehlerwert" SG_ 851 DiETa_Defrost_Taste 3;
BA_ "GenSigSendType" SG_ 851 DiETa_Reserve_Byte5_6 "Cyclic";
BA_ "GenSigSwitchedByIgnition" SG_ 851 DiETa_Reserve_Byte5_6 "No";
BA_ "GenSigSendType" SG_ 851 DiETa_Lock_Unlock_Taste "Cyclic";
BA_ "GenSigSwitchedByIgnition" SG_ 851 DiETa_Lock_Unlock_Taste "No";
BA_ "Fehlerwert" SG_ 851 DiETa_Lock_Unlock_Taste 7;
BA_ "GenSigSendType" SG_ 851 DiETa_Mode_roh "Cyclic";
BA_ "GenSigSwitchedByIgnition" SG_ 851 DiETa_Mode_roh "No";
BA_ "GenSigSendType" SG_ 851 DiETa_Reserve_Byte6_3 "Cyclic";
BA_ "GenSigSwitchedByIgnition" SG_ 851 DiETa_Reserve_Byte6_3 "No";
BA_ "GenSigSendType" SG_ 851 DiETa_Reserve_Byte7 "Cyclic";
BA_ "GenSigSwitchedByIgnition" SG_ 851 DiETa_Reserve_Byte7 "No";
BA_ "GenSigSendType" SG_ 851 DiETa_Reserve_Byte8 "Cyclic";
BA_ "GenSigSwitchedByIgnition" SG_ 851 DiETa_Reserve_Byte8 "No";
BA_ "GenSigSendType" SG_ 1520 DI_KL_58xd "OnChange";
BA_ "GenSigStartValue" SG_ 1520 DI_KL_58xd 254;
BA_ "GenSigSwitchedByIgnition" SG_ 1520 DI_KL_58xd "No";
BA_ "Fehlerwert" SG_ 1520 DI_KL_58xd 255;
BA_ "GenSigSendType" SG_ 1520 DI_KL_58xs "OnChange";
BA_ "GenSigStartValue" SG_ 1520 DI_KL_58xs 126;
BA_ "GenSigSwitchedByIgnition" SG_ 1520 DI_KL_58xs "No";
BA_ "Fehlerwert" SG_ 1520 DI_KL_58xs 127;
BA_ "GenSigSendType" SG_ 1520 DI_Display_Nachtdesign "OnChange";
BA_ "GenSigSwitchedByIgnition" SG_ 1520 DI_Display_Nachtdesign "No";
BA_ "GenSigSendType" SG_ 1520 DI_KL_58xt "OnChange";
BA_ "GenSigStartValue" SG_ 1520 DI_KL_58xt 126;
BA_ "GenSigSwitchedByIgnition" SG_ 1520 DI_KL_58xt "No";
BA_ "Fehlerwert" SG_ 1520 DI_KL_58xt 127;
BA_ "GenSigSendType" SG_ 1520 DI_Fotosensor "OnChange";
BA_ "GenSigSwitchedByIgnition" SG_ 1520 DI_Fotosensor "No";
BA_ "GenSigSendType" SG_ 1520 BCM1_Stellgroesse_Kl_58s "OnChange";
BA_ "GenSigStartValue" SG_ 1520 BCM1_Stellgroesse_Kl_58s 126;
BA_ "GenSigSwitchedByIgnition" SG_ 1520 BCM1_Stellgroesse_Kl_58s "No";
BA_ "Fehlerwert" SG_ 1520 BCM1_Stellgroesse_Kl_58s 127;
BA_ "GenSigSendType" SG_ 420 EA_01_CRC "Cyclic";
BA_ "GenSigFuncType" SG_ 420 EA_01_CRC "CRC-8";
BA_ "GenSigSendType" SG_ 420 EA_01_BZ "Cyclic";
BA_ "GenSigFuncType" SG_ 420 EA_01_BZ "MsgCounter";
BA_ "GenSigSendType" SG_ 420 EA_Parken_beibehalten_HMS "Cyclic";
BA_ "GenSigStartValue" SG_ 420 EA_Parken_beibehalten_HMS 2;
BA_ "Fehlerwert" SG_ 420 EA_Parken_beibehalten_HMS 3;
BA_ "GenSigSendType" SG_ 420 EA_Ruckstaerke "Cyclic";
BA_ "GenSigSendType" SG_ 420 EA_Warnruckprofil "Cyclic";
BA_ "GenSigSendType" SG_ 420 EA_aktiv_laengs "Cyclic";
BA_ "GenSigSendType" SG_ 420 EA_Funktionsstatus "Cyclic";
BA_ "GenSigSendType" SG_ 420 EA_Gurtstraffer_Anf "OnChange";
BA_ "GenSigSendType" SG_ 420 EA_Anf_Prefill "Cyclic";
BA_ "GenSigSendType" SG_ 420 EA_Anforderung_HMS "Cyclic";
BA_ "GenSigSendType" SG_ 420 EA_Ruckfreigabe "Cyclic";
BA_ "GenSigSendType" SG_ 420 EA_01_Sendestatus "IfActiveWithRepetition";
BA_ "GenSigSwitchedByIgnition" SG_ 420 EA_01_Sendestatus "No";
BA_ "GenSigSendType" SG_ 420 EA_Sollbeschleunigung "Cyclic";
BA_ "GenSigStartValue" SG_ 420 EA_Sollbeschleunigung 2046;
BA_ "Fehlerwert" SG_ 420 EA_Sollbeschleunigung 2047;
BA_ "GenSigSendType" SG_ 374 EBKV_03_CRC "Cyclic";
BA_ "GenSigFuncType" SG_ 374 EBKV_03_CRC "CRC-8";
BA_ "GenSigSwitchedByIgnition" SG_ 374 EBKV_03_CRC "No";
BA_ "GenSigSendType" SG_ 374 EBKV_03_BZ "Cyclic";
BA_ "GenSigFuncType" SG_ 374 EBKV_03_BZ "MsgCounter";
BA_ "GenSigSwitchedByIgnition" SG_ 374 EBKV_03_BZ "No";
BA_ "GenSigSendType" SG_ 374 EBKV_Activate_Fallback_ESP "Cyclic";
BA_ "GenSigSwitchedByIgnition" SG_ 374 EBKV_Activate_Fallback_ESP "No";
BA_ "GenSigSendType" SG_ 374 EBKV_Restdruckabsenkung "Cyclic";
BA_ "GenSigSwitchedByIgnition" SG_ 374 EBKV_Restdruckabsenkung "No";
BA_ "GenSigSendType" SG_ 374 EBKV_Status_02 "Cyclic";
BA_ "GenSigSwitchedByIgnition" SG_ 374 EBKV_Status_02 "No";
BA_ "GenSigSendType" SG_ 374 EBKV_Diagnose "Cyclic";
BA_ "GenSigSwitchedByIgnition" SG_ 374 EBKV_Diagnose "No";
BA_ "GenSigSendType" SG_ 374 EBKV_Fahrer_bremst "Cyclic";
BA_ "GenSigSwitchedByIgnition" SG_ 374 EBKV_Fahrer_bremst "No";
BA_ "GenSigSendType" SG_ 374 EBKV_QBit_Fahrer_bremst "Cyclic";
BA_ "GenSigStartValue" SG_ 374 EBKV_QBit_Fahrer_bremst 1;
BA_ "GenSigSwitchedByIgnition" SG_ 374 EBKV_QBit_Fahrer_bremst "No";
BA_ "GenSigSendType" SG_ 374 EBKV_Fahrer_bremst_deutlich "Cyclic";
BA_ "GenSigSwitchedByIgnition" SG_ 374 EBKV_Fahrer_bremst_deutlich "No";
BA_ "GenSigSendType" SG_ 374 EBKV_OBD_Status "Cyclic";
BA_ "GenSigSwitchedByIgnition" SG_ 374 EBKV_OBD_Status "No";
BA_ "GenSigSendType" SG_ 374 EBKV_VMM_Sek_Notstopp_Status "Cyclic";
BA_ "GenSigSwitchedByIgnition" SG_ 374 EBKV_VMM_Sek_Notstopp_Status "No";
BA_ "GenSigSendType" SG_ 374 EBKV_Anforderung_HMS "Cyclic";
BA_ "GenSigSwitchedByIgnition" SG_ 374 EBKV_Anforderung_HMS "No";
BA_ "GenSigSendType" SG_ 374 SBS_Anforderung_GE "Cyclic";
BA_ "GenSigSwitchedByIgnition" SG_ 374 SBS_Anforderung_GE "No";
BA_ "GenSigSendType" SG_ 374 EPB_Status_ext "Cyclic";
BA_ "GenSigStartValue" SG_ 374 EPB_Status_ext 6;
BA_ "GenSigSwitchedByIgnition" SG_ 374 EPB_Status_ext "No";
BA_ "GenSigSendType" SG_ 374 EBKV_Bremspedalweg "Cyclic";
BA_ "GenSigSwitchedByIgnition" SG_ 374 EBKV_Bremspedalweg "No";
BA_ "Fehlerwert" SG_ 374 EBKV_Bremspedalweg 255;
BA_ "GenSigSendType" SG_ 374 EBKV_Kraftblending_Reserve "Cyclic";
BA_ "GenSigStartValue" SG_ 374 EBKV_Kraftblending_Reserve 254;
BA_ "GenSigSwitchedByIgnition" SG_ 374 EBKV_Kraftblending_Reserve "No";
BA_ "Fehlerwert" SG_ 374 EBKV_Kraftblending_Reserve 255;
BA_ "GenSigSendType" SG_ 374 EBKV_Aussteuerdruck "Cyclic";
BA_ "GenSigStartValue" SG_ 374 EBKV_Aussteuerdruck 254;
BA_ "GenSigSwitchedByIgnition" SG_ 374 EBKV_Aussteuerdruck "No";
BA_ "Fehlerwert" SG_ 374 EBKV_Aussteuerdruck 255;
BA_ "GenSigSendType" SG_ 1603 KBI_Einheit_Datum "OnChange";
BA_ "GenSigSwitchedByIgnition" SG_ 1603 KBI_Einheit_Datum "No";
BA_ "GenSigSendType" SG_ 1603 KBI_Einheit_Druck "OnChange";
BA_ "GenSigSwitchedByIgnition" SG_ 1603 KBI_Einheit_Druck "No";
BA_ "GenSigSendType" SG_ 1603 KBI_Einheit_Streckenanz "OnChange";
BA_ "GenSigSwitchedByIgnition" SG_ 1603 KBI_Einheit_Streckenanz "No";
BA_ "GenSigSendType" SG_ 1603 KBI_MFA_v_Einheit_02 "OnChange";
BA_ "GenSigSwitchedByIgnition" SG_ 1603 KBI_MFA_v_Einheit_02 "No";
BA_ "GenSigSendType" SG_ 1603 KBI_Einheit_Temp "OnChange";
BA_ "GenSigSwitchedByIgnition" SG_ 1603 KBI_Einheit_Temp "No";
BA_ "GenSigSendType" SG_ 1603 KBI_Einheit_Uhrzeit "OnChange";
BA_ "GenSigSwitchedByIgnition" SG_ 1603 KBI_Einheit_Uhrzeit "No";
BA_ "GenSigSendType" SG_ 1603 KBI_Einheit_Verbrauch "OnChange";
BA_ "GenSigSwitchedByIgnition" SG_ 1603 KBI_Einheit_Verbrauch "No";
BA_ "GenSigSendType" SG_ 1603 KBI_Einheit_Volumen "OnChange";
BA_ "GenSigSwitchedByIgnition" SG_ 1603 KBI_Einheit_Volumen "No";
BA_ "GenSigSendType" SG_ 1603 KBI_Einheit_Verbrauch_elektr "OnChange";
BA_ "GenSigSwitchedByIgnition" SG_ 1603 KBI_Einheit_Verbrauch_elektr "No";
BA_ "GenSigSendType" SG_ 1603 KBI_Einheit_Tacho "OnChange";
BA_ "GenSigSwitchedByIgnition" SG_ 1603 KBI_Einheit_Tacho "No";
BA_ "GenSigSendType" SG_ 1603 KBI_Einheit_Sprache "OnChange";
BA_ "GenSigSwitchedByIgnition" SG_ 1603 KBI_Einheit_Sprache "No";
BA_ "GenSigSendType" SG_ 1603 KBI_Einheit_Verbrauch_Gas "OnChange";
BA_ "GenSigSwitchedByIgnition" SG_ 1603 KBI_Einheit_Verbrauch_Gas "No";
BA_ "GenSigSendType" SG_ 1603 KBI_Einheit_Masse "OnChange";
BA_ "GenSigSwitchedByIgnition" SG_ 1603 KBI_Einheit_Masse "No";
BA_ "GenSigSendType" SG_ 192 EM1_01_CRC "Cyclic";
BA_ "GenSigFuncType" SG_ 192 EM1_01_CRC "CRC-8";
BA_ "GenSigSwitchedByIgnition" SG_ 192 EM1_01_CRC "No";
BA_ "GenSigSendType" SG_ 192 EM1_01_BZ "Cyclic";
BA_ "GenSigFuncType" SG_ 192 EM1_01_BZ "MsgCounter";
BA_ "GenSigSwitchedByIgnition" SG_ 192 EM1_01_BZ "No";
BA_ "GenSigSendType" SG_ 192 EM1_Istmodus "Cyclic";
BA_ "GenSigStartValue" SG_ 192 EM1_Istmodus 15;
BA_ "GenSigSwitchedByIgnition" SG_ 192 EM1_Istmodus "No";
BA_ "GenSigSendType" SG_ 192 EM1_IstMoment "Cyclic";
BA_ "GenSigStartValue" SG_ 192 EM1_IstMoment 4094;
BA_ "GenSigSwitchedByIgnition" SG_ 192 EM1_IstMoment "No";
BA_ "Fehlerwert" SG_ 192 EM1_IstMoment 4095;
BA_ "GenSigSendType" SG_ 192 EM1_Moment_AR_Eingriff "Cyclic";
BA_ "GenSigStartValue" SG_ 192 EM1_Moment_AR_Eingriff 4094;
BA_ "GenSigSwitchedByIgnition" SG_ 192 EM1_Moment_AR_Eingriff "No";
BA_ "Fehlerwert" SG_ 192 EM1_Moment_AR_Eingriff 4095;
BA_ "GenSigSendType" SG_ 192 EM1_IstDrehzahl "Cyclic";
BA_ "GenSigStartValue" SG_ 192 EM1_IstDrehzahl 32766;
BA_ "GenSigSwitchedByIgnition" SG_ 192 EM1_IstDrehzahl "No";
BA_ "Fehlerwert" SG_ 192 EM1_IstDrehzahl 32767;
BA_ "GenSigSendType" SG_ 192 EM1_AR_aktiv "Cyclic";
BA_ "GenSigSwitchedByIgnition" SG_ 192 EM1_AR_aktiv "No";
BA_ "GenSigSendType" SG_ 192 EM1_IstSpannung "Cyclic";
BA_ "GenSigStartValue" SG_ 192 EM1_IstSpannung 4094;
BA_ "GenSigSwitchedByIgnition" SG_ 192 EM1_IstSpannung "No";
BA_ "Fehlerwert" SG_ 192 EM1_IstSpannung 4095;
BA_ "GenSigSendType" SG_ 192 EM1_Strom_HV "Cyclic";
BA_ "GenSigStartValue" SG_ 192 EM1_Strom_HV 4094;
BA_ "GenSigSwitchedByIgnition" SG_ 192 EM1_Strom_HV "No";
BA_ "Fehlerwert" SG_ 192 EM1_Strom_HV 4095;
BA_ "GenSigSendType" SG_ 192 EM1_Max_Moment "Cyclic";
BA_ "GenSigStartValue" SG_ 192 EM1_Max_Moment 2046;
BA_ "GenSigSwitchedByIgnition" SG_ 192 EM1_Max_Moment "No";
BA_ "Fehlerwert" SG_ 192 EM1_Max_Moment 2047;
BA_ "GenSigSendType" SG_ 192 EM1_ErwGrenzen_aktiv "Cyclic";
BA_ "GenSigSwitchedByIgnition" SG_ 192 EM1_ErwGrenzen_aktiv "No";
BA_ "GenSigSendType" SG_ 192 EM1_Min_Moment "Cyclic";
BA_ "GenSigStartValue" SG_ 192 EM1_Min_Moment 2046;
BA_ "GenSigSwitchedByIgnition" SG_ 192 EM1_Min_Moment "No";
BA_ "Fehlerwert" SG_ 192 EM1_Min_Moment 2047;
BA_ "GenSigSendType" SG_ 192 EM1_Fehler_ElAntriebAbschaltung "Cyclic";
BA_ "GenSigSwitchedByIgnition" SG_ 192 EM1_Fehler_ElAntriebAbschaltung "No";
BA_ "GenSigSendType" SG_ 192 EM1_Max_Moment_Lim "Cyclic";
BA_ "GenSigStartValue" SG_ 192 EM1_Max_Moment_Lim 2046;
BA_ "GenSigSwitchedByIgnition" SG_ 192 EM1_Max_Moment_Lim "No";
BA_ "Fehlerwert" SG_ 192 EM1_Max_Moment_Lim 2047;
BA_ "GenSigSendType" SG_ 192 EM1_Fehler_Notabschaltung "Cyclic";
BA_ "GenSigSwitchedByIgnition" SG_ 192 EM1_Fehler_Notabschaltung "No";
BA_ "Fehlerwert" SG_ 192 EM1_Fehler_Notabschaltung 1;
BA_ "GenSigSendType" SG_ 192 EM1_Min_Moment_Lim "Cyclic";
BA_ "GenSigStartValue" SG_ 192 EM1_Min_Moment_Lim 2046;
BA_ "GenSigSwitchedByIgnition" SG_ 192 EM1_Min_Moment_Lim "No";
BA_ "Fehlerwert" SG_ 192 EM1_Min_Moment_Lim 2047;
BA_ "GenSigSendType" SG_ 192 EM1_Status_DrzEingriff "Cyclic";
BA_ "GenSigSwitchedByIgnition" SG_ 192 EM1_Status_DrzEingriff "No";
BA_ "Fehlerwert" SG_ 192 EM1_Status_DrzEingriff 3;
BA_ "GenSigSendType" SG_ 192 EM1_Mom_DrzEingriff "Cyclic";
BA_ "GenSigStartValue" SG_ 192 EM1_Mom_DrzEingriff 2046;
BA_ "GenSigSwitchedByIgnition" SG_ 192 EM1_Mom_DrzEingriff "No";
BA_ "Fehlerwert" SG_ 192 EM1_Mom_DrzEingriff 2047;
BA_ "GenSigSendType" SG_ 2463978673 EM1_Status_Spgfreiheit "Cyclic";
BA_ "GenSigSwitchedByIgnition" SG_ 2463978673 EM1_Status_Spgfreiheit "No";
BA_ "GenSigSendType" SG_ 2463978673 EM1_Status_EoHVL "Cyclic";
BA_ "GenSigSwitchedByIgnition" SG_ 2463978673 EM1_Status_EoHVL "No";
BA_ "Fehlerwert" SG_ 2463978673 EM1_Status_EoHVL 3;
BA_ "GenSigSendType" SG_ 2463978673 EM1_Max_LeistungMech_Sockel "Cyclic";
BA_ "GenSigStartValue" SG_ 2463978673 EM1_Max_LeistungMech_Sockel 8190;
BA_ "GenSigSwitchedByIgnition" SG_ 2463978673 EM1_Max_LeistungMech_Sockel "No";
BA_ "Fehlerwert" SG_ 2463978673 EM1_Max_LeistungMech_Sockel 8191;
BA_ "GenSigSendType" SG_ 2463978673 EM1_Max_Moment_Sockel "Cyclic";
BA_ "GenSigStartValue" SG_ 2463978673 EM1_Max_Moment_Sockel 2046;
BA_ "GenSigSwitchedByIgnition" SG_ 2463978673 EM1_Max_Moment_Sockel "No";
BA_ "Fehlerwert" SG_ 2463978673 EM1_Max_Moment_Sockel 2047;
BA_ "GenSigSendType" SG_ 2463978673 EM1_Min_LeistungMech_Sockel "Cyclic";
BA_ "GenSigStartValue" SG_ 2463978673 EM1_Min_LeistungMech_Sockel 8190;
BA_ "GenSigSwitchedByIgnition" SG_ 2463978673 EM1_Min_LeistungMech_Sockel "No";
BA_ "Fehlerwert" SG_ 2463978673 EM1_Min_LeistungMech_Sockel 8191;
BA_ "GenSigSendType" SG_ 2463978673 EM1_Min_Moment_Sockel "Cyclic";
BA_ "GenSigStartValue" SG_ 2463978673 EM1_Min_Moment_Sockel 2046;
BA_ "GenSigSwitchedByIgnition" SG_ 2463978673 EM1_Min_Moment_Sockel "No";
BA_ "Fehlerwert" SG_ 2463978673 EM1_Min_Moment_Sockel 2047;
BA_ "GenSigSendType" SG_ 2463978673 EM1_PerfInd_MaxLeistung "Cyclic";
BA_ "GenSigStartValue" SG_ 2463978673 EM1_PerfInd_MaxLeistung 1022;
BA_ "GenSigSwitchedByIgnition" SG_ 2463978673 EM1_PerfInd_MaxLeistung "No";
BA_ "GenSigSendType" SG_ 2463978673 EM1_PerfInd_MaxMoment "Cyclic";
BA_ "GenSigStartValue" SG_ 2463978673 EM1_PerfInd_MaxMoment 1022;
BA_ "GenSigSwitchedByIgnition" SG_ 2463978673 EM1_PerfInd_MaxMoment "No";
BA_ "GenSigSendType" SG_ 2463978673 EM1_AnlernenElMotor_Anf "Cyclic";
BA_ "GenSigSwitchedByIgnition" SG_ 2463978673 EM1_AnlernenElMotor_Anf "No";
BA_ "GenSigSendType" SG_ 2463978673 EM1_OBD_Lampe_Anf "Cyclic";
BA_ "GenSigSwitchedByIgnition" SG_ 2463978673 EM1_OBD_Lampe_Anf "No";
BA_ "GenSigSendType" SG_ 2463978673 EM1_Generator_Moment "Cyclic";
BA_ "GenSigStartValue" SG_ 2463978673 EM1_Generator_Moment 1022;
BA_ "GenSigSwitchedByIgnition" SG_ 2463978673 EM1_Generator_Moment "No";
BA_ "Fehlerwert" SG_ 2463978673 EM1_Generator_Moment 1023;
BA_ "GenSigSendType" SG_ 2463978673 EM1_PerfInd_Temperatur "Cyclic";
BA_ "GenSigStartValue" SG_ 2463978673 EM1_PerfInd_Temperatur 254;
BA_ "GenSigSwitchedByIgnition" SG_ 2463978673 EM1_PerfInd_Temperatur "No";
BA_ "GenSigSendType" SG_ 2463978673 EM1_MaxZul_Drehzahl "Cyclic";
BA_ "GenSigStartValue" SG_ 2463978673 EM1_MaxZul_Drehzahl 254;
BA_ "GenSigSwitchedByIgnition" SG_ 2463978673 EM1_MaxZul_Drehzahl "No";
BA_ "Fehlerwert" SG_ 2463978673 EM1_MaxZul_Drehzahl 255;
BA_ "GenSigSendType" SG_ 2463978673 EM1_Min_Moment_Gesamt "Cyclic";
BA_ "GenSigStartValue" SG_ 2463978673 EM1_Min_Moment_Gesamt 2046;
BA_ "GenSigSwitchedByIgnition" SG_ 2463978673 EM1_Min_Moment_Gesamt "No";
BA_ "Fehlerwert" SG_ 2463978673 EM1_Min_Moment_Gesamt 2047;
BA_ "GenSigSendType" SG_ 2463978673 EM1_Fehlerlampe_Anf "Cyclic";
BA_ "GenSigSwitchedByIgnition" SG_ 2463978673 EM1_Fehlerlampe_Anf "No";
BA_ "GenSigSendType" SG_ 2463978673 EM1_Max_Moment_Gesamt "Cyclic";
BA_ "GenSigStartValue" SG_ 2463978673 EM1_Max_Moment_Gesamt 2046;
BA_ "GenSigSwitchedByIgnition" SG_ 2463978673 EM1_Max_Moment_Gesamt "No";
BA_ "Fehlerwert" SG_ 2463978673 EM1_Max_Moment_Gesamt 2047;
BA_ "GenSigSendType" SG_ 2463978673 EM1_Warnlampe_Anf "Cyclic";
BA_ "GenSigSwitchedByIgnition" SG_ 2463978673 EM1_Warnlampe_Anf "No";
BA_ "GenSigSendType" SG_ 2463978673 EM1_Rekuperation "Cyclic";
BA_ "GenSigSwitchedByIgnition" SG_ 2463978673 EM1_Rekuperation "No";
BA_ "GenSigSendType" SG_ 2463978673 EM1_Rekuperation_Ueberlauf "Cyclic";
BA_ "GenSigSwitchedByIgnition" SG_ 2463978673 EM1_Rekuperation_Ueberlauf "No";
BA_ "GenSigSendType" SG_ 2463978673 EM1_Verbrauch "Cyclic";
BA_ "GenSigSwitchedByIgnition" SG_ 2463978673 EM1_Verbrauch "No";
BA_ "GenSigSendType" SG_ 2463978673 EM1_Verbrauch_Ueberlauf "Cyclic";
BA_ "GenSigSwitchedByIgnition" SG_ 2463978673 EM1_Verbrauch_Ueberlauf "No";
BA_ "GenSigSendType" SG_ 2463978673 EM1_Fehler_AE "Cyclic";
BA_ "GenSigSwitchedByIgnition" SG_ 2463978673 EM1_Fehler_AE "No";
BA_ "GenSigSendType" SG_ 2463978673 EM1_Fehler_Leistungsred "Cyclic";
BA_ "GenSigSwitchedByIgnition" SG_ 2463978673 EM1_Fehler_Leistungsred "No";
BA_ "GenSigSendType" SG_ 2463978673 EM1_Fehler_ElAntriebFreilauf "Cyclic";
BA_ "GenSigSwitchedByIgnition" SG_ 2463978673 EM1_Fehler_ElAntriebFreilauf "No";
BA_ "GenSigSendType" SG_ 2463978673 EM1_PWR_SollVolumenstrom "Cyclic";
BA_ "GenSigStartValue" SG_ 2463978673 EM1_PWR_SollVolumenstrom 62;
BA_ "GenSigSwitchedByIgnition" SG_ 2463978673 EM1_PWR_SollVolumenstrom "No";
BA_ "Fehlerwert" SG_ 2463978673 EM1_PWR_SollVolumenstrom 63;
BA_ "GenSigSendType" SG_ 2589283657 EM1_SollVorlauftemperatur "Cyclic";
BA_ "GenSigStartValue" SG_ 2589283657 EM1_SollVorlauftemperatur 254;
BA_ "GenSigSwitchedByIgnition" SG_ 2589283657 EM1_SollVorlauftemperatur "No";
BA_ "Fehlerwert" SG_ 2589283657 EM1_SollVorlauftemperatur 255;
BA_ "GenSigSendType" SG_ 2589283657 EM1_Temperatur_EM "Cyclic";
BA_ "GenSigStartValue" SG_ 2589283657 EM1_Temperatur_EM 510;
BA_ "GenSigSwitchedByIgnition" SG_ 2589283657 EM1_Temperatur_EM "No";
BA_ "Fehlerwert" SG_ 2589283657 EM1_Temperatur_EM 511;
BA_ "GenSigSendType" SG_ 2589283657 EM1_EM_SollVolumenstrom "Cyclic";
BA_ "GenSigStartValue" SG_ 2589283657 EM1_EM_SollVolumenstrom 62;
BA_ "GenSigSwitchedByIgnition" SG_ 2589283657 EM1_EM_SollVolumenstrom "No";
BA_ "Fehlerwert" SG_ 2589283657 EM1_EM_SollVolumenstrom 63;
BA_ "GenSigSendType" SG_ 2589283657 EM1_Max_MechLeistung_nom "Cyclic";
BA_ "GenSigStartValue" SG_ 2589283657 EM1_Max_MechLeistung_nom 4094;
BA_ "GenSigSwitchedByIgnition" SG_ 2589283657 EM1_Max_MechLeistung_nom "No";
BA_ "Fehlerwert" SG_ 2589283657 EM1_Max_MechLeistung_nom 4095;
BA_ "GenSigSendType" SG_ 2589283657 EM1_Max_Moment_nom "Cyclic";
BA_ "GenSigStartValue" SG_ 2589283657 EM1_Max_Moment_nom 1022;
BA_ "GenSigSwitchedByIgnition" SG_ 2589283657 EM1_Max_Moment_nom "No";
BA_ "Fehlerwert" SG_ 2589283657 EM1_Max_Moment_nom 1023;
BA_ "GenSigSendType" SG_ 2589283657 EM1_Temperatur_PWR "Cyclic";
BA_ "GenSigStartValue" SG_ 2589283657 EM1_Temperatur_PWR 254;
BA_ "GenSigSwitchedByIgnition" SG_ 2589283657 EM1_Temperatur_PWR "No";
BA_ "Fehlerwert" SG_ 2589283657 EM1_Temperatur_PWR 255;
BA_ "GenSigSendType" SG_ 184 EM1_Freigabe_Info_WFS "OnChange";
BA_ "GenSigSwitchedByIgnition" SG_ 184 EM1_Freigabe_Info_WFS "No";
BA_ "GenSigSendType" SG_ 184 EM1_Sperr_Info_WFS "OnChange";
BA_ "GenSigSwitchedByIgnition" SG_ 184 EM1_Sperr_Info_WFS "No";
BA_ "GenSigSendType" SG_ 184 EM1_AR_aktiv "Cyclic";
BA_ "GenSigSwitchedByIgnition" SG_ 184 EM1_AR_aktiv "No";
BA_ "GenSigSendType" SG_ 184 EM1_Eta_Sys "Cyclic";
BA_ "GenSigStartValue" SG_ 184 EM1_Eta_Sys 510;
BA_ "GenSigSwitchedByIgnition" SG_ 184 EM1_Eta_Sys "No";
BA_ "Fehlerwert" SG_ 184 EM1_Eta_Sys 511;
BA_ "GenSigSendType" SG_ 184 EM1_IstStrom "Cyclic";
BA_ "GenSigStartValue" SG_ 184 EM1_IstStrom 2046;
BA_ "GenSigSwitchedByIgnition" SG_ 184 EM1_IstStrom "No";
BA_ "Fehlerwert" SG_ 184 EM1_IstStrom 2047;
BA_ "GenSigSendType" SG_ 184 EM1_Fehler_ElAntriebFreilauf_Anf "Cyclic";
BA_ "GenSigSwitchedByIgnition" SG_ 184 EM1_Fehler_ElAntriebFreilauf_Anf "No";
BA_ "GenSigSendType" SG_ 184 EM1_Abregelung_Temperatur "Cyclic";
BA_ "GenSigSwitchedByIgnition" SG_ 184 EM1_Abregelung_Temperatur "No";
BA_ "GenSigSendType" SG_ 184 EM1_AnlernenElMotor_Anf "Cyclic";
BA_ "GenSigSwitchedByIgnition" SG_ 184 EM1_AnlernenElMotor_Anf "No";
BA_ "GenSigSendType" SG_ 184 EM1_Moment_HVVerbraucher "Cyclic";
BA_ "GenSigStartValue" SG_ 184 EM1_Moment_HVVerbraucher 1023;
BA_ "GenSigSwitchedByIgnition" SG_ 184 EM1_Moment_HVVerbraucher "No";
BA_ "GenSigSendType" SG_ 184 EM1_Freigabe_Verfallsinfo_WFS "OnChange";
BA_ "GenSigSwitchedByIgnition" SG_ 184 EM1_Freigabe_Verfallsinfo_WFS "No";
BA_ "GenSigSendType" SG_ 184 EM1_Parken_WFS_Status "Cyclic";
BA_ "GenSigSwitchedByIgnition" SG_ 184 EM1_Parken_WFS_Status "No";
BA_ "GenSigSendType" SG_ 184 EM1_HV_betriebsbereit "Cyclic";
BA_ "GenSigSwitchedByIgnition" SG_ 184 EM1_HV_betriebsbereit "No";
BA_ "GenSigSendType" SG_ 2527679712 EM1_RtmWarnKommunikation "Cyclic";
BA_ "GenSigSwitchedByIgnition" SG_ 2527679712 EM1_RtmWarnKommunikation "No";
BA_ "GenSigSendType" SG_ 2527679712 EM1_RtmWarnUeberdrehzahl "Cyclic";
BA_ "GenSigSwitchedByIgnition" SG_ 2527679712 EM1_RtmWarnUeberdrehzahl "No";
BA_ "GenSigSendType" SG_ 2527679712 EM1_RtmWarnUeberstrom "Cyclic";
BA_ "GenSigSwitchedByIgnition" SG_ 2527679712 EM1_RtmWarnUeberstrom "No";
BA_ "GenSigSendType" SG_ 2527679712 EM1_RtmWarnTempEM "Cyclic";
BA_ "GenSigSwitchedByIgnition" SG_ 2527679712 EM1_RtmWarnTempEM "No";
BA_ "GenSigSendType" SG_ 2527679712 EM1_RtmWarnTempPWR "Cyclic";
BA_ "GenSigSwitchedByIgnition" SG_ 2527679712 EM1_RtmWarnTempPWR "No";
BA_ "GenSigSendType" SG_ 193 EM2_01_CRC "Cyclic";
BA_ "GenSigFuncType" SG_ 193 EM2_01_CRC "CRC-8";
BA_ "GenSigSwitchedByIgnition" SG_ 193 EM2_01_CRC "No";
BA_ "GenSigSendType" SG_ 193 EM2_01_BZ "Cyclic";
BA_ "GenSigFuncType" SG_ 193 EM2_01_BZ "MsgCounter";
BA_ "GenSigSwitchedByIgnition" SG_ 193 EM2_01_BZ "No";
BA_ "GenSigSendType" SG_ 193 EM2_Istmodus "Cyclic";
BA_ "GenSigStartValue" SG_ 193 EM2_Istmodus 15;
BA_ "GenSigSwitchedByIgnition" SG_ 193 EM2_Istmodus "No";
BA_ "GenSigSendType" SG_ 193 EM2_IstMoment "Cyclic";
BA_ "GenSigStartValue" SG_ 193 EM2_IstMoment 4094;
BA_ "GenSigSwitchedByIgnition" SG_ 193 EM2_IstMoment "No";
BA_ "Fehlerwert" SG_ 193 EM2_IstMoment 4095;
BA_ "GenSigSendType" SG_ 193 EM2_Moment_AR_Eingriff "Cyclic";
BA_ "GenSigStartValue" SG_ 193 EM2_Moment_AR_Eingriff 4094;
BA_ "GenSigSwitchedByIgnition" SG_ 193 EM2_Moment_AR_Eingriff "No";
BA_ "Fehlerwert" SG_ 193 EM2_Moment_AR_Eingriff 4095;
BA_ "GenSigSendType" SG_ 193 EM2_IstDrehzahl "Cyclic";
BA_ "GenSigStartValue" SG_ 193 EM2_IstDrehzahl 32766;
BA_ "GenSigSwitchedByIgnition" SG_ 193 EM2_IstDrehzahl "No";
BA_ "Fehlerwert" SG_ 193 EM2_IstDrehzahl 32767;
BA_ "GenSigSendType" SG_ 193 EM2_AR_aktiv "Cyclic";
BA_ "GenSigSwitchedByIgnition" SG_ 193 EM2_AR_aktiv "No";
BA_ "GenSigSendType" SG_ 193 EM2_IstSpannung "Cyclic";
BA_ "GenSigStartValue" SG_ 193 EM2_IstSpannung 4094;
BA_ "GenSigSwitchedByIgnition" SG_ 193 EM2_IstSpannung "No";
BA_ "Fehlerwert" SG_ 193 EM2_IstSpannung 4095;
BA_ "GenSigSendType" SG_ 193 EM2_Strom_HV "Cyclic";
BA_ "GenSigStartValue" SG_ 193 EM2_Strom_HV 4094;
BA_ "GenSigSwitchedByIgnition" SG_ 193 EM2_Strom_HV "No";
BA_ "Fehlerwert" SG_ 193 EM2_Strom_HV 4095;
BA_ "GenSigSendType" SG_ 193 EM2_Max_Moment "Cyclic";
BA_ "GenSigStartValue" SG_ 193 EM2_Max_Moment 2046;
BA_ "GenSigSwitchedByIgnition" SG_ 193 EM2_Max_Moment "No";
BA_ "Fehlerwert" SG_ 193 EM2_Max_Moment 2047;
BA_ "GenSigSendType" SG_ 193 EM2_ErwGrenzen_aktiv "Cyclic";
BA_ "GenSigSwitchedByIgnition" SG_ 193 EM2_ErwGrenzen_aktiv "No";
BA_ "GenSigSendType" SG_ 193 EM2_Min_Moment "Cyclic";
BA_ "GenSigStartValue" SG_ 193 EM2_Min_Moment 2046;
BA_ "GenSigSwitchedByIgnition" SG_ 193 EM2_Min_Moment "No";
BA_ "Fehlerwert" SG_ 193 EM2_Min_Moment 2047;
BA_ "GenSigSendType" SG_ 193 EM2_Fehler_ElAntriebAbschaltung "Cyclic";
BA_ "GenSigSwitchedByIgnition" SG_ 193 EM2_Fehler_ElAntriebAbschaltung "No";
BA_ "GenSigSendType" SG_ 193 EM2_Max_Moment_Lim "Cyclic";
BA_ "GenSigStartValue" SG_ 193 EM2_Max_Moment_Lim 2046;
BA_ "GenSigSwitchedByIgnition" SG_ 193 EM2_Max_Moment_Lim "No";
BA_ "Fehlerwert" SG_ 193 EM2_Max_Moment_Lim 2047;
BA_ "GenSigSendType" SG_ 193 EM2_Fehler_Notabschaltung "Cyclic";
BA_ "GenSigSwitchedByIgnition" SG_ 193 EM2_Fehler_Notabschaltung "No";
BA_ "Fehlerwert" SG_ 193 EM2_Fehler_Notabschaltung 1;
BA_ "GenSigSendType" SG_ 193 EM2_Min_Moment_Lim "Cyclic";
BA_ "GenSigStartValue" SG_ 193 EM2_Min_Moment_Lim 2046;
BA_ "GenSigSwitchedByIgnition" SG_ 193 EM2_Min_Moment_Lim "No";
BA_ "Fehlerwert" SG_ 193 EM2_Min_Moment_Lim 2047;
BA_ "GenSigSendType" SG_ 193 EM2_Status_DrzEingriff "Cyclic";
BA_ "GenSigSwitchedByIgnition" SG_ 193 EM2_Status_DrzEingriff "No";
BA_ "Fehlerwert" SG_ 193 EM2_Status_DrzEingriff 3;
BA_ "GenSigSendType" SG_ 193 EM2_Mom_DrzEingriff "Cyclic";
BA_ "GenSigStartValue" SG_ 193 EM2_Mom_DrzEingriff 2046;
BA_ "GenSigSwitchedByIgnition" SG_ 193 EM2_Mom_DrzEingriff "No";
BA_ "Fehlerwert" SG_ 193 EM2_Mom_DrzEingriff 2047;
BA_ "GenSigSendType" SG_ 2463978674 EM2_Status_Spgfreiheit "Cyclic";
BA_ "GenSigSwitchedByIgnition" SG_ 2463978674 EM2_Status_Spgfreiheit "No";
BA_ "GenSigSendType" SG_ 2463978674 EM2_Status_EoHVL "Cyclic";
BA_ "GenSigSwitchedByIgnition" SG_ 2463978674 EM2_Status_EoHVL "No";
BA_ "Fehlerwert" SG_ 2463978674 EM2_Status_EoHVL 3;
BA_ "GenSigSendType" SG_ 2463978674 EM2_Max_LeistungMech_Sockel "Cyclic";
BA_ "GenSigStartValue" SG_ 2463978674 EM2_Max_LeistungMech_Sockel 8190;
BA_ "GenSigSwitchedByIgnition" SG_ 2463978674 EM2_Max_LeistungMech_Sockel "No";
BA_ "Fehlerwert" SG_ 2463978674 EM2_Max_LeistungMech_Sockel 8191;
BA_ "GenSigSendType" SG_ 2463978674 EM2_Max_Moment_Sockel "Cyclic";
BA_ "GenSigStartValue" SG_ 2463978674 EM2_Max_Moment_Sockel 2046;
BA_ "GenSigSwitchedByIgnition" SG_ 2463978674 EM2_Max_Moment_Sockel "No";
BA_ "Fehlerwert" SG_ 2463978674 EM2_Max_Moment_Sockel 2047;
BA_ "GenSigSendType" SG_ 2463978674 EM2_Min_LeistungMech_Sockel "Cyclic";
BA_ "GenSigStartValue" SG_ 2463978674 EM2_Min_LeistungMech_Sockel 8190;
BA_ "GenSigSwitchedByIgnition" SG_ 2463978674 EM2_Min_LeistungMech_Sockel "No";
BA_ "Fehlerwert" SG_ 2463978674 EM2_Min_LeistungMech_Sockel 8191;
BA_ "GenSigSendType" SG_ 2463978674 EM2_Min_Moment_Sockel "Cyclic";
BA_ "GenSigStartValue" SG_ 2463978674 EM2_Min_Moment_Sockel 2046;
BA_ "GenSigSwitchedByIgnition" SG_ 2463978674 EM2_Min_Moment_Sockel "No";
BA_ "Fehlerwert" SG_ 2463978674 EM2_Min_Moment_Sockel 2047;
BA_ "GenSigSendType" SG_ 2463978674 EM2_PerfInd_MaxLeistung "Cyclic";
BA_ "GenSigStartValue" SG_ 2463978674 EM2_PerfInd_MaxLeistung 1022;
BA_ "GenSigSwitchedByIgnition" SG_ 2463978674 EM2_PerfInd_MaxLeistung "No";
BA_ "GenSigSendType" SG_ 2463978674 EM2_PerfInd_MaxMoment "Cyclic";
BA_ "GenSigStartValue" SG_ 2463978674 EM2_PerfInd_MaxMoment 1022;
BA_ "GenSigSwitchedByIgnition" SG_ 2463978674 EM2_PerfInd_MaxMoment "No";
BA_ "GenSigSendType" SG_ 2463978674 EM2_AnlernenElMotor_Anf "Cyclic";
BA_ "GenSigSwitchedByIgnition" SG_ 2463978674 EM2_AnlernenElMotor_Anf "No";
BA_ "GenSigSendType" SG_ 2463978674 EM2_OBD_Lampe_Anf "Cyclic";
BA_ "GenSigSwitchedByIgnition" SG_ 2463978674 EM2_OBD_Lampe_Anf "No";
BA_ "GenSigSendType" SG_ 2463978674 EM2_Generator_Moment "Cyclic";
BA_ "GenSigStartValue" SG_ 2463978674 EM2_Generator_Moment 1022;
BA_ "GenSigSwitchedByIgnition" SG_ 2463978674 EM2_Generator_Moment "No";
BA_ "Fehlerwert" SG_ 2463978674 EM2_Generator_Moment 1023;
BA_ "GenSigSendType" SG_ 2463978674 EM2_PerfInd_Temperatur "Cyclic";
BA_ "GenSigStartValue" SG_ 2463978674 EM2_PerfInd_Temperatur 254;
BA_ "GenSigSwitchedByIgnition" SG_ 2463978674 EM2_PerfInd_Temperatur "No";
BA_ "GenSigSendType" SG_ 2463978674 EM2_MaxZul_Drehzahl "Cyclic";
BA_ "GenSigStartValue" SG_ 2463978674 EM2_MaxZul_Drehzahl 254;
BA_ "GenSigSwitchedByIgnition" SG_ 2463978674 EM2_MaxZul_Drehzahl "No";
BA_ "Fehlerwert" SG_ 2463978674 EM2_MaxZul_Drehzahl 255;
BA_ "GenSigSendType" SG_ 2463978674 EM2_Min_Moment_Gesamt "Cyclic";
BA_ "GenSigStartValue" SG_ 2463978674 EM2_Min_Moment_Gesamt 2046;
BA_ "GenSigSwitchedByIgnition" SG_ 2463978674 EM2_Min_Moment_Gesamt "No";
BA_ "Fehlerwert" SG_ 2463978674 EM2_Min_Moment_Gesamt 2047;
BA_ "GenSigSendType" SG_ 2463978674 EM2_Fehlerlampe_Anf "Cyclic";
BA_ "GenSigSwitchedByIgnition" SG_ 2463978674 EM2_Fehlerlampe_Anf "No";
BA_ "GenSigSendType" SG_ 2463978674 EM2_Max_Moment_Gesamt "Cyclic";
BA_ "GenSigStartValue" SG_ 2463978674 EM2_Max_Moment_Gesamt 2046;
BA_ "GenSigSwitchedByIgnition" SG_ 2463978674 EM2_Max_Moment_Gesamt "No";
BA_ "Fehlerwert" SG_ 2463978674 EM2_Max_Moment_Gesamt 2047;
BA_ "GenSigSendType" SG_ 2463978674 EM2_Warnlampe_Anf "Cyclic";
BA_ "GenSigSwitchedByIgnition" SG_ 2463978674 EM2_Warnlampe_Anf "No";
BA_ "GenSigSendType" SG_ 2463978674 EM2_Rekuperation "Cyclic";
BA_ "GenSigSwitchedByIgnition" SG_ 2463978674 EM2_Rekuperation "No";
BA_ "GenSigSendType" SG_ 2463978674 EM2_Rekuperation_Ueberlauf "Cyclic";
BA_ "GenSigSwitchedByIgnition" SG_ 2463978674 EM2_Rekuperation_Ueberlauf "No";
BA_ "GenSigSendType" SG_ 2463978674 EM2_Verbrauch "Cyclic";
BA_ "GenSigSwitchedByIgnition" SG_ 2463978674 EM2_Verbrauch "No";
BA_ "GenSigSendType" SG_ 2463978674 EM2_Verbrauch_Ueberlauf "Cyclic";
BA_ "GenSigSwitchedByIgnition" SG_ 2463978674 EM2_Verbrauch_Ueberlauf "No";
BA_ "GenSigSendType" SG_ 2463978674 EM2_Fehler_AE "Cyclic";
BA_ "GenSigSwitchedByIgnition" SG_ 2463978674 EM2_Fehler_AE "No";
BA_ "GenSigSendType" SG_ 2463978674 EM2_Fehler_Leistungsred "Cyclic";
BA_ "GenSigSwitchedByIgnition" SG_ 2463978674 EM2_Fehler_Leistungsred "No";
BA_ "GenSigSendType" SG_ 2463978674 EM2_Fehler_ElAntriebFreilauf "Cyclic";
BA_ "GenSigSwitchedByIgnition" SG_ 2463978674 EM2_Fehler_ElAntriebFreilauf "No";
BA_ "GenSigSendType" SG_ 2463978674 EM2_PWR_SollVolumenstrom "Cyclic";
BA_ "GenSigStartValue" SG_ 2463978674 EM2_PWR_SollVolumenstrom 62;
BA_ "GenSigSwitchedByIgnition" SG_ 2463978674 EM2_PWR_SollVolumenstrom "No";
BA_ "Fehlerwert" SG_ 2463978674 EM2_PWR_SollVolumenstrom 63;
BA_ "GenSigSendType" SG_ 2589283660 EM2_SollVorlauftemperatur "Cyclic";
BA_ "GenSigStartValue" SG_ 2589283660 EM2_SollVorlauftemperatur 254;
BA_ "GenSigSwitchedByIgnition" SG_ 2589283660 EM2_SollVorlauftemperatur "No";
BA_ "Fehlerwert" SG_ 2589283660 EM2_SollVorlauftemperatur 255;
BA_ "GenSigSendType" SG_ 2589283660 EM2_Temperatur_EM "Cyclic";
BA_ "GenSigStartValue" SG_ 2589283660 EM2_Temperatur_EM 510;
BA_ "GenSigSwitchedByIgnition" SG_ 2589283660 EM2_Temperatur_EM "No";
BA_ "Fehlerwert" SG_ 2589283660 EM2_Temperatur_EM 511;
BA_ "GenSigSendType" SG_ 2589283660 EM2_EM_SollVolumenstrom "Cyclic";
BA_ "GenSigStartValue" SG_ 2589283660 EM2_EM_SollVolumenstrom 62;
BA_ "GenSigSwitchedByIgnition" SG_ 2589283660 EM2_EM_SollVolumenstrom "No";
BA_ "Fehlerwert" SG_ 2589283660 EM2_EM_SollVolumenstrom 63;
BA_ "GenSigSendType" SG_ 2589283660 EM2_Max_MechLeistung_nom "Cyclic";
BA_ "GenSigStartValue" SG_ 2589283660 EM2_Max_MechLeistung_nom 4094;
BA_ "GenSigSwitchedByIgnition" SG_ 2589283660 EM2_Max_MechLeistung_nom "No";
BA_ "Fehlerwert" SG_ 2589283660 EM2_Max_MechLeistung_nom 4095;
BA_ "GenSigSendType" SG_ 2589283660 EM2_Max_Moment_nom "Cyclic";
BA_ "GenSigStartValue" SG_ 2589283660 EM2_Max_Moment_nom 1022;
BA_ "GenSigSwitchedByIgnition" SG_ 2589283660 EM2_Max_Moment_nom "No";
BA_ "Fehlerwert" SG_ 2589283660 EM2_Max_Moment_nom 1023;
BA_ "GenSigSendType" SG_ 2589283660 EM2_Temperatur_PWR "Cyclic";
BA_ "GenSigStartValue" SG_ 2589283660 EM2_Temperatur_PWR 254;
BA_ "GenSigSwitchedByIgnition" SG_ 2589283660 EM2_Temperatur_PWR "No";
BA_ "Fehlerwert" SG_ 2589283660 EM2_Temperatur_PWR 255;
BA_ "GenSigSendType" SG_ 199 EM2_Freigabe_Info_WFS "OnChange";
BA_ "GenSigSwitchedByIgnition" SG_ 199 EM2_Freigabe_Info_WFS "No";
BA_ "GenSigSendType" SG_ 199 EM2_Sperr_Info_WFS "OnChange";
BA_ "GenSigSwitchedByIgnition" SG_ 199 EM2_Sperr_Info_WFS "No";
BA_ "GenSigSendType" SG_ 199 EM2_AR_aktiv "Cyclic";
BA_ "GenSigSwitchedByIgnition" SG_ 199 EM2_AR_aktiv "No";
BA_ "GenSigSendType" SG_ 199 EM2_Eta_Sys "Cyclic";
BA_ "GenSigStartValue" SG_ 199 EM2_Eta_Sys 510;
BA_ "GenSigSwitchedByIgnition" SG_ 199 EM2_Eta_Sys "No";
BA_ "Fehlerwert" SG_ 199 EM2_Eta_Sys 511;
BA_ "GenSigSendType" SG_ 199 EM2_IstStrom "Cyclic";
BA_ "GenSigStartValue" SG_ 199 EM2_IstStrom 2046;
BA_ "GenSigSwitchedByIgnition" SG_ 199 EM2_IstStrom "No";
BA_ "Fehlerwert" SG_ 199 EM2_IstStrom 2047;
BA_ "GenSigSendType" SG_ 199 EM2_Fehler_ElAntriebFreilauf_Anf "Cyclic";
BA_ "GenSigSwitchedByIgnition" SG_ 199 EM2_Fehler_ElAntriebFreilauf_Anf "No";
BA_ "GenSigSendType" SG_ 199 EM2_Abregelung_Temperatur "Cyclic";
BA_ "GenSigSwitchedByIgnition" SG_ 199 EM2_Abregelung_Temperatur "No";
BA_ "GenSigSendType" SG_ 199 EM2_AnlernenElMotor_Anf "Cyclic";
BA_ "GenSigSwitchedByIgnition" SG_ 199 EM2_AnlernenElMotor_Anf "No";
BA_ "GenSigSendType" SG_ 199 EM2_Freigabe_Verfallsinfo_WFS "OnChange";
BA_ "GenSigSwitchedByIgnition" SG_ 199 EM2_Freigabe_Verfallsinfo_WFS "No";
BA_ "GenSigSendType" SG_ 199 EM2_Parken_WFS_Status "Cyclic";
BA_ "GenSigSwitchedByIgnition" SG_ 199 EM2_Parken_WFS_Status "No";
BA_ "GenSigSendType" SG_ 199 EM2_HV_betriebsbereit "Cyclic";
BA_ "GenSigSwitchedByIgnition" SG_ 199 EM2_HV_betriebsbereit "No";
BA_ "GenSigSendType" SG_ 2527679713 EM2_RtmWarnKommunikation "Cyclic";
BA_ "GenSigSwitchedByIgnition" SG_ 2527679713 EM2_RtmWarnKommunikation "No";
BA_ "GenSigSendType" SG_ 2527679713 EM2_RtmWarnUeberdrehzahl "Cyclic";
BA_ "GenSigSwitchedByIgnition" SG_ 2527679713 EM2_RtmWarnUeberdrehzahl "No";
BA_ "GenSigSendType" SG_ 2527679713 EM2_RtmWarnUeberstrom "Cyclic";
BA_ "GenSigSwitchedByIgnition" SG_ 2527679713 EM2_RtmWarnUeberstrom "No";
BA_ "GenSigSendType" SG_ 2527679713 EM2_RtmWarnTempEM "Cyclic";
BA_ "GenSigSwitchedByIgnition" SG_ 2527679713 EM2_RtmWarnTempEM "No";
BA_ "GenSigSendType" SG_ 2527679713 EM2_RtmWarnTempPWR "Cyclic";
BA_ "GenSigSwitchedByIgnition" SG_ 2527679713 EM2_RtmWarnTempPWR "No";
BA_ "GenSigSendType" SG_ 2589283649 EML_02_CRC "Cyclic";
BA_ "GenSigFuncType" SG_ 2589283649 EML_02_CRC "CRC-8";
BA_ "GenSigSendType" SG_ 2589283649 EML_02_BZ "Cyclic";
BA_ "GenSigFuncType" SG_ 2589283649 EML_02_BZ "MsgCounter";
BA_ "GenSigSendType" SG_ 2589283649 EML_ReifenKorrFaktorHL "Cyclic";
BA_ "GenSigStartValue" SG_ 2589283649 EML_ReifenKorrFaktorHL 510;
BA_ "Fehlerwert" SG_ 2589283649 EML_ReifenKorrFaktorHL 511;
BA_ "GenSigSendType" SG_ 2589283649 EML_ReifenKorrFaktorHR "Cyclic";
BA_ "GenSigStartValue" SG_ 2589283649 EML_ReifenKorrFaktorHR 510;
BA_ "Fehlerwert" SG_ 2589283649 EML_ReifenKorrFaktorHR 511;
BA_ "GenSigSendType" SG_ 2589283649 EML_ReifenKorrFaktorVL "Cyclic";
BA_ "GenSigStartValue" SG_ 2589283649 EML_ReifenKorrFaktorVL 510;
BA_ "Fehlerwert" SG_ 2589283649 EML_ReifenKorrFaktorVL 511;
BA_ "GenSigSendType" SG_ 2589283649 EML_ReifenKorrFaktorVR "Cyclic";
BA_ "GenSigStartValue" SG_ 2589283649 EML_ReifenKorrFaktorVR 510;
BA_ "Fehlerwert" SG_ 2589283649 EML_ReifenKorrFaktorVR 511;
BA_ "GenSigSendType" SG_ 2589283649 EML_Reifenumfang "Cyclic";
BA_ "GenSigSwitchedByIgnition" SG_ 2589283649 EML_Reifenumfang "No";
BA_ "GenSigSendType" SG_ 2589283649 EML_QBit_Reifenumfang "Cyclic";
BA_ "GenSigStartValue" SG_ 2589283649 EML_QBit_Reifenumfang 1;
BA_ "GenSigSwitchedByIgnition" SG_ 2589283649 EML_QBit_Reifenumfang "No";
BA_ "GenSigSendType" SG_ 608 EML_AnzeigeGeschw "Cyclic";
BA_ "GenSigStartValue" SG_ 608 EML_AnzeigeGeschw 1022;
BA_ "Fehlerwert" SG_ 608 EML_AnzeigeGeschw 1023;
BA_ "GenSigSendType" SG_ 2589283751 KBI_Kilometerstand_HiRes_meter "Cyclic";
BA_ "GenSigSwitchedByIgnition" SG_ 2589283751 KBI_Kilometerstand_HiRes_meter "No";
BA_ "GenSigSendType" SG_ 2527679687 EPS_ASM_Ereignis "OnChange";
BA_ "GenSigSendType" SG_ 2527679687 EPS_ASM_Zeitstempel "OnChange";
BA_ "GenSigStartValue" SG_ 2527679687 EPS_ASM_Zeitstempel 255;
BA_ "GenSigSendType" SG_ 2527679687 EPS_ASM_Data_1 "Cyclic";
BA_ "GenSigSendType" SG_ 2527679687 EPS_ASM_Data_2 "Cyclic";
BA_ "GenSigSendType" SG_ 2527679687 EPS_ASM_Data_3 "Cyclic";
BA_ "GenSigSendType" SG_ 2527679687 EPS_ASM_Data_4 "Cyclic";
BA_ "GenSigSendType" SG_ 2527679687 EPS_ASM_Data_5 "Cyclic";
BA_ "GenSigSendType" SG_ 2527679687 EPS_ASM_Data_6 "Cyclic";
BA_ "GenSigSendType" SG_ 258 ESC_50_CRC "Cyclic";
BA_ "GenSigFuncType" SG_ 258 ESC_50_CRC "CRC-8";
BA_ "GenSigSwitchedByIgnition" SG_ 258 ESC_50_CRC "No";
BA_ "GenSigSendType" SG_ 258 ESC_50_BZ "Cyclic";
BA_ "GenSigFuncType" SG_ 258 ESC_50_BZ "MsgCounter";
BA_ "GenSigSwitchedByIgnition" SG_ 258 ESC_50_BZ "No";
BA_ "GenSigSendType" SG_ 258 ESP_QBit_Gierrate "Cyclic";
BA_ "GenSigStartValue" SG_ 258 ESP_QBit_Gierrate 1;
BA_ "GenSigSwitchedByIgnition" SG_ 258 ESP_QBit_Gierrate "No";
BA_ "GenSigSendType" SG_ 258 ESP_QBit_Laengsbeschl "Cyclic";
BA_ "GenSigStartValue" SG_ 258 ESP_QBit_Laengsbeschl 1;
BA_ "GenSigSwitchedByIgnition" SG_ 258 ESP_QBit_Laengsbeschl "No";
BA_ "GenSigSendType" SG_ 258 ESP_QBit_Querb "Cyclic";
BA_ "GenSigStartValue" SG_ 258 ESP_QBit_Querb 1;
BA_ "GenSigSwitchedByIgnition" SG_ 258 ESP_QBit_Querb "No";
BA_ "GenSigSendType" SG_ 258 ESP_Querbeschleunigung "Cyclic";
BA_ "GenSigStartValue" SG_ 258 ESP_Querbeschleunigung 127;
BA_ "GenSigSwitchedByIgnition" SG_ 258 ESP_Querbeschleunigung "No";
BA_ "Fehlerwert" SG_ 258 ESP_Querbeschleunigung 255;
BA_ "GenSigSendType" SG_ 258 ESP_Laengsbeschl "Cyclic";
BA_ "GenSigStartValue" SG_ 258 ESP_Laengsbeschl 512;
BA_ "GenSigSwitchedByIgnition" SG_ 258 ESP_Laengsbeschl "No";
BA_ "Fehlerwert" SG_ 258 ESP_Laengsbeschl 1023;
BA_ "GenSigSendType" SG_ 258 ESC_Motorstartverzoegerung "Cyclic";
BA_ "GenSigSwitchedByIgnition" SG_ 258 ESC_Motorstartverzoegerung "No";
BA_ "GenSigSendType" SG_ 258 ESC_SeitenwindAssistent_Eingriff "Cyclic";
BA_ "GenSigSwitchedByIgnition" SG_ 258 ESC_SeitenwindAssistent_Eingriff "No";
BA_ "GenSigSendType" SG_ 258 ESP_Anschleppstart_Freigabe "Cyclic";
BA_ "GenSigSwitchedByIgnition" SG_ 258 ESP_Anschleppstart_Freigabe "No";
BA_ "GenSigSendType" SG_ 258 ESC_Unterdruckmangel_erkannt "Cyclic";
BA_ "GenSigSwitchedByIgnition" SG_ 258 ESC_Unterdruckmangel_erkannt "No";
BA_ "GenSigSendType" SG_ 258 ESP_Gierrate "Cyclic";
BA_ "GenSigSwitchedByIgnition" SG_ 258 ESP_Gierrate "No";
BA_ "Fehlerwert" SG_ 258 ESP_Gierrate 16383;
BA_ "GenSigSendType" SG_ 258 ESP_VZ_Gierrate "Cyclic";
BA_ "GenSigSwitchedByIgnition" SG_ 258 ESP_VZ_Gierrate "No";
BA_ "GenSigSendType" SG_ 258 ESP_Notbremsanzeige "Cyclic";
BA_ "GenSigSwitchedByIgnition" SG_ 258 ESP_Notbremsanzeige "No";
BA_ "GenSigSendType" SG_ 258 ESP_SpannungsAnf "Cyclic";
BA_ "GenSigSwitchedByIgnition" SG_ 258 ESP_SpannungsAnf "No";
BA_ "GenSigSendType" SG_ 258 ESP_PLA_Abbruch "Cyclic";
BA_ "GenSigSwitchedByIgnition" SG_ 258 ESP_PLA_Abbruch "No";
BA_ "GenSigSendType" SG_ 258 ESP_Status_ESP_PLA "Cyclic";
BA_ "GenSigSwitchedByIgnition" SG_ 258 ESP_Status_ESP_PLA "No";
BA_ "GenSigSendType" SG_ 258 ESP_QBit_Bremsdruck "Cyclic";
BA_ "GenSigStartValue" SG_ 258 ESP_QBit_Bremsdruck 1;
BA_ "GenSigSwitchedByIgnition" SG_ 258 ESP_QBit_Bremsdruck "No";
BA_ "GenSigSendType" SG_ 258 ESP_QBit_Fahrer_bremst "Cyclic";
BA_ "GenSigStartValue" SG_ 258 ESP_QBit_Fahrer_bremst 1;
BA_ "GenSigSwitchedByIgnition" SG_ 258 ESP_QBit_Fahrer_bremst "No";
BA_ "GenSigSendType" SG_ 258 ESP_Schwelle_Unterdruck "Cyclic";
BA_ "GenSigSwitchedByIgnition" SG_ 258 ESP_Schwelle_Unterdruck "No";
BA_ "GenSigSendType" SG_ 258 ESP_Bremsdruck "Cyclic";
BA_ "GenSigStartValue" SG_ 258 ESP_Bremsdruck 100;
BA_ "GenSigSwitchedByIgnition" SG_ 258 ESP_Bremsdruck "No";
BA_ "Fehlerwert" SG_ 258 ESP_Bremsdruck 1023;
BA_ "GenSigSendType" SG_ 258 ESP_Fahrer_bremst "Cyclic";
BA_ "GenSigSwitchedByIgnition" SG_ 258 ESP_Fahrer_bremst "No";
BA_ "GenSigSendType" SG_ 258 ESP_Verz_TSK_aktiv "Cyclic";
BA_ "GenSigSwitchedByIgnition" SG_ 258 ESP_Verz_TSK_aktiv "No";
BA_ "GenSigSendType" SG_ 258 ESP_Lenkeingriff_ADS "Cyclic";
BA_ "GenSigSwitchedByIgnition" SG_ 258 ESP_Lenkeingriff_ADS "No";
BA_ "GenSigSendType" SG_ 258 ESP_Konsistenz_TSK "Cyclic";
BA_ "GenSigSwitchedByIgnition" SG_ 258 ESP_Konsistenz_TSK "No";
BA_ "GenSigSendType" SG_ 258 ESP_Bremsruck_AWV2 "Cyclic";
BA_ "GenSigSwitchedByIgnition" SG_ 258 ESP_Bremsruck_AWV2 "No";
BA_ "GenSigSendType" SG_ 258 ESP_Konsistenz_AWV2 "Cyclic";
BA_ "GenSigSwitchedByIgnition" SG_ 258 ESP_Konsistenz_AWV2 "No";
BA_ "GenSigSendType" SG_ 258 ECD_Fehler "Cyclic";
BA_ "GenSigSwitchedByIgnition" SG_ 258 ECD_Fehler "No";
BA_ "GenSigSendType" SG_ 258 ECD_nicht_verfuegbar "Cyclic";
BA_ "GenSigStartValue" SG_ 258 ECD_nicht_verfuegbar 1;
BA_ "GenSigSwitchedByIgnition" SG_ 258 ECD_nicht_verfuegbar "No";
BA_ "GenSigSendType" SG_ 258 ESP_Status_Bremsentemp "Cyclic";
BA_ "GenSigSwitchedByIgnition" SG_ 258 ESP_Status_Bremsentemp "No";
BA_ "GenSigSendType" SG_ 258 ESP_Autohold_Standby "Cyclic";
BA_ "GenSigSwitchedByIgnition" SG_ 258 ESP_Autohold_Standby "No";
BA_ "GenSigSendType" SG_ 258 ESP_HDC_Standby "Cyclic";
BA_ "GenSigSwitchedByIgnition" SG_ 258 ESP_HDC_Standby "No";
BA_ "GenSigSendType" SG_ 258 ESP_HBA_aktiv "Cyclic";
BA_ "GenSigSwitchedByIgnition" SG_ 258 ESP_HBA_aktiv "No";
BA_ "GenSigSendType" SG_ 258 ESP_Prefill_ausgeloest "Cyclic";
BA_ "GenSigSwitchedByIgnition" SG_ 258 ESP_Prefill_ausgeloest "No";
BA_ "GenSigSendType" SG_ 258 ESP_Rueckwaertsfahrt_erkannt "Cyclic";
BA_ "GenSigSwitchedByIgnition" SG_ 258 ESP_Rueckwaertsfahrt_erkannt "No";
BA_ "GenSigSendType" SG_ 258 ESP_Status_Anfahrhilfe "Cyclic";
BA_ "GenSigSwitchedByIgnition" SG_ 258 ESP_Status_Anfahrhilfe "No";
BA_ "GenSigSendType" SG_ 258 ESP_HDC_aktiv "Cyclic";
BA_ "GenSigSwitchedByIgnition" SG_ 258 ESP_HDC_aktiv "No";
BA_ "GenSigSendType" SG_ 258 ESP_StartStopp_Info "Cyclic";
BA_ "GenSigSwitchedByIgnition" SG_ 258 ESP_StartStopp_Info "No";
BA_ "GenSigSendType" SG_ 258 ESP_Eingr_HL "Cyclic";
BA_ "GenSigSwitchedByIgnition" SG_ 258 ESP_Eingr_HL "No";
BA_ "GenSigSendType" SG_ 258 ESP_Eingr_HR "Cyclic";
BA_ "GenSigSwitchedByIgnition" SG_ 258 ESP_Eingr_HR "No";
BA_ "GenSigSendType" SG_ 258 ESP_Eingr_VL "Cyclic";
BA_ "GenSigSwitchedByIgnition" SG_ 258 ESP_Eingr_VL "No";
BA_ "GenSigSendType" SG_ 258 ESP_Eingr_VR "Cyclic";
BA_ "GenSigSwitchedByIgnition" SG_ 258 ESP_Eingr_VR "No";
BA_ "GenSigSendType" SG_ 258 ESP_BKV_Unterdruck "Cyclic";
BA_ "GenSigStartValue" SG_ 258 ESP_BKV_Unterdruck 254;
BA_ "GenSigSwitchedByIgnition" SG_ 258 ESP_BKV_Unterdruck "No";
BA_ "Fehlerwert" SG_ 258 ESP_BKV_Unterdruck 255;
BA_ "GenSigSendType" SG_ 258 ESP_Autohold_aktiv "Cyclic";
BA_ "GenSigSwitchedByIgnition" SG_ 258 ESP_Autohold_aktiv "No";
BA_ "GenSigSendType" SG_ 258 ESP_FStatus_Anfahrhilfe "Cyclic";
BA_ "GenSigSwitchedByIgnition" SG_ 258 ESP_FStatus_Anfahrhilfe "No";
BA_ "Fehlerwert" SG_ 258 ESP_FStatus_Anfahrhilfe 1;
BA_ "GenSigSendType" SG_ 258 ESP_Verz_EPB_aktiv "Cyclic";
BA_ "GenSigSwitchedByIgnition" SG_ 258 ESP_Verz_EPB_aktiv "No";
BA_ "GenSigSendType" SG_ 258 ECD_Bremslicht "Cyclic";
BA_ "GenSigSwitchedByIgnition" SG_ 258 ECD_Bremslicht "No";
BA_ "GenSigSendType" SG_ 258 ESP_Verzoeg_EPB_verf "Cyclic";
BA_ "GenSigSwitchedByIgnition" SG_ 258 ESP_Verzoeg_EPB_verf "No";
BA_ "GenSigSendType" SG_ 258 ESP_Status_Bremsdruck "Cyclic";
BA_ "GenSigSwitchedByIgnition" SG_ 258 ESP_Status_Bremsdruck "No";
BA_ "GenSigSendType" SG_ 258 ESP_Anforderung_EPB "Cyclic";
BA_ "GenSigSwitchedByIgnition" SG_ 258 ESP_Anforderung_EPB "No";
BA_ "GenSigSendType" SG_ 258 ESP_ANB_CM_Rueckk_Umsetz "Cyclic";
BA_ "GenSigSwitchedByIgnition" SG_ 258 ESP_ANB_CM_Rueckk_Umsetz "No";
BA_ "GenSigSendType" SG_ 258 ESP_Konsistenz_ACC_Botschaft "Cyclic";
BA_ "GenSigSwitchedByIgnition" SG_ 258 ESP_Konsistenz_ACC_Botschaft "No";
BA_ "GenSigSendType" SG_ 258 ESP_Stillstandsphase_erschoepft "Cyclic";
BA_ "GenSigSwitchedByIgnition" SG_ 258 ESP_Stillstandsphase_erschoepft "No";
BA_ "GenSigSendType" SG_ 258 ESP_ZT_Rueckk_Umsetz "Cyclic";
BA_ "GenSigSwitchedByIgnition" SG_ 258 ESP_ZT_Rueckk_Umsetz "No";
BA_ "GenSigSendType" SG_ 258 ESP_Tuerkontakt_Fahrertuer "Cyclic";
BA_ "GenSigSwitchedByIgnition" SG_ 258 ESP_Tuerkontakt_Fahrertuer "No";
BA_ "GenSigSendType" SG_ 258 ESP_Abrutschen_Stillstand "Cyclic";
BA_ "GenSigSwitchedByIgnition" SG_ 258 ESP_Abrutschen_Stillstand "No";
BA_ "GenSigSendType" SG_ 258 ESP_Fahrer_tritt_ZBR_Schw "Cyclic";
BA_ "GenSigSwitchedByIgnition" SG_ 258 ESP_Fahrer_tritt_ZBR_Schw "No";
BA_ "GenSigSendType" SG_ 258 ESP_QBit_v_ref "Cyclic";
BA_ "GenSigStartValue" SG_ 258 ESP_QBit_v_ref 1;
BA_ "GenSigSwitchedByIgnition" SG_ 258 ESP_QBit_v_ref "No";
BA_ "GenSigSendType" SG_ 258 ESP_v_ref_Fahrtrichtung "Cyclic";
BA_ "GenSigSwitchedByIgnition" SG_ 258 ESP_v_ref_Fahrtrichtung "No";
BA_ "GenSigSendType" SG_ 258 ESC_Bremsdruckgradient "Cyclic";
BA_ "GenSigStartValue" SG_ 258 ESC_Bremsdruckgradient 254;
BA_ "GenSigSwitchedByIgnition" SG_ 258 ESC_Bremsdruckgradient "No";
BA_ "Fehlerwert" SG_ 258 ESC_Bremsdruckgradient 255;
BA_ "GenSigSendType" SG_ 258 ESP_v_ref "Cyclic";
BA_ "GenSigStartValue" SG_ 258 ESP_v_ref 4094;
BA_ "GenSigSwitchedByIgnition" SG_ 258 ESP_v_ref "No";
BA_ "Fehlerwert" SG_ 258 ESP_v_ref 4095;
BA_ "GenSigSendType" SG_ 258 ESC_Hydr_Fkt_aktiv "Cyclic";
BA_ "GenSigSwitchedByIgnition" SG_ 258 ESC_Hydr_Fkt_aktiv "No";
BA_ "GenSigSendType" SG_ 258 ESC_QBit_Fahrerbremswunsch "Cyclic";
BA_ "GenSigStartValue" SG_ 258 ESC_QBit_Fahrerbremswunsch 1;
BA_ "GenSigSwitchedByIgnition" SG_ 258 ESC_QBit_Fahrerbremswunsch "No";
BA_ "GenSigSendType" SG_ 258 ESC_Fahrerbremswunsch "Cyclic";
BA_ "GenSigStartValue" SG_ 258 ESC_Fahrerbremswunsch 100;
BA_ "GenSigSwitchedByIgnition" SG_ 258 ESC_Fahrerbremswunsch "No";
BA_ "Fehlerwert" SG_ 258 ESC_Fahrerbremswunsch 1023;
BA_ "GenSigSendType" SG_ 258 ESCGeneratorSollMoment "Cyclic";
BA_ "GenSigStartValue" SG_ 258 ESCGeneratorSollMoment 4094;
BA_ "GenSigSwitchedByIgnition" SG_ 258 ESCGeneratorSollMoment "No";
BA_ "Fehlerwert" SG_ 258 ESCGeneratorSollMoment 4095;
BA_ "GenSigSendType" SG_ 258 ESC_Raddruck_max "Cyclic";
BA_ "GenSigStartValue" SG_ 258 ESC_Raddruck_max 254;
BA_ "GenSigSwitchedByIgnition" SG_ 258 ESC_Raddruck_max "No";
BA_ "Fehlerwert" SG_ 258 ESC_Raddruck_max 255;
BA_ "GenSigSendType" SG_ 258 EPB_QBit_Pedalweg_Kuppl "Cyclic";
BA_ "GenSigStartValue" SG_ 258 EPB_QBit_Pedalweg_Kuppl 1;
BA_ "GenSigSwitchedByIgnition" SG_ 258 EPB_QBit_Pedalweg_Kuppl "No";
BA_ "GenSigSendType" SG_ 258 EPB_Freig_Verzoeg_Anf "Cyclic";
BA_ "GenSigSwitchedByIgnition" SG_ 258 EPB_Freig_Verzoeg_Anf "No";
BA_ "GenSigSendType" SG_ 258 EPB_Verzoeg_Anf "Cyclic";
BA_ "GenSigStartValue" SG_ 258 EPB_Verzoeg_Anf 166;
BA_ "GenSigSwitchedByIgnition" SG_ 258 EPB_Verzoeg_Anf "No";
BA_ "GenSigSendType" SG_ 258 EPB_Pedalweg_Kuppl "Cyclic";
BA_ "GenSigSwitchedByIgnition" SG_ 258 EPB_Pedalweg_Kuppl "No";
BA_ "Fehlerwert" SG_ 258 EPB_Pedalweg_Kuppl 255;
BA_ "GenSigSendType" SG_ 258 EPB_DAA_Randbed_erf "Cyclic";
BA_ "GenSigSwitchedByIgnition" SG_ 258 EPB_DAA_Randbed_erf "No";
BA_ "GenSigSendType" SG_ 258 EPB_Fehlerstatus_02 "Cyclic";
BA_ "GenSigSwitchedByIgnition" SG_ 258 EPB_Fehlerstatus_02 "No";
BA_ "GenSigSendType" SG_ 258 EPB_Schalterposition "Cyclic";
BA_ "GenSigSwitchedByIgnition" SG_ 258 EPB_Schalterposition "No";
BA_ "Fehlerwert" SG_ 258 EPB_Schalterposition 3;
BA_ "GenSigSendType" SG_ 258 EPB_QBit_Schalterpos "Cyclic";
BA_ "GenSigStartValue" SG_ 258 EPB_QBit_Schalterpos 1;
BA_ "GenSigSwitchedByIgnition" SG_ 258 EPB_QBit_Schalterpos "No";
BA_ "GenSigSendType" SG_ 258 EPB_Spannkraft "Cyclic";
BA_ "GenSigStartValue" SG_ 258 EPB_Spannkraft 30;
BA_ "GenSigSwitchedByIgnition" SG_ 258 EPB_Spannkraft "No";
BA_ "Fehlerwert" SG_ 258 EPB_Spannkraft 31;
BA_ "GenSigSendType" SG_ 258 EPB_Status_02 "Cyclic";
BA_ "GenSigStartValue" SG_ 258 EPB_Status_02 6;
BA_ "GenSigSwitchedByIgnition" SG_ 258 EPB_Status_02 "No";
BA_ "GenSigSendType" SG_ 258 EPB_Status "Cyclic";
BA_ "GenSigSwitchedByIgnition" SG_ 258 EPB_Status "No";
BA_ "GenSigSendType" SG_ 258 ESP_Status_Bremsentemp_02 "Cyclic";
BA_ "GenSigSwitchedByIgnition" SG_ 258 ESP_Status_Bremsentemp_02 "No";
VAL_ 514 DR_Aufbaubeschleunigung_HR 1021 "Sensor_nicht_verbaut" 1022 "Init" 1023 "Fehler";
VAL_ 514 DR_Aufbaubeschleunigung_VR 1021 "Sensor_nicht_verbaut" 1022 "Init" 1023 "Fehler";
VAL_ 514 DR_Aufbaubeschleunigung_VL 1021 "Sensor_nicht_verbaut" 1022 "Init" 1023 "Fehler";
VAL_ 514 DR_Aufbaubeschleunigung_HL 1021 "Sensor_nicht_verbaut" 1022 "Init" 1023 "Fehler";
VAL_ 514 DR_Funktionsstatus 0 "Init" 1 "Funktion_iO" 2 "Fehlerzustand_erkannt" 3 "keine_Inbetriebnahme";
VAL_ 514 DR_Drehwinkelsensortausch_VL 0 "Init";
VAL_ 514 DR_Drehwinkelsensortausch_VR 0 "Init";
VAL_ 514 DR_Drehwinkelsensortausch_HL 0 "Init";
VAL_ 514 DR_Drehwinkelsensortausch_HR 0 "Init";
VAL_ 514 DR_Drehwinkel_VL 4091 "nicht_verwendet" 4092 "nicht_verwendet" 4093 "Sensor_nicht_verbaut" 4094 "Init" 4095 "Fehler";
VAL_ 514 DR_Drehwinkel_VR 4091 "nicht_verwendet" 4092 "nicht_verwendet" 4093 "Sensor_nicht_verbaut" 4094 "Init" 4095 "Fehler";
VAL_ 514 DR_Drehwinkel_HL 4091 "nicht_verwendet" 4092 "nicht_verwendet" 4093 "Sensor_nicht_verbaut" 4094 "Init" 4095 "Fehler";
VAL_ 514 DR_Drehwinkel_HR 4091 "nicht_verwendet" 4092 "nicht_verwendet" 4093 "Sensor_nicht_verbaut" 4094 "Init" 4095 "Fehler";
VAL_ 1485 DC_Temperatur_Alarm 0 "kein_Fehler" 1 "Fehler";
VAL_ 1485 DC_Kl30c_Status 0 "Init" 1 "geschlossen" 2 "offen" 3 "Fehler";
VAL_ 1485 DC_Fehlerstatus 0 "Komponente_IO" 1 "Eingeschr_KompFkt_Entlad_defekt" 3 "Eingeschr_KompFkt_Interlock" 6 "Keine_Komponentenfunktion" 7 "Init";
VAL_ 1485 DC_Peakstrom_verfuegbar 0 "Peakstrom_nicht_verfuegbar" 1 "Peakstrom_verfuegbar";
VAL_ 1485 DC_Abregelung_Temperatur 0 "keine_Abregelung" 1 "Abregelung_Temp";
VAL_ 1485 DC_IstModus_02 0 "Standby" 1 "HV_On_Vorladen" 2 "Tiefsetzen" 3 "Hochsetzen" 4 "Pruefimpuls_12V" 5 "Fehler" 7 "Initialisierung";
VAL_ 1485 DC_Derating 0 "keine_Abregelung" 1 "Abregelung_Ursache_NV" 2 "Abregelung_Ursache_HV" 3 "Abregelung_Ursache_Temp" 4 "Abregelung_Ursache_Intern";
VAL_ 1485 DC_SollVolumenstrom 62 "Init" 63 "Fehler";
VAL_ 1485 DC_Status_Spgfreiheit_HV 0 "Init" 1 "HV_Komponente_spannungsfrei" 2 "HV_Komp_nicht_spannungsfrei" 3 "Fehler_nicht_spannungsfrei";
VAL_ 1485 DC_Temperatur 254 "Init" 255 "Fehler";
VAL_ 247 DC_Vorladung_Status 0 "nicht_abgeschlossen" 1 "abgeschlossen";
VAL_ 247 DC_Fehler_extern 0 "kein_Fehler" 1 "Fehler";
VAL_ 247 DC_Fehler_intern 0 "Init" 1 "interner_Fehler_erkannt";
VAL_ 247 DC_Status_Spgfreiheit 0 "Init" 1 "HV_Komponente_spannungsfrei" 2 "HV_Komp_nicht_spannungsfrei" 3 "Fehler_nicht_spannungsfrei";
VAL_ 247 DC_Status_EoHVL 0 "Init" 1 "Keine_offene_HV_Leitung_erkannt" 2 "offene_HV_Leitung_erkannt" 3 "Fehler";
VAL_ 247 DC_IstModus_02 0 "Standby" 1 "HV_On_Vorladen" 2 "Tiefsetzen" 3 "Hochsetzen" 4 "Pruefimpuls_12V" 5 "Fehler" 7 "Initialisierung";
VAL_ 247 DC_IstStrom_HV 1022 "Init" 1023 "Fehler";
VAL_ 247 DC_IstLeistung_HV 1022 "Init" 1023 "Fehler";
VAL_ 1714 DGN_Verlernzaehler 255 "ungültiger Zählerstand oder kein gültiger Fahrzyklus";
VAL_ 1714 KBI_Kilometerstand 1048574 "Init" 1048575 "Fehler";
VAL_ 1714 UH_Monat 0 "Init" 14 "reserviert" 15 "Fehler";
VAL_ 1714 UH_Tag 0 "Init";
VAL_ 1714 Vehicle_Driving_Cycle 0 "kein_Driving_Cycle_erkannt" 1 "Driving_Cycle_erkannt";
VAL_ 1714 Kombi_02_alt 0 "aktuell" 1 "veraltet";
VAL_ 1714 Uhrzeit_01_alt 0 "aktuell" 1 "veraltet";
VAL_ 851 DiETa_Status 0 "DiETa_betriebsbereit" 2 "Init" 3 "Fehler_oder_defekt";
VAL_ 851 DiETa_ResponseError 0 "normal" 1 "Fehler";
VAL_ 851 DiETa_Car 0 "Init_oder_nicht_verbaut" 1 "Taste_unbetaetigt" 2 "Taste_betaetigt" 3 "Fehler";
VAL_ 851 DiETa_Klima 0 "Init_oder_nicht_verbaut" 1 "Taste_unbetaetigt" 2 "Taste_betaetigt" 3 "Fehler";
VAL_ 851 DiETa_Mode 0 "Init_oder_nicht_verbaut" 1 "Taste_unbetaetigt" 2 "Taste_betaetigt" 3 "Fehler";
VAL_ 851 DiETa_Parken 0 "Init_oder_nicht_verbaut" 1 "Taste_unbetaetigt" 2 "Taste_betaetigt" 3 "Fehler";
VAL_ 851 DiETa_FSH_Taste 0 "Init_oder_nicht_verbaut" 1 "Taste_unbetaetigt" 2 "Taste_betaetigt" 3 "Fehler";
VAL_ 851 DiETa_HSH_Taste 0 "Init_oder_nicht_verbaut" 1 "Taste_unbetaetigt" 2 "Taste_betaetigt" 3 "Fehler";
VAL_ 851 DiETa_Warnblink_Taste 0 "Init_oder_nicht_verbaut" 1 "Taste_unbetaetigt" 2 "Taste_betaetigt" 3 "Fehler";
VAL_ 851 DiETa_FAS_Stufe 0 "Init_oder_nicht_verbaut" 1 "Taste_unbetaetigt" 2 "Taste_betaetigt" 3 "Fehler";
VAL_ 851 DiETa_PAO_ON_Status 0 "LED_Aus" 1 "LED_Ein" 2 "LED_Blinkt" 3 "LED_defekt";
VAL_ 851 DiETa_PAO_OFF_Status 0 "LED_Aus" 1 "LED_Ein" 2 "LED_Blinkt" 3 "LED_defekt";
VAL_ 851 DiETa_Defrost_Taste 0 "Init_oder_nicht_verbaut" 1 "Taste_unbetaetigt" 2 "Taste_betaetigt" 3 "Fehler";
VAL_ 851 DiETa_Lock_Unlock_Taste 0 "Init" 1 "Taste_unbetaetigt" 2 "Taste_betaetigt_unlock" 3 "Taste_betaetigt_lock" 4 "Reserviert" 5 "Reserviert" 6 "Reserviert" 7 "Fehler";
VAL_ 851 DiETa_Mode_roh 0 "Taste_unbetaetigt" 1 "Taste_betaetigt";
VAL_ 1520 DI_KL_58xd 254 "Init" 255 "Fehler";
VAL_ 1520 DI_KL_58xs 126 "Init" 127 "Fehler";
VAL_ 1520 DI_KL_58xt 126 "Init" 127 "Fehler";
VAL_ 1520 BCM1_Stellgroesse_Kl_58s 125 "Nicht_verbaut" 126 "Init" 127 "Fehler";
VAL_ 420 EA_Parken_beibehalten_HMS 0 "Parken_nicht_beibehalten" 1 "Parken_beibehalten" 2 "Init" 3 "Fehler";
VAL_ 420 EA_Ruckstaerke 0 "Keine_Anforderung" 1 "Schwach" 2 "Mittel" 3 "Stark";
VAL_ 420 EA_Warnruckprofil 0 "keine_Ruckanforderung" 1 "Profil_1" 2 "Profil_2" 3 "Profil_3" 4 "Profil_4" 5 "Profil_5" 6 "Profil_6" 7 "Profil_7";
VAL_ 420 EA_aktiv_laengs 0 "nicht_aktiv" 1 "aktiv_Vorstufe" 2 "aktiv_Hauptstufe";
VAL_ 420 EA_Funktionsstatus 0 "EA_INIT" 1 "EA_OFF" 2 "EA_STANDBY" 3 "EA_PHASE0_AKTIV" 4 "EA_PHASE1_AKTIV" 5 "EA_PHASE2_AKTIV" 6 "EA_PHASE3_AKTIV" 7 "EA_REVERSIBLER_FEHLER" 8 "EA_IRREVERSIBLER_FEHLER";
VAL_ 420 EA_Gurtstraffer_Anf 0 "Keine_Anforderung" 1 "Haptik_1" 2 "Haptik_2" 3 "Haptik_3";
VAL_ 420 EA_Anf_Prefill 0 "Prefill_nicht_aktivieren" 1 "Prefill_aktivieren";
VAL_ 420 EA_Anforderung_HMS 0 "keine_Anforderung" 1 "halten" 2 "parken" 3 "halten_Standby" 4 "anfahren" 5 "Loesen_ueber_Rampe" 6 "Parken_mit_P";
VAL_ 420 EA_Ruckfreigabe 0 "keine_Freigabe" 1 "Freigabe";
VAL_ 420 EA_01_Sendestatus 0 "EA_01_im_langsamen_Zyklus" 1 "EA_01_im_schnellen_Zyklus";
VAL_ 420 EA_Sollbeschleunigung 2046 "Neutralwert" 2047 "Fehler";
VAL_ 374 EBKV_Activate_Fallback_ESP 0 "Rueckfallebene_nicht_aktiv" 1 "Rueckfallebene_aktiv";
VAL_ 374 EBKV_Restdruckabsenkung 0 "RPR_Passive" 1 "RPR_Preload" 2 "RPR_Hold" 3 "RPR_Suction" 4 "RPR_HoldLowPressure" 5 "RPR_Abort";
VAL_ 374 EBKV_Status_02 0 "EBKV_nicht_initialisiert" 1 "EBKV_Fehler_Zustand_aus" 2 "EBKV_Diagnose" 3 "EBKV_nicht_belegt" 4 "EBKV_Standalone" 5 "EBKV_degradiert" 6 "EBKV_Nachlauf_degradiert" 7 "EBKV_bereit" 8 "EBKV_Ausfall_Rekukomponente" 9 "EBKV_nicht_belegt" 10 "EBKV_nicht_belegt" 11 "EBKV_nicht_belegt" 12 "EBKV_nicht_belegt" 13 "EBKV_nicht_belegt" 14 "EBKV_nicht_belegt" 15 "EBKV_nicht_belegt";
VAL_ 374 EBKV_Diagnose 0 "Diagnose_inaktiv" 1 "Diagnose_aktiv";
VAL_ 374 EBKV_Fahrer_bremst 0 "Fahrer_bremst_nicht_selbst" 1 "Fahrer_will_selbst_bremsen";
VAL_ 374 EBKV_QBit_Fahrer_bremst 0 "gueltiger_Wert" 1 "Ersatz_Init_oder_Fehlerwert";
VAL_ 374 EBKV_Fahrer_bremst_deutlich 0 "Fahrer_uebertritt_Schwelle_nicht" 1 "Fahrer_uebertritt_Schwelle";
VAL_ 374 EBKV_OBD_Status 0 "MIL_aus" 1 "MIL_ein";
VAL_ 374 EBKV_VMM_Sek_Notstopp_Status 0 "Init" 1 "Verfuegbar" 2 "Passiv_Ueberwachung" 3 "Aktiv_Ausgeloest" 4 "Systemkomponente_Defekt";
VAL_ 374 EBKV_Anforderung_HMS 0 "keine_Anforderung" 1 "halten" 2 "parken" 3 "halten_Standby" 4 "anfahren" 5 "Loesen_ueber_Rampe";
VAL_ 374 SBS_Anforderung_GE 0 "keine_Anforderung" 1 "P_einlegen";
VAL_ 374 EPB_Status_ext 0 "offen" 1 "geschlossen_Parken" 2 "teilgespannt_Halten" 3 "im_Lauf_oeffnen" 4 "im_Lauf_schliessen" 5 "tbd" 6 "Init" 7 "unbekannt";
VAL_ 374 EBKV_Bremspedalweg 0 "Init" 255 "Fehler";
VAL_ 374 EBKV_Kraftblending_Reserve 254 "Init" 255 "Fehler";
VAL_ 374 EBKV_Aussteuerdruck 251 "Aussteuerdruck_VKM_Start" 252 "Aussteuerdruck_Nachlauf_Phase1" 253 "Aussteuerdruck_Nachlauf_Phase2" 254 "Init" 255 "Fehler";
VAL_ 1603 KBI_Einheit_Datum 0 "Tag/Monat/Jahr" 1 "Monat/Tag/Jahr" 2 "Jahr/Monat/Tag" 3 "reserviert";
VAL_ 1603 KBI_Einheit_Druck 0 "Druckangabe in bar" 1 "Druckangabe in psi" 2 "Druckangabe in kPa" 3 "tbd.";
VAL_ 1603 KBI_Einheit_Streckenanz 0 "Kilometer" 1 "Meilen";
VAL_ 1603 KBI_MFA_v_Einheit_02 0 "kmh" 1 "mph";
VAL_ 1603 KBI_Einheit_Temp 0 "Grad Celsius °C" 1 "Grad Fahrenheit °F";
VAL_ 1603 KBI_Einheit_Uhrzeit 0 "24h" 1 " 12h AM/PM";
VAL_ 1603 KBI_Einheit_Verbrauch 0 "mpg UK" 1 "mpg USA" 2 "Liter/100km" 3 "km/Liter";
VAL_ 1603 KBI_Einheit_Volumen 0 "Liter" 1 "Gallonen UK" 2 "Gallonen USA" 3 "reserviert";
VAL_ 1603 KBI_Einheit_Verbrauch_elektr 0 "kWh_pro_100km" 1 "km_pro_kWh" 2 "kWh_pro_100mls" 3 "mls_pro_kWh" 4 "MPGe";
VAL_ 1603 KBI_Einheit_Tacho 0 "km/h" 1 "mph";
VAL_ 1603 KBI_Einheit_Verbrauch_Gas 0 "kg_per_100km" 1 "km_per_kg" 2 "m3_per_100km" 3 "km_per_m3" 4 "miles_per_lbs" 5 "miles_per_yard3" 6 "miles_per_kg" 7 "miles_per_m3" 8 "miles_per_gallon_equivalent_US";
VAL_ 1603 KBI_Einheit_Masse 0 "kg" 1 "lbs" 2 "reserviert";
VAL_ 192 EM1_Istmodus 0 "Standby" 1 "Momentenreg" 2 "Int_Drehzahlreg" 3 "Spannungsreg" 4 "Ext_Drehzahlreg" 5 "Inverter_Fehler" 6 "Kalibrierung" 7 "Sonderbremsbetrieb" 8 "Freilauf" 15 "Initialisierung";
VAL_ 192 EM1_IstMoment 4094 "Init" 4095 "Fehler";
VAL_ 192 EM1_Moment_AR_Eingriff 4094 "Init" 4095 "Fehler";
VAL_ 192 EM1_IstDrehzahl 32766 "Init" 32767 "Fehler";
VAL_ 192 EM1_AR_aktiv 0 "Init" 1 "Ruckeldaempfer_aktiv";
VAL_ 192 EM1_IstSpannung 4094 "Init" 4095 "Fehler";
VAL_ 192 EM1_Strom_HV 4094 "Init" 4095 "Fehler";
VAL_ 192 EM1_Max_Moment 2046 "Init" 2047 "Fehler";
VAL_ 192 EM1_ErwGrenzen_aktiv 0 "kein_extended_Range" 1 "extended_Range";
VAL_ 192 EM1_Min_Moment 2046 "Init" 2047 "Fehler";
VAL_ 192 EM1_Fehler_ElAntriebAbschaltung 0 "Init" 1 "Abschaltung";
VAL_ 192 EM1_Max_Moment_Lim 2046 "Init" 2047 "Fehler";
VAL_ 192 EM1_Fehler_Notabschaltung 0 "kein_Fehler" 1 "Fehler";
VAL_ 192 EM1_Min_Moment_Lim 2046 "Init" 2047 "Fehler";
VAL_ 192 EM1_Status_DrzEingriff 0 "kein_Eingriff" 1 "Eingriff_Max_Drehzahlregler" 2 "Eingriff_Min_Drehzahlregler" 3 "Fehler";
VAL_ 192 EM1_Mom_DrzEingriff 2046 "Init" 2047 "Fehler";
VAL_ 2463978673 EM1_Status_Spgfreiheit 0 "Init" 1 "HV_Komponente_spannungsfrei" 2 "HV_Komp_nicht_spannungsfrei" 3 "Fehler_nicht_spannungsfrei";
VAL_ 2463978673 EM1_Status_EoHVL 0 "Init" 1 "Keine_offene_HV_Leitung_erkannt" 2 "offene_HV_Leitung_erkannt" 3 "Fehler";
VAL_ 2463978673 EM1_Max_LeistungMech_Sockel 8190 "Init" 8191 "Fehler";
VAL_ 2463978673 EM1_Max_Moment_Sockel 2046 "Init" 2047 "Fehler";
VAL_ 2463978673 EM1_Min_LeistungMech_Sockel 8190 "Init" 8191 "Fehler";
VAL_ 2463978673 EM1_Min_Moment_Sockel 2046 "Init" 2047 "Fehler";
VAL_ 2463978673 EM1_PerfInd_MaxLeistung 1022 "Init";
VAL_ 2463978673 EM1_PerfInd_MaxMoment 1022 "Init";
VAL_ 2463978673 EM1_AnlernenElMotor_Anf 0 "kein_Diagnose_Request" 1 "Diagnose_Request";
VAL_ 2463978673 EM1_OBD_Lampe_Anf 0 "kein_MIL_Request" 1 "MIL_Request";
VAL_ 2463978673 EM1_Generator_Moment 1022 "Init" 1023 "Fehler";
VAL_ 2463978673 EM1_PerfInd_Temperatur 254 "Init";
VAL_ 2463978673 EM1_MaxZul_Drehzahl 254 "Init" 255 "Fehler";
VAL_ 2463978673 EM1_Min_Moment_Gesamt 2046 "Init" 2047 "Fehler";
VAL_ 2463978673 EM1_Fehlerlampe_Anf 0 "kein_Fehler" 1 "Anforderung_rote_Lampe";
VAL_ 2463978673 EM1_Max_Moment_Gesamt 2046 "Init" 2047 "Fehler";
VAL_ 2463978673 EM1_Warnlampe_Anf 0 "kein_Fehler" 1 "Anforderung_gelbe_Lampe";
VAL_ 2463978673 EM1_Rekuperation_Ueberlauf 0 "kein_Ueberlauf" 1 "Ueberlauf";
VAL_ 2463978673 EM1_Verbrauch_Ueberlauf 0 "kein_Ueberlauf" 1 "Ueberlauf";
VAL_ 2463978673 EM1_Fehler_AE 0 "kein_Fehler" 1 "Fehler_aktive_Entladung";
VAL_ 2463978673 EM1_Fehler_Leistungsred 0 "Init" 1 "Leistungsreduzierung";
VAL_ 2463978673 EM1_Fehler_ElAntriebFreilauf 0 "Init" 1 "Fehler__EM_im_Freilauf";
VAL_ 2463978673 EM1_PWR_SollVolumenstrom 62 "Init" 63 "Fehler";
VAL_ 2589283657 EM1_SollVorlauftemperatur 254 "Init" 255 "Fehler";
VAL_ 2589283657 EM1_Temperatur_EM 510 "Init" 511 "Fehler";
VAL_ 2589283657 EM1_EM_SollVolumenstrom 62 "Init" 63 "Fehler";
VAL_ 2589283657 EM1_Max_MechLeistung_nom 4094 "Init" 4095 "Fehler";
VAL_ 2589283657 EM1_Max_Moment_nom 1022 "Init" 1023 "Fehler";
VAL_ 2589283657 EM1_Temperatur_PWR 254 "Init" 255 "Fehler";
VAL_ 184 EM1_Freigabe_Info_WFS 0 "ungueltig" 1 "gueltig";
VAL_ 184 EM1_Sperr_Info_WFS 0 "nicht_gesperrt" 1 "gesperrt";
VAL_ 184 EM1_AR_aktiv 0 "Init" 1 "Ruckeldaempfer_aktiv";
VAL_ 184 EM1_Eta_Sys 510 "Init" 511 "Fehler";
VAL_ 184 EM1_IstStrom 2046 "Init" 2047 "Fehler";
VAL_ 184 EM1_Fehler_ElAntriebFreilauf_Anf 0 "Init" 1 "Fehler_EM_im_Freilauf";
VAL_ 184 EM1_Abregelung_Temperatur 0 "Init" 1 "Abregelung_Temperatur";
VAL_ 184 EM1_AnlernenElMotor_Anf 0 "kein_Diagnose_Request" 1 "Diagnose_Request";
VAL_ 184 EM1_Moment_HVVerbraucher 1023 "Init";
VAL_ 184 EM1_Freigabe_Verfallsinfo_WFS 0 "Aus" 1 "Ein";
VAL_ 184 EM1_Parken_WFS_Status 0 "Limitierung_Inaktiv" 1 "Limitierung_Aktiv" 2 "Abbruch";
VAL_ 184 EM1_HV_betriebsbereit 0 "Init" 1 "Ready_HV";
VAL_ 2527679712 EM1_RtmWarnKommunikation 0 "kein_Fehler" 1 "Fehler_Stufe_1" 2 "Fehler_Stufe_2" 3 "Fehler_Stufe_3" 4 "reserviert" 5 "reserviert" 6 "reserviert" 7 "reserviert";
VAL_ 2527679712 EM1_RtmWarnUeberdrehzahl 0 "kein_Fehler" 1 "Fehler_Stufe_1" 2 "Fehler_Stufe_2" 3 "Fehler_Stufe_3" 4 "reserviert" 5 "reserviert" 6 "reserviert" 7 "reserviert";
VAL_ 2527679712 EM1_RtmWarnUeberstrom 0 "kein_Fehler" 1 "Fehler_Stufe_1" 2 "Fehler_Stufe_2" 3 "Fehler_Stufe_3" 4 "reserviert" 5 "reserviert" 6 "reserviert" 7 "reserviert";
VAL_ 2527679712 EM1_RtmWarnTempEM 0 "kein_Fehler" 1 "Fehler_Stufe_1" 2 "Fehler_Stufe_2" 3 "Fehler_Stufe_3" 4 "reserviert" 5 "reserviert" 6 "reserviert" 7 "reserviert";
VAL_ 2527679712 EM1_RtmWarnTempPWR 0 "kein_Fehler" 1 "Fehler_Stufe_1" 2 "Fehler_Stufe_2" 3 "Fehler_Stufe_3" 4 "reserviert" 5 "reserviert" 6 "reserviert" 7 "reserviert";
VAL_ 193 EM2_Istmodus 0 "Standby" 1 "Momentenreg" 2 "Int_Drehzahlreg" 3 "Spannungsreg" 4 "Ext_Drehzahlreg" 5 "Inverter_Fehler" 6 "Kalibrierung" 7 "Sonderbremsbetrieb" 8 "Freilauf" 15 "Initialisierung";
VAL_ 193 EM2_IstMoment 4094 "Init" 4095 "Fehler";
VAL_ 193 EM2_Moment_AR_Eingriff 4094 "Init" 4095 "Fehler";
VAL_ 193 EM2_IstDrehzahl 32766 "Init" 32767 "Fehler";
VAL_ 193 EM2_AR_aktiv 0 "Init";
VAL_ 193 EM2_IstSpannung 4094 "Init" 4095 "Fehler";
VAL_ 193 EM2_Strom_HV 4094 "Init" 4095 "Fehler";
VAL_ 193 EM2_Max_Moment 2046 "Init" 2047 "Fehler";
VAL_ 193 EM2_ErwGrenzen_aktiv 0 "kein_extended_Range" 1 "extended_Range";
VAL_ 193 EM2_Min_Moment 2046 "Init" 2047 "Fehler";
VAL_ 193 EM2_Fehler_ElAntriebAbschaltung 0 "Init" 1 "Abschaltung";
VAL_ 193 EM2_Max_Moment_Lim 2046 "Init" 2047 "Fehler";
VAL_ 193 EM2_Fehler_Notabschaltung 0 "kein_Fehler" 1 "Fehler";
VAL_ 193 EM2_Min_Moment_Lim 2046 "Init" 2047 "Fehler";
VAL_ 193 EM2_Status_DrzEingriff 0 "kein_Eingriff" 1 "Eingriff_Max_Drehzahlregler" 2 "Eingriff_Min_Drehzahlregler" 3 "Fehler";
VAL_ 193 EM2_Mom_DrzEingriff 2046 "Init" 2047 "Fehler";
VAL_ 2463978674 EM2_Status_Spgfreiheit 0 "Init" 1 "HV_Komponente_spannungsfrei" 2 "HV_Komp_nicht_spannungsfrei" 3 "Fehler_nicht_spannungsfrei";
VAL_ 2463978674 EM2_Status_EoHVL 0 "Init" 1 "Keine_offene_HV_Leitung_erkannt" 2 "offene_HV_Leitung_erkannt" 3 "Fehler";
VAL_ 2463978674 EM2_Max_LeistungMech_Sockel 8190 "Init" 8191 "Fehler";
VAL_ 2463978674 EM2_Max_Moment_Sockel 2046 "Init" 2047 "Fehler";
VAL_ 2463978674 EM2_Min_LeistungMech_Sockel 8190 "Init" 8191 "Fehler";
VAL_ 2463978674 EM2_Min_Moment_Sockel 2046 "Init" 2047 "Fehler";
VAL_ 2463978674 EM2_PerfInd_MaxLeistung 1022 "Init";
VAL_ 2463978674 EM2_PerfInd_MaxMoment 1022 "Init";
VAL_ 2463978674 EM2_AnlernenElMotor_Anf 0 "kein_Diagnose_Request" 1 "Diagnose_Request";
VAL_ 2463978674 EM2_OBD_Lampe_Anf 0 "kein_MIL_Request" 1 "MIL_Request";
VAL_ 2463978674 EM2_Generator_Moment 1022 "Init" 1023 "Fehler";
VAL_ 2463978674 EM2_PerfInd_Temperatur 254 "Init";
VAL_ 2463978674 EM2_MaxZul_Drehzahl 254 "Init" 255 "Fehler";
VAL_ 2463978674 EM2_Min_Moment_Gesamt 2046 "Init" 2047 "Fehler";
VAL_ 2463978674 EM2_Fehlerlampe_Anf 0 "kein_Fehler" 1 "Anforderung_rote_Lampe";
VAL_ 2463978674 EM2_Max_Moment_Gesamt 2046 "Init" 2047 "Fehler";
VAL_ 2463978674 EM2_Warnlampe_Anf 0 "kein_Fehler" 1 "Anforderung_gelbe_Lampe";
VAL_ 2463978674 EM2_Rekuperation_Ueberlauf 0 "kein_Ueberlauf" 1 "Ueberlauf";
VAL_ 2463978674 EM2_Verbrauch_Ueberlauf 0 "kein_Ueberlauf" 1 "Ueberlauf";
VAL_ 2463978674 EM2_Fehler_AE 0 "kein_Fehler" 1 "Fehler_aktive_Entladung";
VAL_ 2463978674 EM2_Fehler_Leistungsred 0 "Init" 1 "Leistungsreduzierung";
VAL_ 2463978674 EM2_Fehler_ElAntriebFreilauf 0 "Init" 1 "Fehler__EM_im_Freilauf";
VAL_ 2463978674 EM2_PWR_SollVolumenstrom 62 "Init" 63 "Fehler";
VAL_ 2589283660 EM2_SollVorlauftemperatur 254 "Init" 255 "Fehler";
VAL_ 2589283660 EM2_Temperatur_EM 510 "Init" 511 "Fehler";
VAL_ 2589283660 EM2_EM_SollVolumenstrom 62 "Init" 63 "Fehler";
VAL_ 2589283660 EM2_Max_MechLeistung_nom 4094 "Init" 4095 "Fehler";
VAL_ 2589283660 EM2_Max_Moment_nom 1022 "Init" 1023 "Fehler";
VAL_ 2589283660 EM2_Temperatur_PWR 254 "Init" 255 "Fehler";
VAL_ 199 EM2_Freigabe_Info_WFS 0 "ungueltig" 1 "gueltig";
VAL_ 199 EM2_Sperr_Info_WFS 0 "nicht_gesperrt" 1 "gesperrt";
VAL_ 199 EM2_AR_aktiv 0 "Init";
VAL_ 199 EM2_Eta_Sys 510 "Init" 511 "Fehler";
VAL_ 199 EM2_IstStrom 2046 "Init" 2047 "Fehler";
VAL_ 199 EM2_Fehler_ElAntriebFreilauf_Anf 0 "Init" 1 "Fehler_EM_im_Freilauf";
VAL_ 199 EM2_Abregelung_Temperatur 0 "Init" 1 "Abregelung_Temperatur";
VAL_ 199 EM2_AnlernenElMotor_Anf 0 "kein_Diagnose_Request" 1 "Diagnose_Request";
VAL_ 199 EM2_Freigabe_Verfallsinfo_WFS 0 "Aus" 1 "Ein";
VAL_ 199 EM2_Parken_WFS_Status 0 "Limitierung_Inaktiv" 1 "Limitierung_Aktiv" 2 "Abbruch";
VAL_ 199 EM2_HV_betriebsbereit 0 "Init" 1 "Ready_HV";
VAL_ 2527679713 EM2_RtmWarnKommunikation 0 "kein_Fehler" 1 "Fehler_Stufe_1" 2 "Fehler_Stufe_2" 3 "Fehler_Stufe_3" 4 "reserviert" 5 "reserviert" 6 "reserviert" 7 "reserviert";
VAL_ 2527679713 EM2_RtmWarnUeberdrehzahl 0 "kein_Fehler" 1 "Fehler_Stufe_1" 2 "Fehler_Stufe_2" 3 "Fehler_Stufe_3" 4 "reserviert" 5 "reserviert" 6 "reserviert" 7 "reserviert";
VAL_ 2527679713 EM2_RtmWarnUeberstrom 0 "kein_Fehler" 1 "Fehler_Stufe_1" 2 "Fehler_Stufe_2" 3 "Fehler_Stufe_3" 4 "reserviert" 5 "reserviert" 6 "reserviert" 7 "reserviert";
VAL_ 2527679713 EM2_RtmWarnTempEM 0 "kein_Fehler" 1 "Fehler_Stufe_1" 2 "Fehler_Stufe_2" 3 "Fehler_Stufe_3" 4 "reserviert" 5 "reserviert" 6 "reserviert" 7 "reserviert";
VAL_ 2527679713 EM2_RtmWarnTempPWR 0 "kein_Fehler" 1 "Fehler_Stufe_1" 2 "Fehler_Stufe_2" 3 "Fehler_Stufe_3" 4 "reserviert" 5 "reserviert" 6 "reserviert" 7 "reserviert";
VAL_ 2589283649 EML_ReifenKorrFaktorHL 510 "Init" 511 "Fehler";
VAL_ 2589283649 EML_ReifenKorrFaktorHR 510 "Init" 511 "Fehler";
VAL_ 2589283649 EML_ReifenKorrFaktorVL 510 "Init" 511 "Fehler";
VAL_ 2589283649 EML_ReifenKorrFaktorVR 510 "Init" 511 "Fehler";
VAL_ 2589283649 EML_QBit_Reifenumfang 0 "gueltiger_Wert" 1 "Ersatz_Init_oder_Fehlerwert";
VAL_ 608 EML_AnzeigeGeschw 1022 "Init" 1023 "Fehler";
VAL_ 2527679687 EPS_ASM_Ereignis 0 "No_Event" 255 "ASM_Trigger";
VAL_ 2527679687 EPS_ASM_Zeitstempel 255 "INIT";
VAL_ 258 ESP_QBit_Gierrate 0 "gueltiger_Wert" 1 "Ersatz_Init_oder_Fehlerwert";
VAL_ 258 ESP_QBit_Laengsbeschl 0 "gueltiger_Wert" 1 "Ersatz_Init_oder_Fehlerwert";
VAL_ 258 ESP_QBit_Querb 0 "gueltiger_Wert" 1 "Ersatz_Init_oder_Fehlerwert";
VAL_ 258 ESP_Querbeschleunigung 255 "Fehler";
VAL_ 258 ESP_Laengsbeschl 1022 "Signal_nicht_vorhanden" 1023 "Fehler";
VAL_ 258 ESC_Motorstartverzoegerung 0 "Startfreigabe" 1 "Anforderung_Startverzoegerung";
VAL_ 258 ESC_SeitenwindAssistent_Eingriff 0 "Kein_SWA_Eingriff_und_Init" 1 "SWA_Eingriff_aktiv";
VAL_ 258 ESP_Anschleppstart_Freigabe 0 "kein_Schleppstart_oder_NotSchleppstart_erlaubt" 1 "NotSchleppstart_erlaubt" 2 "Schleppstart_und_NotSchleppStart_erlaubt";
VAL_ 258 ESC_Unterdruckmangel_erkannt 0 "kein_Unterdruckmangel_erkannt" 1 "Unterdruckmangel_erkannt";
VAL_ 258 ESP_Gierrate 16383 "Fehler";
VAL_ 258 ESP_VZ_Gierrate 0 "positiv" 1 "negativ";
VAL_ 258 ESP_Notbremsanzeige 0 "keine_Notbremsung_erkannt" 1 "Notbremsung_erkannt";
VAL_ 258 ESP_SpannungsAnf 0 "keine_Anforderung" 1 "Anforderung_Spannungswert_1";
VAL_ 258 ESP_PLA_Abbruch 0 "Init" 1 "Geschwindigkeitsueberschreitung" 2 "Falscher_PLA_Status" 3 "Deaktivierung_durch_Abbruch_Lenkung" 4 "PLA_Bremsanforderung_nach_Stillstand" 5 "Abbruch_durch_Kl15_aus" 6 "Abbruch_durch_FT_offen";
VAL_ 258 ESP_Status_ESP_PLA 8 "ESP_PLA_funktionsbereit" 0 "ESP_PLA_deaktiv" 9 "ESP_PLA_Neustart" 1 "ESP_PLA_Init" 10 "ESP_PLA_Abbruch" 2 "ESP_PLA_Fehler" 4 "ESP_PLA_aktivierbar" 6 "ESP_PLA_Bremse_aktiv";
VAL_ 258 ESP_QBit_Bremsdruck 0 "gueltiger_Wert" 1 "Ersatz_Init_oder_Fehlerwert";
VAL_ 258 ESP_QBit_Fahrer_bremst 0 "gueltiger_Wert" 1 "Ersatz_Init_oder_Fehlerwert";
VAL_ 258 ESP_Schwelle_Unterdruck 0 "kein_Signal" 1 "Unterdruck_kleiner_gleich_450_mbar" 2 "Unterdruck_groesser_450_mbar" 3 "Fehler_Unterdrucksensor";
VAL_ 258 ESP_Bremsdruck 1023 "Fehler";
VAL_ 258 ESP_Fahrer_bremst 0 "Bremsdruckschwelle_nicht_ueberschritten" 1 "Bremsdruckschwelle_ueberschritten";
VAL_ 258 ESP_Verz_TSK_aktiv 0 "TSK_Verzoegerung_inaktiv" 1 "TSK_Verzoegerung_aktiv";
VAL_ 258 ESP_Lenkeingriff_ADS 0 "kein_Lenkeingriff" 1 "stabilisierender_Lenkeingriff";
VAL_ 258 ESP_Konsistenz_TSK 0 "Botschaft_fuer_Verzoegerungsanforderung_konsistent" 1 "Botschaft_fuer_Verzoegerungsanforderung_nicht_konsistent";
VAL_ 258 ESP_Bremsruck_AWV2 0 "kein_Bremsruck_ausgefuehrt" 1 "Bremsruck_ausgefuehrt";
VAL_ 258 ESP_Konsistenz_AWV2 0 "Botschaft_fuer_AWV2_konsistent" 1 "Botschaft_fuer_AWV2_nicht_konsistent";
VAL_ 258 ECD_Fehler 0 "ECD_iO" 1 "ECD_Fehler";
VAL_ 258 ECD_nicht_verfuegbar 0 "ECD_Funktion_verfuegbar" 1 "ECD_Funktion_nicht_verfuegbar";
VAL_ 258 ESP_Status_Bremsentemp 0 "Bremse_nicht_ueberhitzt" 1 "Bremse_ueberhitzt";
VAL_ 258 ESP_Autohold_Standby 0 "Autohold_nicht_im_Standby" 1 "Autohold_im_Standby";
VAL_ 258 ESP_HDC_Standby 0 "HDC_Funktion_nicht_im_Standby" 1 "HDC_Funktion_im_Standby";
VAL_ 258 ESP_HBA_aktiv 0 "HBA_nicht_aktiv" 1 "HBA_aktiv";
VAL_ 258 ESP_Prefill_ausgeloest 0 "nicht_ausgeloest" 1 "Prefill_ausgeloest";
VAL_ 258 ESP_Rueckwaertsfahrt_erkannt 0 "keine_Rueckwaetsfahrt" 1 "Rueckwaertsfahrt_sicher_erkannt";
VAL_ 258 ESP_Status_Anfahrhilfe 0 "Aus" 1 "Ein";
VAL_ 258 ESP_HDC_aktiv 0 "inaktiv" 1 "aktiv";
VAL_ 258 ESP_StartStopp_Info 0 "Motorlauf_nicht_notwendig_(Stoppfreigabe)" 1 "Motoranlauf_nicht_zwingend_notwendig_(Stoppverbot,keine_Startanforderung)" 2 "Motoranlauf_zwingend_notwendig_(Startanforderung)" 3 "Systemfehler";
VAL_ 258 ESP_Eingr_HL 0 "kein_Eingriff" 1 "ESP_Eingriff_HL";
VAL_ 258 ESP_Eingr_HR 0 "kein_Eingriff" 1 "ESP_Eingriff_HR";
VAL_ 258 ESP_Eingr_VL 0 "kein_Eingriff" 1 "ESP_Eingriff_VL";
VAL_ 258 ESP_Eingr_VR 0 "kein_Eingriff" 1 "ESP_Eingriff_VR";
VAL_ 258 ESP_BKV_Unterdruck 0 "nicht_verbaut_oder_nicht_kodiert" 254 "Init" 255 "Fehler";
VAL_ 258 ESP_Autohold_aktiv 0 "Autohold_inaktiv" 1 "Autohold_aktiv";
VAL_ 258 ESP_FStatus_Anfahrhilfe 0 "kein_Fehler" 1 "Fehler";
VAL_ 258 ESP_Verz_EPB_aktiv 0 "nicht_aktiviert" 1 "aktiviert";
VAL_ 258 ECD_Bremslicht 0 "Aus" 1 "Ein";
VAL_ 258 ESP_Verzoeg_EPB_verf 0 "nicht_verfuegbar" 1 "System_verfuegbar";
VAL_ 258 ESP_Status_Bremsdruck 0 "Bremse_drucklos" 1 "mit_Bremsdruck";
VAL_ 258 ESP_Anforderung_EPB 0 "keine_Anforderung" 1 "Anforderung_Oeffnen" 2 "Anforderung_Schliessen" 3 "reserviert";
VAL_ 258 ESP_ANB_CM_Rueckk_Umsetz 0 "keine_Ausfuehrung" 1 "Ausfuehrung";
VAL_ 258 ESP_Konsistenz_ACC_Botschaft 0 "Botschaft_fuer_ACC_konsistent" 1 "Botschaft_fuer_ACC_nicht_konsistent";
VAL_ 258 ESP_Stillstandsphase_erschoepft 0 "sicheres_Halten_moeglich" 1 "kein_sicheres_Halten_moeglich";
VAL_ 258 ESP_ZT_Rueckk_Umsetz 0 "keine_Ausfuehrung" 1 "Ausfuehrung";
VAL_ 258 ESP_Tuerkontakt_Fahrertuer 0 "Schalter_geschlossen" 1 "Schalter_offen";
VAL_ 258 ESP_Abrutschen_Stillstand 0 "kein_Abrutschen_erkannt" 1 "Abrutschen_erkannt";
VAL_ 258 ESP_Fahrer_tritt_ZBR_Schw 0 "Fahrer_uebertritt_ZBR_Schwelle_nicht" 1 "Fahrer_uebertritt_ZBR_Schwelle";
VAL_ 258 ESP_QBit_v_ref 0 "gueltiger_Wert" 1 "Ersatz_Init_oder_Fehlerwert";
VAL_ 258 ESP_v_ref_Fahrtrichtung 0 "Fahrtrichtung_nicht_definiert" 1 "Vorwaerts" 2 "Rueckwaerts" 3 "Stillstand";
VAL_ 258 ESC_Bremsdruckgradient 251 "groesser_2500_bar_per_sec" 254 "Init" 255 "Fehler";
VAL_ 258 ESP_v_ref 4093 "Unterspannung" 4094 "Init" 4095 "Fehler";
VAL_ 258 ESC_Hydr_Fkt_aktiv 0 "keine_Aktivitaet" 1 "ESC_Druckaufbau_HBx_HFC_aktiv" 2 "Warnrucklevel_Summand_1" 3 "Warnrucklevel_Summand_3";
VAL_ 258 ESC_QBit_Fahrerbremswunsch 0 "gueltiger_Wert" 1 "Ersatz_Init_oder_Fehlerwert";
VAL_ 258 ESC_Fahrerbremswunsch 1023 "Fehler";
VAL_ 258 ESCGeneratorSollMoment 4094 "Init" 4095 "Fehler";
VAL_ 258 ESC_Raddruck_max 254 "Init" 255 "Fehler";
VAL_ 258 EPB_QBit_Pedalweg_Kuppl 0 "gültiger Wert" 1 "Ersatz-, Init- oder Fehlerwert";
VAL_ 258 EPB_Freig_Verzoeg_Anf 0 "nicht freigegeben" 1 "freigegeben";
VAL_ 258 EPB_Pedalweg_Kuppl 0 "Init" 255 "Fehler";
VAL_ 258 EPB_DAA_Randbed_erf 0 "Randbed_nicht_erfuellt" 1 "Randbed_erfuellt";
VAL_ 258 EPB_Fehlerstatus_02 0 "kein_Fehler" 1 "Fehler_ausserhalb_apply_release" 2 "Fehler_einseitig_apply_release" 3 "Fehler_beidseitig_apply_release";
VAL_ 258 EPB_Schalterposition 0 "keine Fahreranforderung" 1 "Fahreranforderung Öffnen" 2 "Fahreranforderung Schließen" 3 "Fehler";
VAL_ 258 EPB_QBit_Schalterpos 0 "gültiger Wert (volle Funktion)" 1 " Ersatz-, Init- oder Fehlerwert (Schalter ausser Funktion)";
VAL_ 258 EPB_Spannkraft 30 "Init" 31 "Fehler";
VAL_ 258 EPB_Status_02 0 "offen" 1 "geschlossen_Parken" 2 "teilgespannt_Halten" 3 "im_Lauf_oeffnen" 4 "im_Lauf_schliessen" 5 "tbd" 6 "Init" 7 "unbekannt";
VAL_ 258 EPB_Status 0 "offen" 1 "Bremse_geschl_(Spannkraft_voll/reduziert)" 2 "Aktuator_im_Lauf" 3 "Fehler_oder_unbekannt";
VAL_ 258 ESP_Status_Bremsentemp_02 0 "nicht_erhoeht" 1 "Schwelle_1" 2 "Schwelle_2";
